VERSION "dbc-export 1 2026.26.6.5"

NS_ :

BS_:

BU_: ADSP APB APP APS APSB BB BMS CC CMP CMPD CP DAS DI DIF DIR DPB EPAS3P EPAS3S EPASTP EPASTS EPBL EPBR ESP EVSE FC GTW HCML HCMR HVP IBST ICR IDB LS OCS1P PARK PCS PCS2 PM PMF PMR PNCD PTC RADC RCM RCM2 RCM3 RCU SCCM SCM SCS SDCR TAS TCU TCU2 TPMS TRCM UI UIS UMC USM V2G VC VCBATT VCBATT0 VCBATT1 VCBATT2 VCCC VCFRONT VCFRONT1 VCFRONT2 VCLEFT VCRIGHT VCSEAT2L VCSEAT2R VCSEC VEH

BO_ 881 RCM_alertMatrix: 8 RCM
 SG_ RCM_matrixIndex M : 0|4@1+ (1,0) [0|15] "" Vector__XXX
 SG_ RCM_a000_crashDetected m0 : 4|1@1+ (1,0) [0|1] "" Vector__XXX
 SG_ RCM_a001_nearDeploy m0 : 5|1@1+ (1,0) [0|1] "" Vector__XXX
 SG_ RCM_a002_airbagsNotArmed m0 : 6|1@1+ (1,0) [0|1] "" Vector__XXX
 SG_ RCM_a003_warningIndicator m0 : 7|1@1+ (1,0) [0|1] "" Vector__XXX
 SG_ RCM_a004_internalFault m0 : 8|1@1+ (1,0) [0|1] "" Vector__XXX
 SG_ RCM_a005_crcError m0 : 9|1@1+ (1,0) [0|1] "" Vector__XXX
 SG_ RCM_a006_batteryVoltageRange m0 : 10|1@1+ (1,0) [0|1] "" Vector__XXX
 SG_ RCM_a007_powerSupplyExternal m0 : 11|1@1+ (1,0) [0|1] "" Vector__XXX
 SG_ RCM_a008_powerSupplyInternal m0 : 12|1@1+ (1,0) [0|1] "" Vector__XXX
 SG_ RCM_a009_reprogramLimit m0 : 13|1@1+ (1,0) [0|1] "" Vector__XXX
 SG_ RCM_a010_scmDisabled m0 : 14|1@1+ (1,0) [0|1] "" Vector__XXX
 SG_ RCM_a011_eepromDataLocked m0 : 15|1@1+ (1,0) [0|1] "" Vector__XXX
 SG_ RCM_a012_vinStorage m0 : 16|1@1+ (1,0) [0|1] "" Vector__XXX
 SG_ RCM_a013_driverOrientation m0 : 17|1@1+ (1,0) [0|1] "" Vector__XXX
 SG_ RCM_a014_driverABStage1 m0 : 18|1@1+ (1,0) [0|1] "" Vector__XXX
 SG_ RCM_a015_driverABStage2 m0 : 19|1@1+ (1,0) [0|1] "" Vector__XXX
 SG_ RCM_a016_passABStage1 m0 : 20|1@1+ (1,0) [0|1] "" Vector__XXX
 SG_ RCM_a017_passABStage2 m0 : 21|1@1+ (1,0) [0|1] "" Vector__XXX
 SG_ RCM_a018_passengerActiveVent m0 : 22|1@1+ (1,0) [0|1] "" Vector__XXX
 SG_ RCM_a019_pretenShldrFrontLeft m0 : 23|1@1+ (1,0) [0|1] "" Vector__XXX
 SG_ RCM_a020_pretenShldFrontRight m0 : 24|1@1+ (1,0) [0|1] "" Vector__XXX
 SG_ RCM_a021_pretenLapFrontLeft m0 : 25|1@1+ (1,0) [0|1] "" Vector__XXX
 SG_ RCM_a022_pretenLapFrontRight m0 : 26|1@1+ (1,0) [0|1] "" Vector__XXX
 SG_ RCM_a023_loadLimiterLeftSide m0 : 27|1@1+ (1,0) [0|1] "" Vector__XXX
 SG_ RCM_a024_loadLimiterRightSide m0 : 28|1@1+ (1,0) [0|1] "" Vector__XXX
 SG_ RCM_a025_kneeABDriver m0 : 29|1@1+ (1,0) [0|1] "" Vector__XXX
 SG_ RCM_a026_kneeABFrontPassenger m0 : 30|1@1+ (1,0) [0|1] "" Vector__XXX
 SG_ RCM_a027_sideAB1stRowLeft m0 : 31|1@1+ (1,0) [0|1] "" Vector__XXX
 SG_ RCM_a028_sideAB1stRowRight m0 : 32|1@1+ (1,0) [0|1] "" Vector__XXX
 SG_ RCM_a029_driverABActiveVent m0 : 33|1@1+ (1,0) [0|1] "" Vector__XXX
 SG_ RCM_a030_farSideInboardAirbag m0 : 34|1@1+ (1,0) [0|1] "" Vector__XXX
 SG_ RCM_a031_frontCenterAirbag m0 : 35|1@1+ (1,0) [0|1] "" Vector__XXX
 SG_ RCM_a032_curtainABLeft m0 : 36|1@1+ (1,0) [0|1] "" Vector__XXX
 SG_ RCM_a033_curtainABRight m0 : 37|1@1+ (1,0) [0|1] "" Vector__XXX
 SG_ RCM_a034_preten2ndRowLeft m0 : 38|1@1+ (1,0) [0|1] "" Vector__XXX
 SG_ RCM_a035_preten2ndRowRight m0 : 39|1@1+ (1,0) [0|1] "" Vector__XXX
 SG_ RCM_a036_curAB2ndRowLeft m0 : 40|1@1+ (1,0) [0|1] "" Vector__XXX
 SG_ RCM_a037_curAB2ndRowRight m0 : 41|1@1+ (1,0) [0|1] "" Vector__XXX
 SG_ RCM_a038_unusedA m0 : 42|1@1+ (1,0) [0|1] "" Vector__XXX
 SG_ RCM_a039_unusedB m0 : 43|1@1+ (1,0) [0|1] "" Vector__XXX
 SG_ RCM_a040_hoodActuatorRight m0 : 44|1@1+ (1,0) [0|1] "" Vector__XXX
 SG_ RCM_a041_hoodActuatorLeft m0 : 45|1@1+ (1,0) [0|1] "" Vector__XXX
 SG_ RCM_a042_ens1Line m0 : 46|1@1+ (1,0) [0|1] "" Vector__XXX
 SG_ RCM_a043_ens2Line m0 : 47|1@1+ (1,0) [0|1] "" Vector__XXX
 SG_ RCM_a044_upFrontSensorLeft m0 : 48|1@1+ (1,0) [0|1] "" Vector__XXX
 SG_ RCM_a045_upFrontSensorRight m0 : 49|1@1+ (1,0) [0|1] "" Vector__XXX
 SG_ RCM_a046_sideAccelBPillarLeft m0 : 50|1@1+ (1,0) [0|1] "" Vector__XXX
 SG_ RCM_a047_sideAccelBPillarRight m0 : 51|1@1+ (1,0) [0|1] "" Vector__XXX
 SG_ RCM_a048_sideAccelCPillarLeft m0 : 52|1@1+ (1,0) [0|1] "" Vector__XXX
 SG_ RCM_a049_sideAccelCPillarRight m0 : 53|1@1+ (1,0) [0|1] "" Vector__XXX
 SG_ RCM_a050_upFrontSensorCenter m0 : 54|1@1+ (1,0) [0|1] "" Vector__XXX
 SG_ RCM_a051_pressureFrontLftDoor m0 : 55|1@1+ (1,0) [0|1] "" Vector__XXX
 SG_ RCM_a052_pressureFrontRtDoor m0 : 56|1@1+ (1,0) [0|1] "" Vector__XXX
 SG_ RCM_a053_pressurePedProLeft m0 : 57|1@1+ (1,0) [0|1] "" Vector__XXX
 SG_ RCM_a054_pressurePedProRight m0 : 58|1@1+ (1,0) [0|1] "" Vector__XXX
 SG_ RCM_a055_inertialMeasurement m0 : 59|1@1+ (1,0) [0|1] "" Vector__XXX
 SG_ RCM_a056_passengerFrontOCS m0 : 60|1@1+ (1,0) [0|1] "" Vector__XXX
 SG_ RCM_a057_driverOCS m0 : 61|1@1+ (1,0) [0|1] "" Vector__XXX
 SG_ RCM_a058_buckle1stRowLeft m0 : 62|1@1+ (1,0) [0|1] "" Vector__XXX
 SG_ RCM_a059_buckle1stRowRight m0 : 63|1@1+ (1,0) [0|1] "" Vector__XXX
 SG_ RCM_a060_stpsLeft m1 : 4|1@1+ (1,0) [0|1] "" Vector__XXX
 SG_ RCM_a061_stpsRight m1 : 5|1@1+ (1,0) [0|1] "" Vector__XXX
 SG_ RCM_a062_alrSwitch m1 : 6|1@1+ (1,0) [0|1] "" Vector__XXX
 SG_ RCM_a063_sbsw2ndRowRight m1 : 7|1@1+ (1,0) [0|1] "" Vector__XXX
 SG_ RCM_a064_hardwareCodingPin1 m1 : 8|1@1+ (1,0) [0|1] "" Vector__XXX
 SG_ RCM_a065_driverOrientConfigPin m1 : 9|1@1+ (1,0) [0|1] "" Vector__XXX
 SG_ RCM_a066_seatBackSw2ndRowLeft m1 : 10|1@1+ (1,0) [0|1] "" Vector__XXX
 SG_ RCM_a067_comCANInitFailure m1 : 11|1@1+ (1,0) [0|1] "" Vector__XXX
 SG_ RCM_a068_comChassisBusOff m1 : 12|1@1+ (1,0) [0|1] "" Vector__XXX
 SG_ RCM_a069_comCHCANPH7 m1 : 13|1@1+ (1,0) [0|1] "" Vector__XXX
 SG_ RCM_a070_comCHCANPH8 m1 : 14|1@1+ (1,0) [0|1] "" Vector__XXX
 SG_ RCM_a071_comCHCANPH9 m1 : 15|1@1+ (1,0) [0|1] "" Vector__XXX
 SG_ RCM_a072_comUnused m1 : 16|1@1+ (1,0) [0|1] "" Vector__XXX
 SG_ RCM_a073_comCHCANPH4 m1 : 17|1@1+ (1,0) [0|1] "" Vector__XXX
 SG_ RCM_a074_comCHCANPH5 m1 : 18|1@1+ (1,0) [0|1] "" Vector__XXX
 SG_ RCM_a075_comCHCANPH6 m1 : 19|1@1+ (1,0) [0|1] "" Vector__XXX
 SG_ RCM_a076_comEPBLStatus m1 : 20|1@1+ (1,0) [0|1] "" Vector__XXX
 SG_ RCM_a077_comEPBRStatus m1 : 21|1@1+ (1,0) [0|1] "" Vector__XXX
 SG_ RCM_a078_comOCS1PStatus m1 : 22|1@1+ (1,0) [0|1] "" Vector__XXX
 SG_ RCM_a079_comOCS1DStatus m1 : 23|1@1+ (1,0) [0|1] "" Vector__XXX
 SG_ RCM_a080_comGTWACS m1 : 24|1@1+ (1,0) [0|1] "" Vector__XXX
 SG_ RCM_a081_comVCFRONTLVPwr m1 : 25|1@1+ (1,0) [0|1] "" Vector__XXX
 SG_ RCM_a082_comUIodo m1 : 26|1@1+ (1,0) [0|1] "" Vector__XXX
 SG_ RCM_a083_comGTWCarState m1 : 27|1@1+ (1,0) [0|1] "" Vector__XXX
 SG_ RCM_a084_comTPMSStatus m1 : 28|1@1+ (1,0) [0|1] "" Vector__XXX
 SG_ RCM_a085_comGTWCarConfig m1 : 29|1@1+ (1,0) [0|1] "" Vector__XXX
 SG_ RCM_a086_comVINMIA m1 : 30|1@1+ (1,0) [0|1] "" Vector__XXX
 SG_ RCM_a087_comCANSilent m1 : 31|1@1+ (1,0) [0|1] "" Vector__XXX
 SG_ RCM_a088_comCHCANPH2 m1 : 32|1@1+ (1,0) [0|1] "" Vector__XXX
 SG_ RCM_a089_comCHCANPH3 m1 : 33|1@1+ (1,0) [0|1] "" Vector__XXX
 SG_ RCM_a090_comPartyBusOff m1 : 34|1@1+ (1,0) [0|1] "" Vector__XXX
 SG_ RCM_a091_comEPAS3PsysStatus m1 : 35|1@1+ (1,0) [0|1] "" Vector__XXX
 SG_ RCM_a092_comDASISF m1 : 36|1@1+ (1,0) [0|1] "" Vector__XXX
 SG_ RCM_a093_comVCLEFTStatus m1 : 37|1@1+ (1,0) [0|1] "" Vector__XXX
 SG_ RCM_a094_comVCRIGHTStatus m1 : 38|1@1+ (1,0) [0|1] "" Vector__XXX
 SG_ RCM_a095_comESPstatus m1 : 39|1@1+ (1,0) [0|1] "" Vector__XXX
 SG_ RCM_a096_comESPwheelSpeeds m1 : 40|1@1+ (1,0) [0|1] "" Vector__XXX
 SG_ RCM_a097_comDIspeed m1 : 41|1@1+ (1,0) [0|1] "" Vector__XXX
 SG_ RCM_a098_comDIchassisControl m1 : 42|1@1+ (1,0) [0|1] "" Vector__XXX
 SG_ RCM_a099_comDItorque m1 : 43|1@1+ (1,0) [0|1] "" Vector__XXX
 SG_ RCM_a100_comDIsystemStatus m1 : 44|1@1+ (1,0) [0|1] "" Vector__XXX
 SG_ RCM_a101_idfSystem m1 : 45|1@1+ (1,0) [0|1] "" Vector__XXX
 SG_ RCM_a102_imuYawR8OffstCompLim m1 : 46|1@1+ (1,0) [0|1] "" Vector__XXX
 SG_ RCM_a103_imuPtchR8OffstCompLim m1 : 47|1@1+ (1,0) [0|1] "" Vector__XXX
 SG_ RCM_a104_imuRollR8OffstCompLim m1 : 48|1@1+ (1,0) [0|1] "" Vector__XXX
 SG_ RCM_a105_imuLongAccOffstCompLim m1 : 49|1@1+ (1,0) [0|1] "" Vector__XXX
 SG_ RCM_a106_imuLatAccOffstCompLim m1 : 50|1@1+ (1,0) [0|1] "" Vector__XXX
 SG_ RCM_a107_imuVertAccOffstCompLim m1 : 51|1@1+ (1,0) [0|1] "" Vector__XXX
 SG_ RCM_a108_crashAlgoWakeup m1 : 52|1@1+ (1,0) [0|1] "" Vector__XXX
 SG_ RCM_a109_abuseImmunity m1 : 53|1@1+ (1,0) [0|1] "" Vector__XXX
 SG_ RCM_a110_factoryMode m1 : 54|1@1+ (1,0) [0|1] "" Vector__XXX
 SG_ RCM_a111_diagnosticsEnabled m1 : 55|1@1+ (1,0) [0|1] "" Vector__XXX
 SG_ RCM_a112_imuYawRate m1 : 56|1@1+ (1,0) [0|1] "" Vector__XXX
 SG_ RCM_a113_imuPitchRate m1 : 57|1@1+ (1,0) [0|1] "" Vector__XXX
 SG_ RCM_a114_imuRollRate m1 : 58|1@1+ (1,0) [0|1] "" Vector__XXX
 SG_ RCM_a115_imuLinearAcceleration m1 : 59|1@1+ (1,0) [0|1] "" Vector__XXX
 SG_ RCM_a116_imuLateralAcceleration m1 : 60|1@1+ (1,0) [0|1] "" Vector__XXX
 SG_ RCM_a117_imuVerticalAcceleration m1 : 61|1@1+ (1,0) [0|1] "" Vector__XXX
 SG_ RCM_a118_imuInPlaneAcceleration m1 : 62|1@1+ (1,0) [0|1] "" Vector__XXX

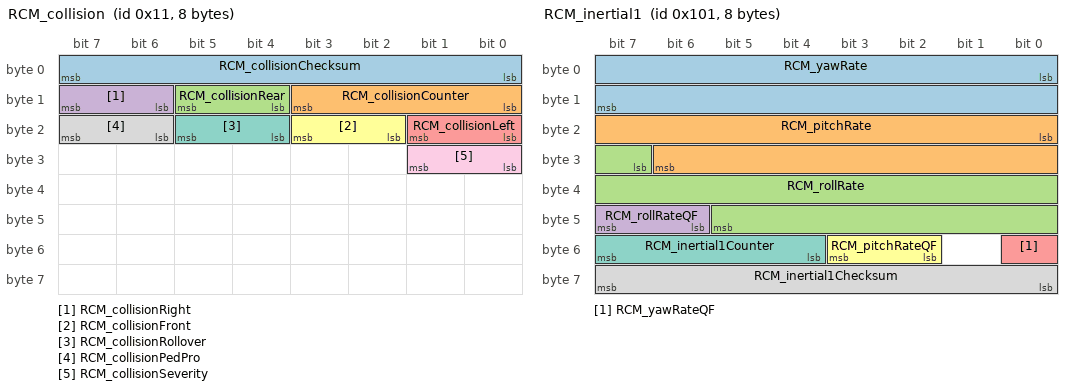
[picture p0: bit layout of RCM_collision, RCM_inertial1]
BO_ 17 RCM_collision: 8 RCM
 SG_ RCM_collisionChecksum : 0|8@1+ (1,0) [0|255] "" Vector__XXX
 SG_ RCM_collisionCounter : 8|4@1+ (1,0) [0|15] "" Vector__XXX
 SG_ RCM_collisionRear : 12|2@1+ (1,0) [0|3] "" Vector__XXX
 SG_ RCM_collisionRight : 14|2@1+ (1,0) [0|3] "" Vector__XXX
 SG_ RCM_collisionLeft : 16|2@1+ (1,0) [0|3] "" Vector__XXX
 SG_ RCM_collisionFront : 18|2@1+ (1,0) [0|3] "" Vector__XXX
 SG_ RCM_collisionRollover : 20|2@1+ (1,0) [0|3] "" Vector__XXX
 SG_ RCM_collisionPedPro : 22|2@1+ (1,0) [0|3] "" Vector__XXX
 SG_ RCM_collisionSeverity : 24|2@1+ (1,0) [0|3] "" Vector__XXX

BO_ 257 RCM_inertial1: 8 RCM
 SG_ RCM_yawRate : 0|16@1- (0.0001,0) [-3.2766|3.2766] "rad/s" Vector__XXX
 SG_ RCM_pitchRate : 16|15@1- (0.00025,0) [-4.096|4.09575] "rad/s" Vector__XXX
 SG_ RCM_rollRate : 31|15@1- (0.00025,0) [-4.096|4.09575] "rad/s" Vector__XXX
 SG_ RCM_rollRateQF : 46|2@1+ (1,0) [0|3] "" Vector__XXX
 SG_ RCM_yawRateQF : 48|1@1+ (1,0) [0|1] "" Vector__XXX
 SG_ RCM_pitchRateQF : 50|2@1+ (1,0) [0|3] "" Vector__XXX
 SG_ RCM_inertial1Counter : 52|4@1+ (1,0) [0|15] "" Vector__XXX
 SG_ RCM_inertial1Checksum : 56|8@1+ (1,0) [0|255] "" Vector__XXX

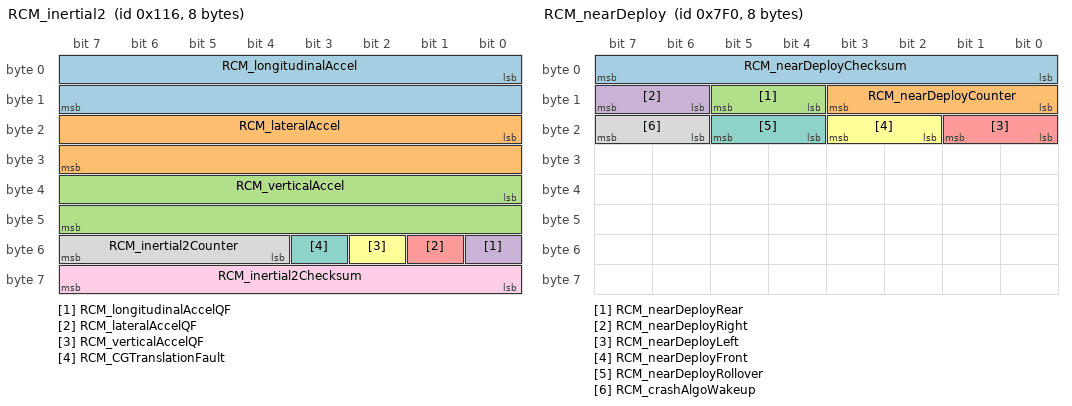
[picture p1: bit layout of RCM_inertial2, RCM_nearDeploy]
BO_ 278 RCM_inertial2: 8 RCM
 SG_ RCM_longitudinalAccel : 0|16@1- (0.00125,0) [-40.9575|40.9575] "m/s^2" Vector__XXX
 SG_ RCM_lateralAccel : 16|16@1- (0.00125,0) [-40.9575|40.9575] "m/s^2" Vector__XXX
 SG_ RCM_verticalAccel : 32|16@1- (0.00125,0) [-40.9575|39.2] "m/s^2" Vector__XXX
 SG_ RCM_longitudinalAccelQF : 48|1@1+ (1,0) [0|1] "" Vector__XXX
 SG_ RCM_lateralAccelQF : 49|1@1+ (1,0) [0|1] "" Vector__XXX
 SG_ RCM_verticalAccelQF : 50|1@1+ (1,0) [0|1] "" Vector__XXX
 SG_ RCM_CGTranslationFault : 51|1@1+ (1,0) [0|1] "" Vector__XXX
 SG_ RCM_inertial2Counter : 52|4@1+ (1,0) [0|15] "" Vector__XXX
 SG_ RCM_inertial2Checksum : 56|8@1+ (1,0) [0|255] "" Vector__XXX

BO_ 849 RCM_info: 8 RCM
 SG_ RCM_infoIndex M : 0|8@1+ (1,0) [0|255] "" Vector__XXX
 SG_ RCM_infoBuildType m10 : 8|8@1+ (1,0) [0|255] "" Vector__XXX
 SG_ RCM_infoComponentID m10 : 48|16@1+ (1,0) [0|65535] "" Vector__XXX
 SG_ RCM_infoPcbaID m11 : 16|8@1+ (1,0) [0|255] "" Vector__XXX
 SG_ RCM_infoAssemblyID m11 : 24|8@1+ (1,0) [0|255] "" Vector__XXX
 SG_ RCM_infoUsageID m11 : 32|16@1+ (1,0) [0|65535] "" Vector__XXX
 SG_ RCM_infoApplicationCRC m13 : 32|32@1+ (1,0) [0|4294967295] "" Vector__XXX
 SG_ RCM_infoBootUdsProtoVersion m20 : 8|8@1+ (1,0) [0|255] "" Vector__XXX
 SG_ RCM_infoBootloaderCRC m20 : 32|32@1+ (1,0) [0|4294967295] "" Vector__XXX
 SG_ RCM_infoAlgoCalID m22 : 8|8@1+ (1,0) [0|255] "" Vector__XXX
 SG_ RCM_infoVariantCRC m22 : 32|32@1+ (1,0) [0|4294967295] "" Vector__XXX

BO_ 2032 RCM_nearDeploy: 8 RCM
 SG_ RCM_nearDeployChecksum : 0|8@1+ (1,0) [0|255] "" Vector__XXX
 SG_ RCM_nearDeployCounter : 8|4@1+ (1,0) [0|15] "" Vector__XXX
 SG_ RCM_nearDeployRear : 12|2@1+ (1,0) [0|3] "" Vector__XXX
 SG_ RCM_nearDeployRight : 14|2@1+ (1,0) [0|3] "" Vector__XXX
 SG_ RCM_nearDeployLeft : 16|2@1+ (1,0) [0|3] "" Vector__XXX
 SG_ RCM_nearDeployFront : 18|2@1+ (1,0) [0|3] "" Vector__XXX
 SG_ RCM_nearDeployRollover : 20|2@1+ (1,0) [0|3] "" Vector__XXX
 SG_ RCM_crashAlgoWakeup : 22|2@1+ (1,0) [0|3] "" Vector__XXX

BO_ 529 RCM_status: 8 RCM
 SG_ RCM_statusChecksum : 0|8@1+ (1,0) [0|255] "" Vector__XXX
 SG_ RCM_statusCounter : 8|4@1+ (1,0) [0|15] "" Vector__XXX
 SG_ RCM_armStatus : 12|2@1+ (1,0) [0|3] "" Vector__XXX
 SG_ RCM_warningIndicatorState : 14|2@1+ (1,0) [0|3] "" Vector__XXX
 SG_ RCM_passAirbagIndicatorRequest : 16|2@1+ (1,0) [0|3] "" Vector__XXX
 SG_ RCM_airbagCutoffStatus : 18|2@1+ (1,0) [0|3] "" Vector__XXX
 SG_ RCM_alrSwitchStatus : 20|2@1+ (1,0) [0|3] "" Vector__XXX
 SG_ RCM_vinLearnFlag : 22|2@1+ (1,0) [0|3] "" Vector__XXX
 SG_ RCM_seatTrackPositionDrvr : 24|2@1+ (1,0) [0|3] "" Vector__XXX
 SG_ RCM_seatTrackPositionPass : 26|2@1+ (1,0) [0|3] "" Vector__XXX
 SG_ RCM_edr1State : 28|2@1+ (1,0) [0|3] "" Vector__XXX
 SG_ RCM_edr2State : 30|2@1+ (1,0) [0|3] "" Vector__XXX
 SG_ RCM_keepPowerReason : 32|4@1+ (1,0) [0|15] "" Vector__XXX
 SG_ RCM_imuOffsetLearnState : 36|2@1+ (1,0) [0|3] "" Vector__XXX
 SG_ RCM_edr3State : 38|2@1+ (1,0) [0|3] "" Vector__XXX
 SG_ RCM_driverOrientationInitStatus : 40|3@1+ (1,0) [0|7] "" Vector__XXX
 SG_ RCM_occupantClassificationSource : 43|1@1+ (1,0) [0|1] "" Vector__XXX
 SG_ RCM_pedProEDR1State : 44|2@1+ (1,0) [0|3] "" Vector__XXX
 SG_ RCM_pedProEDR2State : 46|2@1+ (1,0) [0|3] "" Vector__XXX

BO_ 1471 RCU_alertLog: 8 RCU
 SG_ RCU_alertID M : 0|7@1+ (1,0) [0|127] "" Vector__XXX
 SG_ RCU_alertState : 15|1@1+ (1,0) [0|1] "" Vector__XXX
 SG_ RCU_a010_sensorPowerSupply m10 : 16|1@1+ (1,0) [0|1] "" Vector__XXX
 SG_ RCU_a010_sensorHardware m10 : 17|1@1+ (1,0) [0|1] "" Vector__XXX
 SG_ RCU_a010_sensorSignal m10 : 18|1@1+ (1,0) [0|1] "" Vector__XXX
 SG_ RCU_a023_validityOnChassisBus m23 : 16|1@1+ (1,0) [0|1] "" Vector__XXX
 SG_ RCU_a023_validityOnPartyBus m23 : 17|1@1+ (1,0) [0|1] "" Vector__XXX
 SG_ RCU_a024_validityOnChassisBus m24 : 16|1@1+ (1,0) [0|1] "" Vector__XXX
 SG_ RCU_a024_validityOnPartyBus m24 : 17|1@1+ (1,0) [0|1] "" Vector__XXX
 SG_ RCU_a025_validityOnChassisBus m25 : 16|1@1+ (1,0) [0|1] "" Vector__XXX
 SG_ RCU_a025_validityOnPartyBus m25 : 17|1@1+ (1,0) [0|1] "" Vector__XXX
 SG_ RCU_a035_validityOnChassisBus m35 : 16|1@1+ (1,0) [0|1] "" Vector__XXX
 SG_ RCU_a035_validityOnPartyBus m35 : 17|1@1+ (1,0) [0|1] "" Vector__XXX
 SG_ RCU_a036_validityOnChassisBus m36 : 16|1@1+ (1,0) [0|1] "" Vector__XXX
 SG_ RCU_a036_validityOnPartyBus m36 : 17|1@1+ (1,0) [0|1] "" Vector__XXX

BO_ 998 RCU_alertMatrix: 8 RCU
 SG_ RCU_matrixIndex M : 0|4@1+ (1,0) [0|15] "" Vector__XXX
 SG_ RCU_a001_valveDriverFault m0 : 4|1@1+ (1,0) [0|1] "" Vector__XXX
 SG_ RCU_a002_solenoidValveFault m0 : 5|1@1+ (1,0) [0|1] "" Vector__XXX
 SG_ RCU_a003_pumpMotorFault m0 : 6|1@1+ (1,0) [0|1] "" Vector__XXX
 SG_ RCU_a004_supplyOvervoltage m0 : 7|1@1+ (1,0) [0|1] "" Vector__XXX
 SG_ RCU_a005_supplyUndervoltage m0 : 8|1@1+ (1,0) [0|1] "" Vector__XXX
 SG_ RCU_a006_wakeLineOpen m0 : 9|1@1+ (1,0) [0|1] "" Vector__XXX
 SG_ RCU_a007_pressureSensorFault m0 : 10|1@1+ (1,0) [0|1] "" Vector__XXX
 SG_ RCU_a008_pressureNotCalibrated m0 : 11|1@1+ (1,0) [0|1] "" Vector__XXX
 SG_ RCU_a009_brakeFluidLow m0 : 12|1@1+ (1,0) [0|1] "" Vector__XXX
 SG_ RCU_a010_pedalSensorFault m0 : 13|1@1+ (1,0) [0|1] "" Vector__XXX
 SG_ RCU_a011_idbPedalTravelMismatch m0 : 14|1@1+ (1,0) [0|1] "" Vector__XXX
 SG_ RCU_a012_pedalSensorNotCal m0 : 15|1@1+ (1,0) [0|1] "" Vector__XXX
 SG_ RCU_a013_mcuGenericFault m0 : 16|1@1+ (1,0) [0|1] "" Vector__XXX
 SG_ RCU_a014_asicTempHigh m0 : 17|1@1+ (1,0) [0|1] "" Vector__XXX
 SG_ RCU_a015_fluidLeakDetected m0 : 18|1@1+ (1,0) [0|1] "" Vector__XXX
 SG_ RCU_a016_partyBusOff m0 : 19|1@1+ (1,0) [0|1] "" Vector__XXX
 SG_ RCU_a017_chassisBusOff m0 : 20|1@1+ (1,0) [0|1] "" Vector__XXX
 SG_ RCU_a018_DItorquePathFaulted m0 : 21|1@1+ (1,0) [0|1] "" Vector__XXX
 SG_ RCU_a019_DItorquePathActive m0 : 22|1@1+ (1,0) [0|1] "" Vector__XXX
 SG_ RCU_a020_BBstatusDLC m0 : 23|1@1+ (1,0) [0|1] "" Vector__XXX
 SG_ RCU_a021_BBstatusChecksum m0 : 24|1@1+ (1,0) [0|1] "" Vector__XXX
 SG_ RCU_a022_BBstatusCounter m0 : 25|1@1+ (1,0) [0|1] "" Vector__XXX
 SG_ RCU_a023_IDBstatusDLC m0 : 26|1@1+ (1,0) [0|1] "" Vector__XXX
 SG_ RCU_a024_IDBstatusChecksum m0 : 27|1@1+ (1,0) [0|1] "" Vector__XXX
 SG_ RCU_a025_IDBstatusCounter m0 : 28|1@1+ (1,0) [0|1] "" Vector__XXX
 SG_ RCU_a026_DIchassisControlDLC m0 : 29|1@1+ (1,0) [0|1] "" Vector__XXX
 SG_ RCU_a027_DIchassisCtrlChecksum m0 : 30|1@1+ (1,0) [0|1] "" Vector__XXX
 SG_ RCU_a028_DIchassisControlCounter m0 : 31|1@1+ (1,0) [0|1] "" Vector__XXX
 SG_ RCU_a029_PMstate2DLC m0 : 32|1@1+ (1,0) [0|1] "" Vector__XXX
 SG_ RCU_a030_PMstate2Checksum m0 : 33|1@1+ (1,0) [0|1] "" Vector__XXX
 SG_ RCU_a031_PMstate2Counter m0 : 34|1@1+ (1,0) [0|1] "" Vector__XXX
 SG_ RCU_a032_VCFRONTLVPowerStateDLC m0 : 35|1@1+ (1,0) [0|1] "" Vector__XXX
 SG_ RCU_a033_VCFRONTLVPowerStateChec m0 : 36|1@1+ (1,0) [0|1] "" Vector__XXX
 SG_ RCU_a034_VCFRONTLVPowerStateCoun m0 : 37|1@1+ (1,0) [0|1] "" Vector__XXX
 SG_ RCU_a035_IDBpcpInvalid m0 : 38|1@1+ (1,0) [0|1] "" Vector__XXX
 SG_ RCU_a036_IDBpspInvalid m0 : 39|1@1+ (1,0) [0|1] "" Vector__XXX
 SG_ RCU_a037_IDBinputRodStrokeInvali m0 : 40|1@1+ (1,0) [0|1] "" Vector__XXX
 SG_ RCU_a038_DIsystemStatusDLC m0 : 41|1@1+ (1,0) [0|1] "" Vector__XXX
 SG_ RCU_a039_DIaccelPosInvalid m0 : 42|1@1+ (1,0) [0|1] "" Vector__XXX
 SG_ RCU_a040_DIgearInvalid m0 : 43|1@1+ (1,0) [0|1] "" Vector__XXX
 SG_ RCU_a041_DIsystemStatusCounter m0 : 44|1@1+ (1,0) [0|1] "" Vector__XXX
 SG_ RCU_a042_DIsystemStatusChecksum m0 : 45|1@1+ (1,0) [0|1] "" Vector__XXX
 SG_ RCU_a043_VCFRONTiBoosterLvStateI m0 : 46|1@1+ (1,0) [0|1] "" Vector__XXX
 SG_ RCU_a044_VCFRONTsensorsMIA m0 : 47|1@1+ (1,0) [0|1] "" Vector__XXX
 SG_ RCU_a045_VCFRONTtempInvalid m0 : 48|1@1+ (1,0) [0|1] "" Vector__XXX
 SG_ RCU_a046_brakeFluidLevelSNA m0 : 49|1@1+ (1,0) [0|1] "" Vector__XXX
 SG_ RCU_a047_ESPwheelSpeedsDLC m0 : 50|1@1+ (1,0) [0|1] "" Vector__XXX
 SG_ RCU_a048_ESPFrLWSSLInvalid m0 : 51|1@1+ (1,0) [0|1] "" Vector__XXX
 SG_ RCU_a049_ESPFrRWSSLInvalid m0 : 52|1@1+ (1,0) [0|1] "" Vector__XXX
 SG_ RCU_a050_ESPReLWSSLInvalid m0 : 53|1@1+ (1,0) [0|1] "" Vector__XXX
 SG_ RCU_a051_ESPReRWSSLInvalid m0 : 54|1@1+ (1,0) [0|1] "" Vector__XXX
 SG_ RCU_a052_ESPwheelSpeedsCounter m0 : 55|1@1+ (1,0) [0|1] "" Vector__XXX
 SG_ RCU_a053_ESPwheelSpeedsChecksum m0 : 56|1@1+ (1,0) [0|1] "" Vector__XXX
 SG_ RCU_a054_IDBcircuitPressFaulted m0 : 57|1@1+ (1,0) [0|1] "" Vector__XXX
 SG_ RCU_a055_IDBsimulatorPressFaulte m0 : 58|1@1+ (1,0) [0|1] "" Vector__XXX
 SG_ RCU_a056_redundantControllerIsMa m0 : 59|1@1+ (1,0) [0|1] "" Vector__XXX
 SG_ RCU_a057_DASredundantBrakingCont m0 : 60|1@1+ (1,0) [0|1] "" Vector__XXX
 SG_ RCU_a058_DASredundantBrakingCont m0 : 61|1@1+ (1,0) [0|1] "" Vector__XXX
 SG_ RCU_a059_DASredundantBrakingCont m0 : 62|1@1+ (1,0) [0|1] "" Vector__XXX
 SG_ RCU_a060_DASbrakeTorqueCommandIn m0 : 63|1@1+ (1,0) [0|1] "" Vector__XXX
 SG_ RCU_a061_DIlocStatus2DLC m1 : 4|1@1+ (1,0) [0|1] "" Vector__XXX
 SG_ RCU_a062_DIlocStatus2Counter m1 : 5|1@1+ (1,0) [0|1] "" Vector__XXX
 SG_ RCU_a063_DIlocStatus2Checksum m1 : 6|1@1+ (1,0) [0|1] "" Vector__XXX
 SG_ RCU_a064_ESPredundantBrakingStat m1 : 7|1@1+ (1,0) [0|1] "" Vector__XXX
 SG_ RCU_a065_ESPredundantBrakingStat m1 : 8|1@1+ (1,0) [0|1] "" Vector__XXX
 SG_ RCU_a066_ESPredundantBrakingStat m1 : 9|1@1+ (1,0) [0|1] "" Vector__XXX

BO_ 831 RCU_info: 8 RCU
 SG_ RCU_infoIndex M : 0|8@1+ (1,0) [0|255] "" Vector__XXX
 SG_ RCU_infoPcbaID m11 : 16|8@1+ (1,0) [0|255] "" Vector__XXX
 SG_ RCU_infoAssemblyID m11 : 24|8@1+ (1,0) [0|255] "" Vector__XXX
 SG_ RCU_infoUsageID m11 : 32|16@1+ (1,0) [0|65535] "" Vector__XXX
 SG_ RCU_infoSubUsageID m11 : 48|16@1+ (1,0) [0|65535] "" Vector__XXX

BO_ 1344 SCCM_alertLog: 8 SCCM
 SG_ SCCM_alertID M : 0|15@1+ (1,0) [0|32767] "" Vector__XXX
 SG_ SCCM_alertState : 15|1@1+ (1,0) [0|1] "" Vector__XXX
 SG_ SCCM_a003_debouncePosition m3 : 16|8@1+ (1,0) [0|255] "" Vector__XXX
 SG_ SCCM_a003_rawPosition m3 : 24|8@1+ (1,0) [0|255] "" Vector__XXX
 SG_ SCCM_a003_errorPosition m3 : 32|8@1+ (1,0) [0|255] "" Vector__XXX
 SG_ SCCM_a003_adcValue m3 : 40|8@1+ (1,0) [0|255] "" Vector__XXX
 SG_ SCCM_a004_debouncePosition m4 : 16|8@1+ (1,0) [0|255] "" Vector__XXX
 SG_ SCCM_a004_rawPosition m4 : 24|8@1+ (1,0) [0|255] "" Vector__XXX
 SG_ SCCM_a004_errorPosition m4 : 32|8@1+ (1,0) [0|255] "" Vector__XXX
 SG_ SCCM_a004_adcValue m4 : 40|8@1+ (1,0) [0|255] "" Vector__XXX
 SG_ SCCM_a005_debouncePosition m5 : 16|8@1+ (1,0) [0|255] "" Vector__XXX
 SG_ SCCM_a005_rawPosition m5 : 24|8@1+ (1,0) [0|255] "" Vector__XXX
 SG_ SCCM_a005_errorPosition m5 : 32|8@1+ (1,0) [0|255] "" Vector__XXX
 SG_ SCCM_a005_adcValue m5 : 40|8@1+ (1,0) [0|255] "" Vector__XXX
 SG_ SCCM_a006_debouncePosition m6 : 16|8@1+ (1,0) [0|255] "" Vector__XXX
 SG_ SCCM_a006_rawPosition m6 : 24|8@1+ (1,0) [0|255] "" Vector__XXX
 SG_ SCCM_a006_errorPosition m6 : 32|8@1+ (1,0) [0|255] "" Vector__XXX
 SG_ SCCM_a006_adcValue m6 : 40|8@1+ (1,0) [0|255] "" Vector__XXX
 SG_ SCCM_a008_debouncePosition m8 : 16|8@1+ (1,0) [0|255] "" Vector__XXX
 SG_ SCCM_a008_rawPosition m8 : 24|8@1+ (1,0) [0|255] "" Vector__XXX
 SG_ SCCM_a008_errorPosition m8 : 32|8@1+ (1,0) [0|255] "" Vector__XXX
 SG_ SCCM_a008_adcValue1 m8 : 40|8@1+ (1,0) [0|255] "" Vector__XXX
 SG_ SCCM_a008_adcValue2 m8 : 48|8@1+ (1,0) [0|255] "" Vector__XXX
 SG_ SCCM_a009_debouncePosition m9 : 16|8@1+ (1,0) [0|255] "" Vector__XXX
 SG_ SCCM_a009_rawPosition m9 : 24|8@1+ (1,0) [0|255] "" Vector__XXX
 SG_ SCCM_a009_errorPosition m9 : 32|8@1+ (1,0) [0|255] "" Vector__XXX
 SG_ SCCM_a009_adcValue1 m9 : 40|8@1+ (1,0) [0|255] "" Vector__XXX
 SG_ SCCM_a009_adcValue2 m9 : 48|8@1+ (1,0) [0|255] "" Vector__XXX
 SG_ SCCM_a010_debouncePosition m10 : 16|8@1+ (1,0) [0|255] "" Vector__XXX
 SG_ SCCM_a010_rawPosition m10 : 24|8@1+ (1,0) [0|255] "" Vector__XXX
 SG_ SCCM_a010_errorPosition m10 : 32|8@1+ (1,0) [0|255] "" Vector__XXX
 SG_ SCCM_a010_adcValue1 m10 : 40|8@1+ (1,0) [0|255] "" Vector__XXX
 SG_ SCCM_a010_adcValue2 m10 : 48|8@1+ (1,0) [0|255] "" Vector__XXX
 SG_ SCCM_a011_debouncePosition m11 : 16|8@1+ (1,0) [0|255] "" Vector__XXX
 SG_ SCCM_a011_rawPosition m11 : 24|8@1+ (1,0) [0|255] "" Vector__XXX
 SG_ SCCM_a011_errorPosition m11 : 32|8@1+ (1,0) [0|255] "" Vector__XXX
 SG_ SCCM_a011_adcValue1 m11 : 40|8@1+ (1,0) [0|255] "" Vector__XXX
 SG_ SCCM_a011_adcValue2 m11 : 48|8@1+ (1,0) [0|255] "" Vector__XXX
 SG_ SCCM_a012_debouncePosition m12 : 16|8@1+ (1,0) [0|255] "" Vector__XXX
 SG_ SCCM_a012_rawPosition m12 : 24|8@1+ (1,0) [0|255] "" Vector__XXX
 SG_ SCCM_a012_errorPosition m12 : 32|8@1+ (1,0) [0|255] "" Vector__XXX
 SG_ SCCM_a012_adcValue1 m12 : 40|8@1+ (1,0) [0|255] "" Vector__XXX
 SG_ SCCM_a012_adcValue2 m12 : 48|8@1+ (1,0) [0|255] "" Vector__XXX
 SG_ SCCM_a021_adcValue1 m21 : 16|8@1+ (1,0) [0|255] "" Vector__XXX
 SG_ SCCM_a021_adcValue2 m21 : 24|8@1+ (1,0) [0|255] "" Vector__XXX
 SG_ SCCM_a021_adcValue3 m21 : 32|8@1+ (1,0) [0|255] "" Vector__XXX
 SG_ SCCM_a021_adcValue4 m21 : 40|8@1+ (1,0) [0|255] "" Vector__XXX
 SG_ SCCM_a021_adcValue5 m21 : 48|8@1+ (1,0) [0|255] "" Vector__XXX
 SG_ SCCM_a021_adcValue6 m21 : 56|8@1+ (1,0) [0|255] "" Vector__XXX
 SG_ SCCM_a022_adcValue1 m22 : 16|8@1+ (1,0) [0|255] "" Vector__XXX
 SG_ SCCM_a022_adcValue2 m22 : 24|8@1+ (1,0) [0|255] "" Vector__XXX
 SG_ SCCM_a022_adcValue3 m22 : 32|8@1+ (1,0) [0|255] "" Vector__XXX
 SG_ SCCM_a022_adcValue4 m22 : 40|8@1+ (1,0) [0|255] "" Vector__XXX
 SG_ SCCM_a022_adcValue5 m22 : 48|8@1+ (1,0) [0|255] "" Vector__XXX
 SG_ SCCM_a022_adcValue6 m22 : 56|8@1+ (1,0) [0|255] "" Vector__XXX
 SG_ SCCM_a023_adcValue1 m23 : 16|8@1+ (1,0) [0|255] "" Vector__XXX
 SG_ SCCM_a023_adcValue2 m23 : 24|8@1+ (1,0) [0|255] "" Vector__XXX
 SG_ SCCM_a023_adcValue3 m23 : 32|8@1+ (1,0) [0|255] "" Vector__XXX
 SG_ SCCM_a023_adcValue4 m23 : 40|8@1+ (1,0) [0|255] "" Vector__XXX
 SG_ SCCM_a023_adcValue5 m23 : 48|8@1+ (1,0) [0|255] "" Vector__XXX
 SG_ SCCM_a023_adcValue6 m23 : 56|8@1+ (1,0) [0|255] "" Vector__XXX
 SG_ SCCM_a024_adcValue1 m24 : 16|8@1+ (1,0) [0|255] "" Vector__XXX
 SG_ SCCM_a024_adcValue2 m24 : 24|8@1+ (1,0) [0|255] "" Vector__XXX
 SG_ SCCM_a024_adcValue3 m24 : 32|8@1+ (1,0) [0|255] "" Vector__XXX
 SG_ SCCM_a024_adcValue4 m24 : 40|8@1+ (1,0) [0|255] "" Vector__XXX
 SG_ SCCM_a024_adcValue5 m24 : 48|8@1+ (1,0) [0|255] "" Vector__XXX
 SG_ SCCM_a024_adcValue6 m24 : 56|8@1+ (1,0) [0|255] "" Vector__XXX
 SG_ SCCM_a026_debouncePosition m26 : 16|8@1+ (1,0) [0|255] "" Vector__XXX
 SG_ SCCM_a026_rawPosition m26 : 24|8@1+ (1,0) [0|255] "" Vector__XXX
 SG_ SCCM_a026_errorPosition m26 : 32|8@1+ (1,0) [0|255] "" Vector__XXX
 SG_ SCCM_a026_adcValue1 m26 : 40|8@1+ (1,0) [0|255] "" Vector__XXX
 SG_ SCCM_a026_adcValue2 m26 : 48|8@1+ (1,0) [0|255] "" Vector__XXX
 SG_ SCCM_a027_debouncePosition m27 : 16|8@1+ (1,0) [0|255] "" Vector__XXX
 SG_ SCCM_a027_rawPosition m27 : 24|8@1+ (1,0) [0|255] "" Vector__XXX
 SG_ SCCM_a027_errorPosition m27 : 32|8@1+ (1,0) [0|255] "" Vector__XXX
 SG_ SCCM_a027_adcValue1 m27 : 40|8@1+ (1,0) [0|255] "" Vector__XXX
 SG_ SCCM_a027_adcValue2 m27 : 48|8@1+ (1,0) [0|255] "" Vector__XXX
 SG_ SCCM_a028_debouncePosition m28 : 16|8@1+ (1,0) [0|255] "" Vector__XXX
 SG_ SCCM_a028_rawPosition m28 : 24|8@1+ (1,0) [0|255] "" Vector__XXX
 SG_ SCCM_a028_errorPosition m28 : 32|8@1+ (1,0) [0|255] "" Vector__XXX
 SG_ SCCM_a028_adcValue1 m28 : 40|8@1+ (1,0) [0|255] "" Vector__XXX
 SG_ SCCM_a028_adcValue2 m28 : 48|8@1+ (1,0) [0|255] "" Vector__XXX
 SG_ SCCM_a029_debouncePosition m29 : 16|8@1+ (1,0) [0|255] "" Vector__XXX
 SG_ SCCM_a029_rawPosition m29 : 24|8@1+ (1,0) [0|255] "" Vector__XXX
 SG_ SCCM_a029_errorPosition m29 : 32|8@1+ (1,0) [0|255] "" Vector__XXX
 SG_ SCCM_a029_adcValue1 m29 : 40|8@1+ (1,0) [0|255] "" Vector__XXX
 SG_ SCCM_a029_adcValue2 m29 : 48|8@1+ (1,0) [0|255] "" Vector__XXX
 SG_ SCCM_a061_voltage m61 : 16|8@1+ (0.1,0) [0|25.5] "" Vector__XXX
 SG_ SCCM_a062_voltage m62 : 16|8@1+ (0.1,0) [0|25.5] "" Vector__XXX
 SG_ SCCM_a063_UntrimmedAngle m63 : 16|16@1+ (0.1,-819.2) [-819.2|5734.3] "" Vector__XXX
 SG_ SCCM_a064_Speed m64 : 16|16@1+ (0.5,-4096) [-4096|28671.5] "" Vector__XXX
 SG_ SCCM_a065_M1RawAngleCurrent m65 : 16|12@1+ (0.08791209,0) [0|360.00000855] "" Vector__XXX
 SG_ SCCM_a065_M1RawAnglePrevious m65 : 28|12@1+ (0.08791209,0) [0|360.00000855] "" Vector__XXX
 SG_ SCCM_a065_M2RawAngleCurrent m65 : 40|12@1+ (0.08791209,0) [0|360.00000855] "" Vector__XXX
 SG_ SCCM_a065_M2RawAnglePrevious m65 : 52|12@1+ (0.08791209,0) [0|360.00000855] "" Vector__XXX
 SG_ SCCM_a066_M1RawAngleCurrent m66 : 16|12@1+ (0.08791209,0) [0|360.00000855] "" Vector__XXX
 SG_ SCCM_a066_M1RawAnglePrevious m66 : 28|12@1+ (0.08791209,0) [0|360.00000855] "" Vector__XXX
 SG_ SCCM_a066_M2RawAngleCurrent m66 : 40|12@1+ (0.08791209,0) [0|360.00000855] "" Vector__XXX
 SG_ SCCM_a066_M2RawAnglePrevious m66 : 52|12@1+ (0.08791209,0) [0|360.00000855] "" Vector__XXX
 SG_ SCCM_a071_M1LogicBISTFailed m71 : 16|1@1+ (1,0) [0|1] "" Vector__XXX
 SG_ SCCM_a071_M1PowerOnReset m71 : 17|1@1+ (1,0) [0|1] "" Vector__XXX
 SG_ SCCM_a071_M1UnderVoltage m71 : 18|1@1+ (1,0) [0|1] "" Vector__XXX
 SG_ SCCM_a071_M1OverVoltage m71 : 19|1@1+ (1,0) [0|1] "" Vector__XXX
 SG_ SCCM_a071_M1DualBitError m71 : 20|1@1+ (1,0) [0|1] "" Vector__XXX
 SG_ SCCM_a071_M1RefVoltageOutOfRange m71 : 21|1@1+ (1,0) [0|1] "" Vector__XXX
 SG_ SCCM_a071_M1RegisterParityError m71 : 22|1@1+ (1,0) [0|1] "" Vector__XXX
 SG_ SCCM_a071_M1OscillatorFreqError m71 : 23|1@1+ (1,0) [0|1] "" Vector__XXX
 SG_ SCCM_a071_M1SignalOutOfRange m71 : 24|1@1+ (1,0) [0|1] "" Vector__XXX
 SG_ SCCM_a071_M1TempOutOfRange m71 : 25|1@1+ (1,0) [0|1] "" Vector__XXX
 SG_ SCCM_a071_M1AngleMismatch m71 : 26|1@1+ (1,0) [0|1] "" Vector__XXX
 SG_ SCCM_a071_M1RadiusOutOfRange m71 : 27|1@1+ (1,0) [0|1] "" Vector__XXX
 SG_ SCCM_a071_M2LogicBISTFailed m71 : 28|1@1+ (1,0) [0|1] "" Vector__XXX
 SG_ SCCM_a071_M2PowerOnReset m71 : 29|1@1+ (1,0) [0|1] "" Vector__XXX
 SG_ SCCM_a071_M2UnderVoltage m71 : 30|1@1+ (1,0) [0|1] "" Vector__XXX
 SG_ SCCM_a071_M2OverVoltage m71 : 31|1@1+ (1,0) [0|1] "" Vector__XXX
 SG_ SCCM_a071_M2DualBitError m71 : 32|1@1+ (1,0) [0|1] "" Vector__XXX
 SG_ SCCM_a071_M2RefVoltageOutOfRange m71 : 33|1@1+ (1,0) [0|1] "" Vector__XXX
 SG_ SCCM_a071_M2RegisterParityError m71 : 34|1@1+ (1,0) [0|1] "" Vector__XXX
 SG_ SCCM_a071_M2OscillatorFreqError m71 : 35|1@1+ (1,0) [0|1] "" Vector__XXX
 SG_ SCCM_a071_M2SignalOutOfRange m71 : 36|1@1+ (1,0) [0|1] "" Vector__XXX
 SG_ SCCM_a071_M2TempOutOfRange m71 : 37|1@1+ (1,0) [0|1] "" Vector__XXX
 SG_ SCCM_a071_M2AngleMismatch m71 : 38|1@1+ (1,0) [0|1] "" Vector__XXX
 SG_ SCCM_a071_M2RadiusOutOfRange m71 : 39|1@1+ (1,0) [0|1] "" Vector__XXX
 SG_ SCCM_a071_M1ProcessLogicFailed m71 : 40|1@1+ (1,0) [0|1] "" Vector__XXX
 SG_ SCCM_a071_M2ProcessLogicFailed m71 : 41|1@1+ (1,0) [0|1] "" Vector__XXX
 SG_ SCCM_a071_TSOSCHighFreqError m71 : 42|1@1+ (1,0) [0|1] "" Vector__XXX
 SG_ SCCM_a071_TSOSCLowFreqError m71 : 43|1@1+ (1,0) [0|1] "" Vector__XXX
 SG_ SCCM_a071_TSOPRStatMismatch m71 : 44|1@1+ (1,0) [0|1] "" Vector__XXX
 SG_ SCCM_a071_TSCRCStatError m71 : 45|1@1+ (1,0) [0|1] "" Vector__XXX
 SG_ SCCM_a071_TSFrameStatError m71 : 46|1@1+ (1,0) [0|1] "" Vector__XXX
 SG_ SCCM_a071_TSOverVoltage m71 : 47|1@1+ (1,0) [0|1] "" Vector__XXX
 SG_ SCCM_a071_TSUnderVoltage m71 : 48|1@1+ (1,0) [0|1] "" Vector__XXX
 SG_ SCCM_a071_TSPowerOnReset m71 : 49|1@1+ (1,0) [0|1] "" Vector__XXX
 SG_ SCCM_a071_TSLDOStatError m71 : 50|1@1+ (1,0) [0|1] "" Vector__XXX
 SG_ SCCM_a071_TSTempOutOfRange m71 : 51|1@1+ (1,0) [0|1] "" Vector__XXX
 SG_ SCCM_a071_TSAlertIntegrityCheck m71 : 52|1@1+ (1,0) [0|1] "" Vector__XXX
 SG_ SCCM_a071_TSMemoryCRCError m71 : 53|1@1+ (1,0) [0|1] "" Vector__XXX
 SG_ SCCM_a071_TSAFECheck m71 : 54|1@1+ (1,0) [0|1] "" Vector__XXX
 SG_ SCCM_a071_TSADCCheck m71 : 55|1@1+ (1,0) [0|1] "" Vector__XXX
 SG_ SCCM_a071_TSConfigFault m71 : 56|1@1+ (1,0) [0|1] "" Vector__XXX
 SG_ SCCM_a072_M1CRCCalculated m72 : 16|4@1+ (1,0) [0|15] "" Vector__XXX
 SG_ SCCM_a072_M1CRCReceived m72 : 20|4@1+ (1,0) [0|15] "" Vector__XXX
 SG_ SCCM_a072_M2CRCCalculated m72 : 24|4@1+ (1,0) [0|15] "" Vector__XXX
 SG_ SCCM_a072_M2CRCReceived m72 : 28|4@1+ (1,0) [0|15] "" Vector__XXX
 SG_ SCCM_a072_TSCRCCalculated m72 : 32|4@1+ (1,0) [0|15] "" Vector__XXX
 SG_ SCCM_a072_TSCRCReceived m72 : 36|4@1+ (1,0) [0|15] "" Vector__XXX
 SG_ SCCM_a075_ClockOutOfRange m75 : 16|1@1+ (1,0) [0|1] "" Vector__XXX
 SG_ SCCM_a075_ExtWatchdogTestFailed m75 : 17|1@1+ (1,0) [0|1] "" Vector__XXX
 SG_ SCCM_a075_InterruptMonitorError m75 : 18|1@1+ (1,0) [0|1] "" Vector__XXX
 SG_ SCCM_a076_RAMTestFailed m76 : 16|1@1+ (1,0) [0|1] "" Vector__XXX
 SG_ SCCM_a076_NVMTestFailed m76 : 17|1@1+ (1,0) [0|1] "" Vector__XXX
 SG_ SCCM_a077_M1ExpectAngleCurrent m77 : 16|12@1+ (0.08791209,0) [0|360.00000855] "" Vector__XXX
 SG_ SCCM_a077_M1ExpectAnglePrevious m77 : 28|12@1+ (0.08791209,0) [0|360.00000855] "" Vector__XXX
 SG_ SCCM_a077_M1AngleCurrent m77 : 40|12@1+ (0.08791209,0) [0|360.00000855] "" Vector__XXX
 SG_ SCCM_a077_M1AnglePrevious m77 : 52|12@1+ (0.08791209,0) [0|360.00000855] "" Vector__XXX
 SG_ SCCM_a079_ChipTemperature m79 : 16|11@1+ (0.1,-50) [-50|154.7] "" Vector__XXX
 SG_ SCCM_a081_StartupTestStatus m81 : 16|3@1+ (1,0) [0|7] "" Vector__XXX
 SG_ SCCM_a081_sCheckTestFailedData m81 : 19|8@1+ (1,0) [0|255] "" Vector__XXX
 SG_ SCCM_a081_sBootTestFailedData m81 : 27|16@1+ (1,0) [0|65535] "" Vector__XXX
 SG_ SCCM_a081_BISTTestFailedData m81 : 43|16@1+ (1,0) [0|65535] "" Vector__XXX
 SG_ SCCM_a082_RuntimeTestStatus m82 : 16|2@1+ (1,0) [0|3] "" Vector__XXX
 SG_ SCCM_a082_sCheckTestFailedData m82 : 18|8@1+ (1,0) [0|255] "" Vector__XXX
 SG_ SCCM_a082_ArrayIntegrFailedData m82 : 26|8@1+ (1,0) [0|255] "" Vector__XXX
 SG_ SCCM_a121_turnIndicatorStalkAngl m121 : 16|12@1+ (0.1,-180) [-180|229.5] "" Vector__XXX
 SG_ SCCM_a121_turnIndicatorHallAngle m121 : 28|12@1+ (0.1,-180) [-180|229.5] "" Vector__XXX
 SG_ SCCM_a122_turnIndicatorSpeed m122 : 16|12@1+ (0.02,-36) [-36|45.9] "" Vector__XXX
 SG_ SCCM_a123_turnIndicatorStalkAngl m123 : 16|12@1+ (0.1,-180) [-180|229.5] "" Vector__XXX
 SG_ SCCM_a124_turnIndicatorStalkAngl m124 : 16|12@1+ (0.1,-180) [-180|229.5] "" Vector__XXX
 SG_ SCCM_a125_turnIndicatorHallAngle m125 : 16|12@1+ (0.1,-180) [-180|229.5] "" Vector__XXX
 SG_ SCCM_a125_turnIndicatorVectorAng m125 : 28|12@1+ (0.1,-180) [-180|229.5] "" Vector__XXX
 SG_ SCCM_a126_turnIndicatorXVectorOu m126 : 16|1@1+ (1,0) [0|1] "" Vector__XXX
 SG_ SCCM_a126_turnIndicatorYVectorOu m126 : 17|1@1+ (1,0) [0|1] "" Vector__XXX
 SG_ SCCM_a126_turnIndicatorZVectorOu m126 : 18|1@1+ (1,0) [0|1] "" Vector__XXX
 SG_ SCCM_a126_turnIndicatorResu_0001 m126 : 19|1@1+ (1,0) [0|1] "" Vector__XXX
 SG_ SCCM_a126_turnIndicatorXMagnitud m126 : 24|8@1+ (1,0) [0|255] "" Vector__XXX
 SG_ SCCM_a126_turnIndicatorYMagnitud m126 : 32|8@1+ (1,0) [0|255] "" Vector__XXX
 SG_ SCCM_a126_turnIndicatorZMagnitud m126 : 40|8@1+ (1,0) [0|255] "" Vector__XXX
 SG_ SCCM_a126_turnIndicatorResultant m126 : 48|8@1+ (1,0) [0|255] "" Vector__XXX

BO_ 1359 SCCM_alertMatrix: 8 SCCM
 SG_ SCCM_matrixIndex M : 0|4@1+ (1,0) [0|15] "" Vector__XXX
 SG_ SCCM_a001_CANBusOff m0 : 4|1@1+ (1,0) [0|1] "" Vector__XXX
 SG_ SCCM_a002_CANTOut m0 : 5|1@1+ (1,0) [0|1] "" Vector__XXX
 SG_ SCCM_a003_highBeamOpen m0 : 6|1@1+ (1,0) [0|1] "" Vector__XXX
 SG_ SCCM_a004_highBeamShortToGND m0 : 7|1@1+ (1,0) [0|1] "" Vector__XXX
 SG_ SCCM_a005_tipWipeOpen m0 : 8|1@1+ (1,0) [0|1] "" Vector__XXX
 SG_ SCCM_a006_tipWipeShortToGND m0 : 9|1@1+ (1,0) [0|1] "" Vector__XXX
 SG_ SCCM_a007_turnIndComInfo m0 : 10|1@1+ (1,0) [0|1] "" Vector__XXX
 SG_ SCCM_a008_turnIndInvalidTrans m0 : 11|1@1+ (1,0) [0|1] "" Vector__XXX
 SG_ SCCM_a009_turnIndOpen m0 : 12|1@1+ (1,0) [0|1] "" Vector__XXX
 SG_ SCCM_a010_turnIndShortToGnd m0 : 13|1@1+ (1,0) [0|1] "" Vector__XXX
 SG_ SCCM_a011_turnIndHWErr m0 : 14|1@1+ (1,0) [0|1] "" Vector__XXX
 SG_ SCCM_a012_turnGenErr m0 : 15|1@1+ (1,0) [0|1] "" Vector__XXX
 SG_ SCCM_a013_voltageHigh m0 : 16|1@1+ (1,0) [0|1] "" Vector__XXX
 SG_ SCCM_a014_voltageLow m0 : 17|1@1+ (1,0) [0|1] "" Vector__XXX
 SG_ SCCM_a015_softwareError m0 : 18|1@1+ (1,0) [0|1] "" Vector__XXX
 SG_ SCCM_a016_hardwareError m0 : 19|1@1+ (1,0) [0|1] "" Vector__XXX
 SG_ SCCM_a017_memoryError m0 : 20|1@1+ (1,0) [0|1] "" Vector__XXX
 SG_ SCCM_a018_angleSpeedOutOfRange m0 : 21|1@1+ (1,0) [0|1] "" Vector__XXX
 SG_ SCCM_a019_angleOutOfRange m0 : 22|1@1+ (1,0) [0|1] "" Vector__XXX
 SG_ SCCM_a020_angleInternalError m0 : 23|1@1+ (1,0) [0|1] "" Vector__XXX
 SG_ SCCM_a021_gearStalkSignalInvalid m0 : 24|1@1+ (1,0) [0|1] "" Vector__XXX
 SG_ SCCM_a022_gearStalkOpenCircuit m0 : 25|1@1+ (1,0) [0|1] "" Vector__XXX
 SG_ SCCM_a023_gearStalkShortCircuit m0 : 26|1@1+ (1,0) [0|1] "" Vector__XXX
 SG_ SCCM_a024_gearStalkGenErr m0 : 27|1@1+ (1,0) [0|1] "" Vector__XXX
 SG_ SCCM_a025_runTimeError m0 : 28|1@1+ (1,0) [0|1] "" Vector__XXX
 SG_ SCCM_a026_parkButtonInvalidSigna m0 : 29|1@1+ (1,0) [0|1] "" Vector__XXX
 SG_ SCCM_a027_parkButtonOpenCircuit m0 : 30|1@1+ (1,0) [0|1] "" Vector__XXX
 SG_ SCCM_a028_parkButtonShortToGroun m0 : 31|1@1+ (1,0) [0|1] "" Vector__XXX
 SG_ SCCM_a029_parkButtonMalfunction m0 : 32|1@1+ (1,0) [0|1] "" Vector__XXX
 SG_ SCCM_a061_voltageHigh_2 m1 : 4|1@1+ (1,0) [0|1] "" Vector__XXX
 SG_ SCCM_a062_voltageLow_2 m1 : 5|1@1+ (1,0) [0|1] "" Vector__XXX
 SG_ SCCM_a063_angleOutOfRange_2 m1 : 6|1@1+ (1,0) [0|1] "" Vector__XXX
 SG_ SCCM_a064_angleSpeedOutOfRange_2 m1 : 7|1@1+ (1,0) [0|1] "" Vector__XXX
 SG_ SCCM_a065_angleNotPlausible m1 : 8|1@1+ (1,0) [0|1] "" Vector__XXX
 SG_ SCCM_a066_angleSpeedNotPlausible m1 : 9|1@1+ (1,0) [0|1] "" Vector__XXX
 SG_ SCCM_a067_CANBusOff_2 m1 : 10|1@1+ (1,0) [0|1] "" Vector__XXX
 SG_ SCCM_a068_CANLVPowerState_LOC m1 : 11|1@1+ (1,0) [0|1] "" Vector__XXX
 SG_ SCCM_a069_calibrationMismatch m1 : 12|1@1+ (1,0) [0|1] "" Vector__XXX
 SG_ SCCM_a070_angleTrimMismatch m1 : 13|1@1+ (1,0) [0|1] "" Vector__XXX
 SG_ SCCM_a071_angleHallSensorError m1 : 14|1@1+ (1,0) [0|1] "" Vector__XXX
 SG_ SCCM_a072_spiBitErrors m1 : 15|1@1+ (1,0) [0|1] "" Vector__XXX
 SG_ SCCM_a073_watchdogReset m1 : 16|1@1+ (1,0) [0|1] "" Vector__XXX
 SG_ SCCM_a074_PLLLossOfLock m1 : 17|1@1+ (1,0) [0|1] "" Vector__XXX
 SG_ SCCM_a075_hardwareError_2 m1 : 18|1@1+ (1,0) [0|1] "" Vector__XXX
 SG_ SCCM_a076_memoryError_2 m1 : 19|1@1+ (1,0) [0|1] "" Vector__XXX
 SG_ SCCM_a077_gearAngleNotPlausible m1 : 20|1@1+ (1,0) [0|1] "" Vector__XXX
 SG_ SCCM_a078_ADCCalibrationError m1 : 21|1@1+ (1,0) [0|1] "" Vector__XXX
 SG_ SCCM_a079_chipTempOutOfRange m1 : 22|1@1+ (1,0) [0|1] "" Vector__XXX
 SG_ SCCM_a080_ADCSelfTestFailed m1 : 23|1@1+ (1,0) [0|1] "" Vector__XXX
 SG_ SCCM_a081_startupTestFailed m1 : 24|1@1+ (1,0) [0|1] "" Vector__XXX
 SG_ SCCM_a082_runtimeTestFailed m1 : 25|1@1+ (1,0) [0|1] "" Vector__XXX
 SG_ SCCM_a121_turnIndicatorAngleInva m2 : 4|1@1+ (1,0) [0|1] "" Vector__XXX
 SG_ SCCM_a122_turnIndicatorSpeedInva m2 : 5|1@1+ (1,0) [0|1] "" Vector__XXX
 SG_ SCCM_a123_turnIndicatorStuckActi m2 : 6|1@1+ (1,0) [0|1] "" Vector__XXX
 SG_ SCCM_a124_turnIndicatorIdleInval m2 : 7|1@1+ (1,0) [0|1] "" Vector__XXX
 SG_ SCCM_a125_turnIndicatorHallAngle m2 : 8|1@1+ (1,0) [0|1] "" Vector__XXX
 SG_ SCCM_a126_turnIndicatorHallMagOu m2 : 9|1@1+ (1,0) [0|1] "" Vector__XXX

BO_ 816 SCCM_info: 8 SCCM
 SG_ SCCM_infoIndex M : 0|8@1+ (1,0) [0|255] "" Vector__XXX
 SG_ SCCM_infoBuildType m10 : 8|8@1+ (1,0) [0|255] "" Vector__XXX
 SG_ SCCM_infoBuildConfigId m10 : 16|16@1+ (1,0) [0|65535] "" Vector__XXX
 SG_ SCCM_infoHardwareId m10 : 32|16@1+ (1,0) [0|65535] "" Vector__XXX
 SG_ SCCM_infoComponentId m10 : 48|16@1+ (1,0) [0|65535] "" Vector__XXX
 SG_ SCCM_infoPcbaId m11 : 16|8@1+ (1,0) [0|255] "" Vector__XXX
 SG_ SCCM_infoAssemblyId m11 : 24|8@1+ (1,0) [0|255] "" Vector__XXX
 SG_ SCCM_infoUsageId m11 : 32|16@1+ (1,0) [0|65535] "" Vector__XXX
 SG_ SCCM_infoSubUsageId m11 : 48|16@1+ (1,0) [0|65535] "" Vector__XXX
 SG_ SCCM_infoPlatformType m13 : 8|8@1+ (1,0) [0|255] "" Vector__XXX
 SG_ SCCM_infoAppCrc m13 : 39|32@0+ (1,0) [0|4294967295] "" Vector__XXX
 SG_ SCCM_infoBootSvnRev m14 : 8|24@1+ (1,0) [0|16777215] "" Vector__XXX
 SG_ SCCM_infoBootSvnUrlHash m14 : 32|32@1+ (1,0) [0|4294967295] "" Vector__XXX
 SG_ SCCM_infoSubcomponent1Version m16 : 16|32@1+ (1,0) [0|4294967295] "" Vector__XXX
 SG_ SCCM_infoAppSvnHash m17 : 8|56@1+ (1,0) [0|7.20575940379e+16] "" Vector__XXX
 SG_ SCCM_infoBootSvnHash m18 : 8|56@1+ (1,0) [0|7.20575940379e+16] "" Vector__XXX
 SG_ SCCM_infoUdsProtoVersion m20 : 8|8@1+ (1,0) [0|255] "" Vector__XXX
 SG_ SCCM_infoBootCrc m20 : 32|32@1+ (1,0) [0|4294967295] "" Vector__XXX

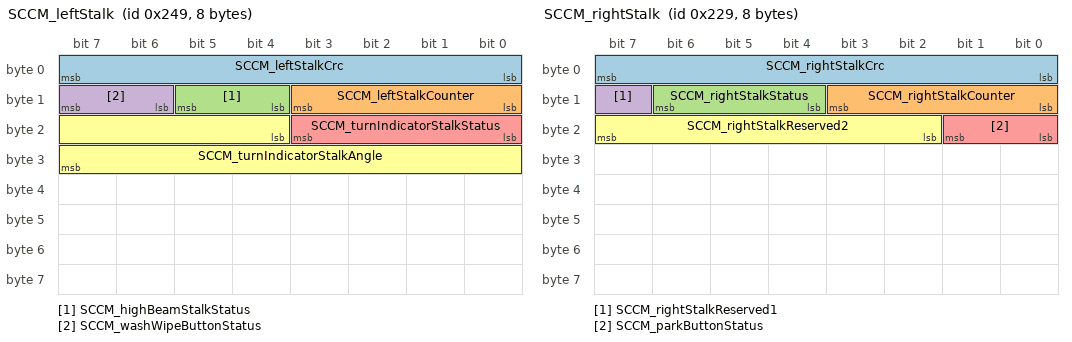
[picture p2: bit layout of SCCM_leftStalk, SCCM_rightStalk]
BO_ 585 SCCM_leftStalk: 8 SCCM
 SG_ SCCM_leftStalkCrc : 0|8@1+ (1,0) [0|255] "" Vector__XXX
 SG_ SCCM_leftStalkCounter : 8|4@1+ (1,0) [0|15] "" Vector__XXX
 SG_ SCCM_highBeamStalkStatus : 12|2@1+ (1,0) [0|3] "" Vector__XXX
 SG_ SCCM_washWipeButtonStatus : 14|2@1+ (1,0) [0|3] "" Vector__XXX
 SG_ SCCM_turnIndicatorStalkStatus : 16|4@1+ (1,0) [0|15] "" Vector__XXX
 SG_ SCCM_turnIndicatorStalkAngle : 20|12@1+ (0.1,-180) [-180|180] "deg" Vector__XXX

BO_ 553 SCCM_rightStalk: 8 SCCM
 SG_ SCCM_rightStalkCrc : 0|8@1+ (1,0) [0|255] "" Vector__XXX
 SG_ SCCM_rightStalkCounter : 8|4@1+ (1,0) [0|15] "" Vector__XXX
 SG_ SCCM_rightStalkStatus : 12|3@1+ (1,0) [0|7] "" Vector__XXX
 SG_ SCCM_rightStalkReserved1 : 15|1@1+ (1,0) [0|1] "" Vector__XXX
 SG_ SCCM_parkButtonStatus : 16|2@1+ (1,0) [0|3] "" Vector__XXX
 SG_ SCCM_rightStalkReserved2 : 18|6@1+ (1,0) [0|63] "" Vector__XXX

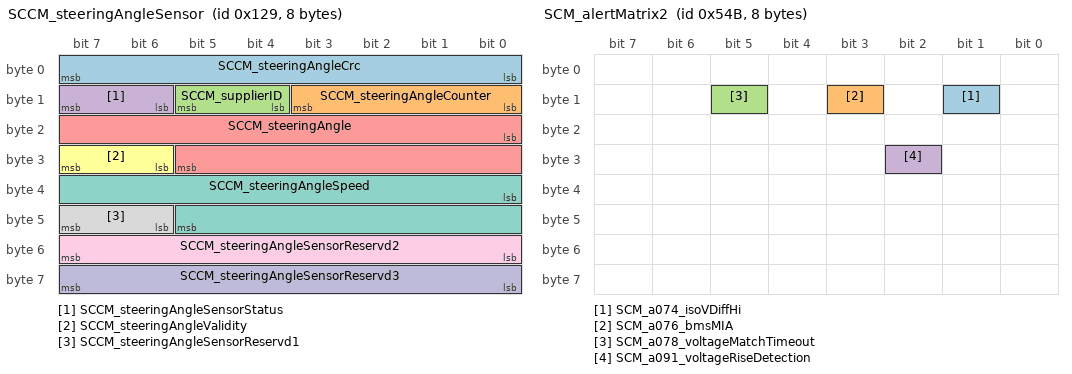
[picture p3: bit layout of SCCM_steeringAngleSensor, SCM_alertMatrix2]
BO_ 297 SCCM_steeringAngleSensor: 8 SCCM
 SG_ SCCM_steeringAngleCrc : 0|8@1+ (1,0) [0|255] "" Vector__XXX
 SG_ SCCM_steeringAngleCounter : 8|4@1+ (1,0) [0|15] "" Vector__XXX
 SG_ SCCM_supplierID : 12|2@1+ (1,0) [0|3] "" Vector__XXX
 SG_ SCCM_steeringAngleSensorStatus : 14|2@1+ (1,0) [0|3] "" Vector__XXX
 SG_ SCCM_steeringAngle : 16|14@1+ (0.1,-819.2) [-819.2|819] "deg" Vector__XXX
 SG_ SCCM_steeringAngleValidity : 30|2@1+ (1,0) [0|3] "" Vector__XXX
 SG_ SCCM_steeringAngleSpeed : 32|14@1+ (0.5,-4096) [-4096|4095.5] "deg/s" Vector__XXX
 SG_ SCCM_steeringAngleSensorReservd1 : 46|2@1+ (1,0) [0|3] "" Vector__XXX
 SG_ SCCM_steeringAngleSensorReservd2 : 48|8@1+ (1,0) [0|255] "" Vector__XXX
 SG_ SCCM_steeringAngleSensorReservd3 : 56|8@1+ (1,0) [0|255] "" Vector__XXX

BO_ 1356 SCM_alertLog: 8 SCM
 SG_ SCM_alertID M : 0|15@1+ (1,0) [0|32767] "" Vector__XXX
 SG_ SCM_alertType : 15|1@1+ (1,0) [0|1] "" Vector__XXX
 SG_ SCM_a074_voltageWithRo m74 : 16|12@1+ (1,0) [0|4095] "" Vector__XXX
 SG_ SCM_a074_voltageWithoutRo m74 : 28|12@1+ (1,0) [0|4095] "" Vector__XXX

BO_ 815 SCM_alertMatrix1: 8 SCM
 SG_ SCM_a027_externalIsolationLow : 26|1@1+ (1,0) [0|1] "" Vector__XXX
 SG_ SCM_a044_proximityRationality : 43|1@1+ (1,0) [0|1] "" Vector__XXX

BO_ 1355 SCM_alertMatrix2: 8 SCM
 SG_ SCM_a074_isoVDiffHi : 9|1@1+ (1,0) [0|1] "" Vector__XXX
 SG_ SCM_a076_bmsMIA : 11|1@1+ (1,0) [0|1] "" Vector__XXX
 SG_ SCM_a078_voltageMatchTimeout : 13|1@1+ (1,0) [0|1] "" Vector__XXX
 SG_ SCM_a091_voltageRiseDetection : 26|1@1+ (1,0) [0|1] "" Vector__XXX

BO_ 1354 SCS_alertLog: 8 SCS
 SG_ SCS_alertID M : 0|15@1+ (1,0) [0|32767] "" Vector__XXX
 SG_ SCS_alertType : 15|1@1+ (1,0) [0|1] "" Vector__XXX
 SG_ SCS_a044_proximityV m44 : 16|16@1+ (0.0001,0) [0|6.5535] "" Vector__XXX
 SG_ SCS_a074_voltageWithRo m74 : 16|12@1+ (0.146520152688,0) [0|600.000025257] "" Vector__XXX
 SG_ SCS_a074_voltageWithoutRo m74 : 28|12@1+ (0.146520152688,0) [0|600.000025257] "" Vector__XXX

BO_ 869 SCS_alertMatrix1: 8 SCS
 SG_ SCS_a001_hwDSPfault : 0|1@1+ (1,0) [0|1] "" Vector__XXX
 SG_ SCS_a002_hwIbatOC : 1|1@1+ (1,0) [0|1] "" Vector__XXX
 SG_ SCS_a003_hwCordOT : 2|1@1+ (1,0) [0|1] "" Vector__XXX
 SG_ SCS_a004_hwVbusOV : 3|1@1+ (1,0) [0|1] "" Vector__XXX
 SG_ SCS_a005_hwHVIL : 4|1@1+ (1,0) [0|1] "" Vector__XXX
 SG_ SCS_a006_hwWeld_V1 : 5|1@1+ (1,0) [0|1] "" Vector__XXX
 SG_ SCS_a007_hwWeld_V2 : 6|1@1+ (1,0) [0|1] "" Vector__XXX
 SG_ SCS_a008_hwIllegalCntrShoot : 7|1@1+ (1,0) [0|1] "" Vector__XXX
 SG_ SCS_a009_hwOpen_V1 : 8|1@1+ (1,0) [0|1] "" Vector__XXX
 SG_ SCS_a010_hwOpen_V2 : 9|1@1+ (1,0) [0|1] "" Vector__XXX
 SG_ SCS_a011_hwIllegalCntrCmdV1 : 10|1@1+ (1,0) [0|1] "" Vector__XXX
 SG_ SCS_a012_hwIllegalCntrCmdV2 : 11|1@1+ (1,0) [0|1] "" Vector__XXX
 SG_ SCS_a013_cordTempHiFoldBk : 12|1@1+ (1,0) [0|1] "" Vector__XXX
 SG_ SCS_a014_coolantTempHiFoldBk : 13|1@1+ (1,0) [0|1] "" Vector__XXX
 SG_ SCS_a015_cpldRationality : 14|1@1+ (1,0) [0|1] "" Vector__XXX
 SG_ SCS_a016_unusedHW16 : 15|1@1+ (1,0) [0|1] "" Vector__XXX
 SG_ SCS_a017_unusedHW17 : 16|1@1+ (1,0) [0|1] "" Vector__XXX
 SG_ SCS_a018_unusedHW18 : 17|1@1+ (1,0) [0|1] "" Vector__XXX
 SG_ SCS_a019_unusedHW19 : 18|1@1+ (1,0) [0|1] "" Vector__XXX
 SG_ SCS_a020_unusedHW20 : 19|1@1+ (1,0) [0|1] "" Vector__XXX
 SG_ SCS_a021_unusedHW21 : 20|1@1+ (1,0) [0|1] "" Vector__XXX
 SG_ SCS_a024_emergencyShutdown : 23|1@1+ (1,0) [0|1] "" Vector__XXX
 SG_ SCS_a025_internalIsolationFault : 24|1@1+ (1,0) [0|1] "" Vector__XXX
 SG_ SCS_a026_internalIsolationLow : 25|1@1+ (1,0) [0|1] "" Vector__XXX
 SG_ SCS_a027_externalIsolationLow : 26|1@1+ (1,0) [0|1] "" Vector__XXX
 SG_ SCS_a028_isolationRationality : 27|1@1+ (1,0) [0|1] "" Vector__XXX
 SG_ SCS_a029_VbatOV : 28|1@1+ (1,0) [0|1] "" Vector__XXX
 SG_ SCS_a030_VbusOV : 29|1@1+ (1,0) [0|1] "" Vector__XXX
 SG_ SCS_a031_IbatOC : 30|1@1+ (1,0) [0|1] "" Vector__XXX
 SG_ SCS_a032_VBatRationality : 31|1@1+ (1,0) [0|1] "" Vector__XXX
 SG_ SCS_a033_VBusRationality : 32|1@1+ (1,0) [0|1] "" Vector__XXX
 SG_ SCS_a034_IBatRationality : 33|1@1+ (1,0) [0|1] "" Vector__XXX
 SG_ SCS_a035_unexpectedVbusBehavior : 34|1@1+ (1,0) [0|1] "" Vector__XXX
 SG_ SCS_a036_internalContactorWelded : 35|1@1+ (1,0) [0|1] "" Vector__XXX
 SG_ SCS_a037_outputContactorWelded : 36|1@1+ (1,0) [0|1] "" Vector__XXX
 SG_ SCS_a038_contactorFailedOpen : 37|1@1+ (1,0) [0|1] "" Vector__XXX
 SG_ SCS_a039_ibatRegulation : 38|1@1+ (1,0) [0|1] "" Vector__XXX
 SG_ SCS_a040_plus12VOutOfRange : 39|1@1+ (1,0) [0|1] "" Vector__XXX
 SG_ SCS_a041_minus12VOutOfRange : 40|1@1+ (1,0) [0|1] "" Vector__XXX
 SG_ SCS_a042_pilotOutOfRange : 41|1@1+ (1,0) [0|1] "" Vector__XXX
 SG_ SCS_a043_pilotRationality : 42|1@1+ (1,0) [0|1] "" Vector__XXX
 SG_ SCS_a044_proximityRationality : 43|1@1+ (1,0) [0|1] "" Vector__XXX
 SG_ SCS_a045_pcbaOT : 44|1@1+ (1,0) [0|1] "" Vector__XXX
 SG_ SCS_a046_coolantOT : 45|1@1+ (1,0) [0|1] "" Vector__XXX
 SG_ SCS_a047_cordOT : 46|1@1+ (1,0) [0|1] "" Vector__XXX
 SG_ SCS_a048_ambientOT : 47|1@1+ (1,0) [0|1] "" Vector__XXX
 SG_ SCS_a049_pcbaTempRationality : 48|1@1+ (1,0) [0|1] "" Vector__XXX
 SG_ SCS_a050_coolantTempRationality : 49|1@1+ (1,0) [0|1] "" Vector__XXX
 SG_ SCS_a051_cordTempRationality : 50|1@1+ (1,0) [0|1] "" Vector__XXX
 SG_ SCS_a052_ambientTempRationality : 51|1@1+ (1,0) [0|1] "" Vector__XXX
 SG_ SCS_a053_unexpectedThermalBehavi : 52|1@1+ (1,0) [0|1] "" Vector__XXX
 SG_ SCS_a054_pumpRegulation : 53|1@1+ (1,0) [0|1] "" Vector__XXX
 SG_ SCS_a055_coolantLevelLow : 54|1@1+ (1,0) [0|1] "" Vector__XXX
 SG_ SCS_a056_stateTransitionDenied : 55|1@1+ (1,0) [0|1] "" Vector__XXX
 SG_ SCS_a057_watchdogReset : 56|1@1+ (1,0) [0|1] "" Vector__XXX
 SG_ SCS_a058_adcRef : 57|1@1+ (1,0) [0|1] "" Vector__XXX
 SG_ SCS_a059_memoryError : 58|1@1+ (1,0) [0|1] "" Vector__XXX
 SG_ SCS_a060_swHVIL : 59|1@1+ (1,0) [0|1] "" Vector__XXX
 SG_ SCS_a061_postOutOfService : 60|1@1+ (1,0) [0|1] "" Vector__XXX
 SG_ SCS_a062_unused : 61|1@1+ (1,0) [0|1] "" Vector__XXX
 SG_ SCS_a063_canRationality : 62|1@1+ (1,0) [0|1] "" Vector__XXX
 SG_ SCS_a064_vehicleCommandTimeout : 63|1@1+ (1,0) [0|1] "" Vector__XXX

BO_ 880 SCS_alertMatrix2: 8 SCS
 SG_ SCS_a065_vBatRationalityStage1 : 0|1@1+ (1,0) [0|1] "" Vector__XXX
 SG_ SCS_a066_vBatRationalityStage2 : 1|1@1+ (1,0) [0|1] "" Vector__XXX
 SG_ SCS_a067_vBatRationalityStage3 : 2|1@1+ (1,0) [0|1] "" Vector__XXX
 SG_ SCS_a068_vBatRationalityStage4 : 3|1@1+ (1,0) [0|1] "" Vector__XXX
 SG_ SCS_a069_vStageRationalityV1 : 4|1@1+ (1,0) [0|1] "" Vector__XXX
 SG_ SCS_a070_vStageRationalityV2 : 5|1@1+ (1,0) [0|1] "" Vector__XXX
 SG_ SCS_a071_chargerMIA : 6|1@1+ (1,0) [0|1] "" Vector__XXX
 SG_ SCS_a072_gtwMIA : 7|1@1+ (1,0) [0|1] "" Vector__XXX
 SG_ SCS_a073_lccMIA : 8|1@1+ (1,0) [0|1] "" Vector__XXX
 SG_ SCS_a074_isoVDiffHi : 9|1@1+ (1,0) [0|1] "" Vector__XXX
 SG_ SCS_a075_unused75 : 10|1@1+ (1,0) [0|1] "" Vector__XXX
 SG_ SCS_a076_bmsMIA : 11|1@1+ (1,0) [0|1] "" Vector__XXX
 SG_ SCS_a077_unexpectedVbatBehavior : 12|1@1+ (1,0) [0|1] "" Vector__XXX
 SG_ SCS_a078_voltageMatchTimeout : 13|1@1+ (1,0) [0|1] "" Vector__XXX
 SG_ SCS_a079_unexpectedVbat : 14|1@1+ (1,0) [0|1] "" Vector__XXX
 SG_ SCS_a080_lccFaulted : 15|1@1+ (1,0) [0|1] "" Vector__XXX
 SG_ SCS_a081_rmsInputVoltageHigh : 16|1@1+ (1,0) [0|1] "" Vector__XXX
 SG_ SCS_a082_VbatUV : 17|1@1+ (1,0) [0|1] "" Vector__XXX
 SG_ SCS_a083_chargeCurrentLimited : 18|1@1+ (1,0) [0|1] "" Vector__XXX
 SG_ SCS_a084_unused84 : 19|1@1+ (1,0) [0|1] "" Vector__XXX
 SG_ SCS_a085_unused85 : 20|1@1+ (1,0) [0|1] "" Vector__XXX
 SG_ SCS_a086_lccResetDetected : 21|1@1+ (1,0) [0|1] "" Vector__XXX
 SG_ SCS_a087_posCordTempRationality : 22|1@1+ (1,0) [0|1] "" Vector__XXX
 SG_ SCS_a088_negCordTempRationality : 23|1@1+ (1,0) [0|1] "" Vector__XXX
 SG_ SCS_a089_posCordOT : 24|1@1+ (1,0) [0|1] "" Vector__XXX
 SG_ SCS_a090_negCordOT : 25|1@1+ (1,0) [0|1] "" Vector__XXX
 SG_ SCS_a091_voltageRiseDetection : 26|1@1+ (1,0) [0|1] "" Vector__XXX
 SG_ SCS_a092_cabEnableDeasserted : 27|1@1+ (1,0) [0|1] "" Vector__XXX
 SG_ SCS_a093_unused93 : 28|1@1+ (1,0) [0|1] "" Vector__XXX
 SG_ SCS_a094_unused94 : 29|1@1+ (1,0) [0|1] "" Vector__XXX
 SG_ SCS_a095_unused95 : 30|1@1+ (1,0) [0|1] "" Vector__XXX
 SG_ SCS_a096_unused96 : 31|1@1+ (1,0) [0|1] "" Vector__XXX
 SG_ SCS_a097_unused97 : 32|1@1+ (1,0) [0|1] "" Vector__XXX
 SG_ SCS_a098_unused98 : 33|1@1+ (1,0) [0|1] "" Vector__XXX
 SG_ SCS_a099_unused99 : 34|1@1+ (1,0) [0|1] "" Vector__XXX
 SG_ SCS_a100_unused100 : 35|1@1+ (1,0) [0|1] "" Vector__XXX
 SG_ SCS_a101_unused101 : 36|1@1+ (1,0) [0|1] "" Vector__XXX
 SG_ SCS_a102_unused102 : 37|1@1+ (1,0) [0|1] "" Vector__XXX
 SG_ SCS_a103_unused103 : 38|1@1+ (1,0) [0|1] "" Vector__XXX
 SG_ SCS_a104_unused104 : 39|1@1+ (1,0) [0|1] "" Vector__XXX
 SG_ SCS_a105_unused105 : 40|1@1+ (1,0) [0|1] "" Vector__XXX
 SG_ SCS_a106_unused106 : 41|1@1+ (1,0) [0|1] "" Vector__XXX
 SG_ SCS_a107_unused107 : 42|1@1+ (1,0) [0|1] "" Vector__XXX
 SG_ SCS_a108_unused108 : 43|1@1+ (1,0) [0|1] "" Vector__XXX
 SG_ SCS_a109_unused109 : 44|1@1+ (1,0) [0|1] "" Vector__XXX
 SG_ SCS_a110_unused110 : 45|1@1+ (1,0) [0|1] "" Vector__XXX
 SG_ SCS_a111_unused111 : 46|1@1+ (1,0) [0|1] "" Vector__XXX
 SG_ SCS_a112_unused112 : 47|1@1+ (1,0) [0|1] "" Vector__XXX
 SG_ SCS_a113_unused113 : 48|1@1+ (1,0) [0|1] "" Vector__XXX
 SG_ SCS_a114_unused114 : 49|1@1+ (1,0) [0|1] "" Vector__XXX
 SG_ SCS_a115_unused115 : 50|1@1+ (1,0) [0|1] "" Vector__XXX
 SG_ SCS_a116_unused116 : 51|1@1+ (1,0) [0|1] "" Vector__XXX
 SG_ SCS_a117_unused117 : 52|1@1+ (1,0) [0|1] "" Vector__XXX
 SG_ SCS_a118_unused118 : 53|1@1+ (1,0) [0|1] "" Vector__XXX
 SG_ SCS_a119_unused119 : 54|1@1+ (1,0) [0|1] "" Vector__XXX
 SG_ SCS_a120_unused120 : 55|1@1+ (1,0) [0|1] "" Vector__XXX
 SG_ SCS_a121_unused121 : 56|1@1+ (1,0) [0|1] "" Vector__XXX
 SG_ SCS_a122_unused122 : 57|1@1+ (1,0) [0|1] "" Vector__XXX
 SG_ SCS_a123_unused123 : 58|1@1+ (1,0) [0|1] "" Vector__XXX
 SG_ SCS_a124_unused124 : 59|1@1+ (1,0) [0|1] "" Vector__XXX
 SG_ SCS_a125_unused125 : 60|1@1+ (1,0) [0|1] "" Vector__XXX
 SG_ SCS_a126_unused126 : 61|1@1+ (1,0) [0|1] "" Vector__XXX
 SG_ SCS_a127_unused127 : 62|1@1+ (1,0) [0|1] "" Vector__XXX
 SG_ SCS_a128_unused128 : 63|1@1+ (1,0) [0|1] "" Vector__XXX

BO_ 1531 SDCR_alertLog: 8 SDCR
 SG_ SDCR_alertID M : 0|6@1+ (1,0) [0|63] "" Vector__XXX
 SG_ SDCR_alertState : 15|1@1+ (1,0) [0|1] "" Vector__XXX
 SG_ SDCR_a001_pyroSenseV m1 : 16|8@1+ (0.02,0) [0|5.1] "" Vector__XXX
 SG_ SDCR_a001_HVBackupSupplyV m1 : 24|8@1+ (0.15,0) [0|38.25] "" Vector__XXX
 SG_ SDCR_a001_boostRailV m1 : 32|8@1+ (0.15,0) [0|38.25] "" Vector__XXX
 SG_ SDCR_a001_expectedPyroV_max m1 : 40|8@1+ (0.02,0) [0|5.1] "" Vector__XXX
 SG_ SDCR_a001_expectedPyroV_min m1 : 48|8@1+ (0.02,0) [0|5.1] "" Vector__XXX
 SG_ SDCR_a001_fromState m1 : 56|3@1+ (1,0) [0|7] "" Vector__XXX
 SG_ SDCR_a004_HVBackupSupplyV m4 : 16|8@1+ (0.15,0) [0|38.25] "" Vector__XXX
 SG_ SDCR_a004_boostRailV m4 : 24|8@1+ (0.15,0) [0|38.25] "" Vector__XXX
 SG_ SDCR_a004_diPresent m4 : 32|1@1+ (1,0) [0|1] "" Vector__XXX
 SG_ SDCR_a004_pmRunningPin m4 : 33|1@1+ (1,0) [0|1] "" Vector__XXX
 SG_ SDCR_a006_pyroArmed m6 : 16|1@1+ (1,0) [0|1] "" Vector__XXX
 SG_ SDCR_a006_triggerReason_faultCur m6 : 17|1@1+ (1,0) [0|1] "" Vector__XXX
 SG_ SDCR_a006_triggerReason_hvBadAtS m6 : 18|1@1+ (1,0) [0|1] "" Vector__XXX
 SG_ SDCR_a006_triggerReason_highBack m6 : 19|1@1+ (1,0) [0|1] "" Vector__XXX
 SG_ SDCR_a006_faultCurrentsDetected m6 : 20|1@1+ (1,0) [0|1] "" Vector__XXX
 SG_ SDCR_a006_diUartMIA m6 : 21|1@1+ (1,0) [0|1] "" Vector__XXX
 SG_ SDCR_a006_pmRunningPin m6 : 22|1@1+ (1,0) [0|1] "" Vector__XXX
 SG_ SDCR_a006_hvPowerGood m6 : 23|1@1+ (1,0) [0|1] "" Vector__XXX
 SG_ SDCR_a006_hvbkupPGoodPin m6 : 24|1@1+ (1,0) [0|1] "" Vector__XXX
 SG_ SDCR_a006_hvPowerNotGoodQualifie m6 : 25|1@1+ (1,0) [0|1] "" Vector__XXX
 SG_ SDCR_a006_speedValid m6 : 26|1@1+ (1,0) [0|1] "" Vector__XXX
 SG_ SDCR_a006_speedFromVoltage m6 : 27|1@1+ (1,0) [0|1] "" Vector__XXX
 SG_ SDCR_a006_HVBackupSupplyV m6 : 28|7@1+ (0.3,0) [0|38.1] "" Vector__XXX
 SG_ SDCR_a006_boostRailV m6 : 35|7@1+ (0.3,0) [0|38.1] "" Vector__XXX
 SG_ SDCR_a006_maxAbsSpeed m6 : 42|12@1- (1,0) [-2048|2047] "" Vector__XXX
 SG_ SDCR_a006_vBat m6 : 54|7@1+ (8,0) [0|1016] "" Vector__XXX
 SG_ SDCR_a007_faultReason_faultCurre m7 : 16|1@1+ (1,0) [0|1] "" Vector__XXX
 SG_ SDCR_a007_faultReason_unmitigate m7 : 17|1@1+ (1,0) [0|1] "" Vector__XXX
 SG_ SDCR_a007_faultReason_propagatin m7 : 18|1@1+ (1,0) [0|1] "" Vector__XXX
 SG_ SDCR_a007_speedWasValid m7 : 19|1@1+ (1,0) [0|1] "" Vector__XXX
 SG_ SDCR_a007_imbalanceSeen m7 : 20|1@1+ (1,0) [0|1] "" Vector__XXX
 SG_ SDCR_a007_ucrSeen m7 : 21|1@1+ (1,0) [0|1] "" Vector__XXX
 SG_ SDCR_a007_phaseVoltagePresent m7 : 22|1@1+ (1,0) [0|1] "" Vector__XXX
 SG_ SDCR_a007_speedFromVoltage m7 : 23|1@1+ (1,0) [0|1] "" Vector__XXX
 SG_ SDCR_a007_transientHandling m7 : 24|2@1+ (1,0) [0|3] "" Vector__XXX
 SG_ SDCR_a007_maxAbsElcSpeed m7 : 26|9@1+ (4,0) [0|2044] "" Vector__XXX
 SG_ SDCR_a007_avgIa m7 : 35|10@1- (4,0) [-2048|2044] "" Vector__XXX
 SG_ SDCR_a007_avgIb m7 : 45|10@1- (4,0) [-2048|2044] "" Vector__XXX
 SG_ SDCR_a007_maxAbsCurrents m7 : 55|9@1+ (4,0) [0|2044] "" Vector__XXX
 SG_ SDCR_a008_dcLinkInfo m8 : 16|1@1+ (1,0) [0|1] "" Vector__XXX
 SG_ SDCR_a009_diVersion m9 : 16|2@1+ (1,0) [0|3] "" Vector__XXX
 SG_ SDCR_a009_sdcVersion m9 : 18|2@1+ (1,0) [0|3] "" Vector__XXX
 SG_ SDCR_a010_pgood m10 : 16|1@1+ (1,0) [0|1] "" Vector__XXX
 SG_ SDCR_a010_boostRailV m10 : 24|8@1+ (0.15,0) [0|38.25] "" Vector__XXX
 SG_ SDCR_a010_Vref m10 : 32|8@1+ (0.02,0) [0|5.1] "" Vector__XXX
 SG_ SDCR_a011_IaAvg m11 : 16|16@1- (0.1,0) [-3276.8|3276.7] "" Vector__XXX
 SG_ SDCR_a011_IbAvg m11 : 32|16@1- (0.1,0) [-3276.8|3276.7] "" Vector__XXX
 SG_ SDCR_a012_boostRailV m12 : 16|8@1+ (0.15,0) [0|38.25] "" Vector__XXX
 SG_ SDCR_a012_HVBackupSupplyV m12 : 24|8@1+ (0.15,0) [0|38.25] "" Vector__XXX
 SG_ SDCR_a012_vBat m12 : 32|10@1+ (2,0) [0|2046] "" Vector__XXX
 SG_ SDCR_a012_vbkupGoodFdbk m12 : 42|1@1+ (1,0) [0|1] "" Vector__XXX
 SG_ SDCR_a013_boostRailV m13 : 16|8@1+ (0.15,0) [0|38.25] "" Vector__XXX
 SG_ SDCR_a013_HVBackupSupplyV m13 : 24|8@1+ (0.15,0) [0|38.25] "" Vector__XXX
 SG_ SDCR_a013_vBat m13 : 32|10@1+ (2,0) [0|2046] "" Vector__XXX
 SG_ SDCR_a013_vbkupGoodFdbk m13 : 42|1@1+ (1,0) [0|1] "" Vector__XXX
 SG_ SDCR_a014_reason_vBusShortedLow m14 : 16|1@1+ (1,0) [0|1] "" Vector__XXX
 SG_ SDCR_a014_reason_vBusShortedHigh m14 : 17|1@1+ (1,0) [0|1] "" Vector__XXX
 SG_ SDCR_a014_boostRailV m14 : 24|8@1+ (0.15,0) [0|38.25] "" Vector__XXX
 SG_ SDCR_a014_HVBackupSupplyV m14 : 32|8@1+ (0.15,0) [0|38.25] "" Vector__XXX
 SG_ SDCR_a014_vBat m14 : 40|10@1+ (2,0) [0|2046] "" Vector__XXX
 SG_ SDCR_a014_vbkupGoodFdbk m14 : 50|1@1+ (1,0) [0|1] "" Vector__XXX
 SG_ SDCR_a015_reason_vPhaseShortedLo m15 : 16|1@1+ (1,0) [0|1] "" Vector__XXX
 SG_ SDCR_a015_reason_vPhaseShortedHi m15 : 17|1@1+ (1,0) [0|1] "" Vector__XXX
 SG_ SDCR_a015_diSwitchingPin m15 : 18|1@1+ (1,0) [0|1] "" Vector__XXX
 SG_ SDCR_a015_vBat m15 : 19|10@1+ (2,0) [0|2046] "" Vector__XXX
 SG_ SDCR_a015_va m15 : 29|10@1+ (2,0) [0|2046] "" Vector__XXX
 SG_ SDCR_a015_vb m15 : 40|10@1+ (2,0) [0|2046] "" Vector__XXX
 SG_ SDCR_a015_vc m15 : 50|10@1+ (2,0) [0|2046] "" Vector__XXX
 SG_ SDCR_a017_expectedConfigWord m17 : 16|16@1+ (1,0) [0|65535] "" Vector__XXX
 SG_ SDCR_a017_receivedConfigWord m17 : 32|16@1+ (1,0) [0|65535] "" Vector__XXX
 SG_ SDCR_a017_configMismatch m17 : 48|1@1+ (1,0) [0|1] "" Vector__XXX
 SG_ SDCR_a017_convStartTimeout m17 : 49|1@1+ (1,0) [0|1] "" Vector__XXX
 SG_ SDCR_a017_convCompleteTimeout m17 : 50|1@1+ (1,0) [0|1] "" Vector__XXX
 SG_ SDCR_a017_dmaSpiTxTransferError m17 : 51|1@1+ (1,0) [0|1] "" Vector__XXX
 SG_ SDCR_a017_dmaSpiRxTransferError m17 : 52|1@1+ (1,0) [0|1] "" Vector__XXX
 SG_ SDCR_a017_dmaSpiTimerEnabled m17 : 53|1@1+ (1,0) [0|1] "" Vector__XXX
 SG_ SDCR_a018_pyroArmed m18 : 16|1@1+ (1,0) [0|1] "" Vector__XXX
 SG_ SDCR_a018_triggerReason_faultCur m18 : 17|1@1+ (1,0) [0|1] "" Vector__XXX
 SG_ SDCR_a018_triggerReason_hvBadAtS m18 : 18|1@1+ (1,0) [0|1] "" Vector__XXX
 SG_ SDCR_a018_triggerReason_highBack m18 : 19|1@1+ (1,0) [0|1] "" Vector__XXX
 SG_ SDCR_a018_faultCurrentsDetected m18 : 20|1@1+ (1,0) [0|1] "" Vector__XXX
 SG_ SDCR_a018_diUartMIA m18 : 21|1@1+ (1,0) [0|1] "" Vector__XXX
 SG_ SDCR_a018_pmRunningPin m18 : 22|1@1+ (1,0) [0|1] "" Vector__XXX
 SG_ SDCR_a018_hvPowerGood m18 : 23|1@1+ (1,0) [0|1] "" Vector__XXX
 SG_ SDCR_a018_hvbkupPGoodPin m18 : 24|1@1+ (1,0) [0|1] "" Vector__XXX
 SG_ SDCR_a018_hvPowerNotGoodQualifie m18 : 25|1@1+ (1,0) [0|1] "" Vector__XXX
 SG_ SDCR_a018_speedValid m18 : 26|1@1+ (1,0) [0|1] "" Vector__XXX
 SG_ SDCR_a018_speedFromVoltage m18 : 27|1@1+ (1,0) [0|1] "" Vector__XXX
 SG_ SDCR_a018_HVBackupSupplyV m18 : 28|7@1+ (0.3,0) [0|38.1] "" Vector__XXX
 SG_ SDCR_a018_boostRailV m18 : 35|7@1+ (0.3,0) [0|38.1] "" Vector__XXX
 SG_ SDCR_a018_maxAbsSpeed m18 : 42|12@1- (1,0) [-2048|2047] "" Vector__XXX
 SG_ SDCR_a018_vBat m18 : 54|7@1+ (8,0) [0|1016] "" Vector__XXX
 SG_ SDCR_a019_faultReason_faultCurre m19 : 16|1@1+ (1,0) [0|1] "" Vector__XXX
 SG_ SDCR_a019_faultReason_unmitigate m19 : 17|1@1+ (1,0) [0|1] "" Vector__XXX
 SG_ SDCR_a019_faultReason_propagatin m19 : 18|1@1+ (1,0) [0|1] "" Vector__XXX
 SG_ SDCR_a019_speedWasValid m19 : 19|1@1+ (1,0) [0|1] "" Vector__XXX
 SG_ SDCR_a019_imbalanceSeen m19 : 20|1@1+ (1,0) [0|1] "" Vector__XXX
 SG_ SDCR_a019_ucrSeen m19 : 21|1@1+ (1,0) [0|1] "" Vector__XXX
 SG_ SDCR_a019_phaseVoltagePresent m19 : 22|1@1+ (1,0) [0|1] "" Vector__XXX
 SG_ SDCR_a019_speedFromVoltage m19 : 23|1@1+ (1,0) [0|1] "" Vector__XXX
 SG_ SDCR_a019_transientHandling m19 : 24|2@1+ (1,0) [0|3] "" Vector__XXX
 SG_ SDCR_a019_maxAbsElcSpeed m19 : 26|9@1+ (4,0) [0|2044] "" Vector__XXX
 SG_ SDCR_a019_avgIa m19 : 35|10@1- (4,0) [-2048|2044] "" Vector__XXX
 SG_ SDCR_a019_avgIb m19 : 45|10@1- (4,0) [-2048|2044] "" Vector__XXX
 SG_ SDCR_a019_maxAbsCurrents m19 : 55|9@1+ (4,0) [0|2044] "" Vector__XXX
 SG_ SDCR_a020_errorCode m20 : 16|8@1+ (1,0) [0|255] "" Vector__XXX
 SG_ SDCR_a020_rxData0 m20 : 24|8@1+ (1,0) [0|255] "" Vector__XXX
 SG_ SDCR_a020_rxData1 m20 : 32|8@1+ (1,0) [0|255] "" Vector__XXX
 SG_ SDCR_a020_rxData2 m20 : 40|8@1+ (1,0) [0|255] "" Vector__XXX
 SG_ SDCR_a020_rxData3 m20 : 48|8@1+ (1,0) [0|255] "" Vector__XXX
 SG_ SDCR_a020_rxData4 m20 : 56|8@1+ (1,0) [0|255] "" Vector__XXX
 SG_ SDCR_a021_busBarTempC m21 : 16|8@1+ (1,-40) [-40|215] "" Vector__XXX
 SG_ SDCR_a021_busBarTempA m21 : 24|8@1+ (1,-40) [-40|215] "" Vector__XXX
 SG_ SDCR_a021_tempCVoltage m21 : 32|8@1+ (0.02,0) [0|5.1] "" Vector__XXX
 SG_ SDCR_a021_tempAVoltage m21 : 40|8@1+ (0.02,0) [0|5.1] "" Vector__XXX
 SG_ SDCR_a024_time m24 : 16|1@1+ (1,0) [0|1] "" Vector__XXX
 SG_ SDCR_a025_diSwitchingFromUart m25 : 16|1@1+ (1,0) [0|1] "" Vector__XXX
 SG_ SDCR_a025_diSwitchingPin m25 : 17|1@1+ (1,0) [0|1] "" Vector__XXX
 SG_ SDCR_a025_pmRunningPin m25 : 18|1@1+ (1,0) [0|1] "" Vector__XXX
 SG_ SDCR_a025_diUartMIA m25 : 19|1@1+ (1,0) [0|1] "" Vector__XXX
 SG_ SDCR_a025_HVBackupSupplyV m25 : 24|8@1+ (0.15,0) [0|38.25] "" Vector__XXX
 SG_ SDCR_a025_boostRailV m25 : 32|8@1+ (0.15,0) [0|38.25] "" Vector__XXX
 SG_ SDCR_a028_LVPowerState m28 : 16|1@1+ (1,0) [0|1] "" Vector__XXX
 SG_ SDCR_a029_uartCommsMissing m29 : 16|1@1+ (1,0) [0|1] "" Vector__XXX
 SG_ SDCR_a029_canCommsMissing m29 : 17|1@1+ (1,0) [0|1] "" Vector__XXX
 SG_ SDCR_a029_lvState m29 : 18|2@1+ (1,0) [0|3] "" Vector__XXX
 SG_ SDCR_a034_Ia m34 : 16|16@1- (0.1,0) [-3276.8|3276.7] "" Vector__XXX
 SG_ SDCR_a034_Ib m34 : 32|16@1- (0.1,0) [-3276.8|3276.7] "" Vector__XXX

BO_ 1467 SDCR_alertMatrix: 8 SDCR
 SG_ SDCR_matrixIndex M : 0|4@1+ (1,0) [0|15] "" Vector__XXX
 SG_ SDCR_a001_powerOnSelfTestFailed m0 : 4|1@1+ (1,0) [0|1] "" Vector__XXX
 SG_ SDCR_a002_diPstSkipped m0 : 5|1@1+ (1,0) [0|1] "" Vector__XXX
 SG_ SDCR_a003_diUartMIA m0 : 6|1@1+ (1,0) [0|1] "" Vector__XXX
 SG_ SDCR_a004_pmRunningFdbkIrrationa m0 : 7|1@1+ (1,0) [0|1] "" Vector__XXX
 SG_ SDCR_a005_motorSpeedIrrational m0 : 8|1@1+ (1,0) [0|1] "" Vector__XXX
 SG_ SDCR_a006_pyroTriggered m0 : 9|1@1+ (1,0) [0|1] "" Vector__XXX
 SG_ SDCR_a007_faultCurrentsDetected m0 : 10|1@1+ (1,0) [0|1] "" Vector__XXX
 SG_ SDCR_a008_hvlinkMIA m0 : 11|1@1+ (1,0) [0|1] "" Vector__XXX
 SG_ SDCR_a009_uartVersionMismatch m0 : 12|1@1+ (1,0) [0|1] "" Vector__XXX
 SG_ SDCR_a010_vrefIrrational m0 : 13|1@1+ (1,0) [0|1] "" Vector__XXX
 SG_ SDCR_a011_phaseCurrentOffset m0 : 14|1@1+ (1,0) [0|1] "" Vector__XXX
 SG_ SDCR_a012_vBoostSecIrrational m0 : 15|1@1+ (1,0) [0|1] "" Vector__XXX
 SG_ SDCR_a013_vBkupIrrational m0 : 16|1@1+ (1,0) [0|1] "" Vector__XXX
 SG_ SDCR_a014_vBusIrrational m0 : 17|1@1+ (1,0) [0|1] "" Vector__XXX
 SG_ SDCR_a015_phaseVIrrational m0 : 18|1@1+ (1,0) [0|1] "" Vector__XXX
 SG_ SDCR_a016_systemReset m0 : 19|1@1+ (1,0) [0|1] "" Vector__XXX
 SG_ SDCR_a017_adcSPIError m0 : 20|1@1+ (1,0) [0|1] "" Vector__XXX
 SG_ SDCR_a018_historicalPyroTrigger m0 : 21|1@1+ (1,0) [0|1] "" Vector__XXX
 SG_ SDCR_a019_historicalFaultCurrent m0 : 22|1@1+ (1,0) [0|1] "" Vector__XXX
 SG_ SDCR_a020_eepromSPIError m0 : 23|1@1+ (1,0) [0|1] "" Vector__XXX
 SG_ SDCR_a021_busBarTempIrrational m0 : 24|1@1+ (1,0) [0|1] "" Vector__XXX
 SG_ SDCR_a022_TaskInitError m0 : 25|1@1+ (1,0) [0|1] "" Vector__XXX
 SG_ SDCR_a023_ecuLogAvailable m0 : 26|1@1+ (1,0) [0|1] "" Vector__XXX
 SG_ SDCR_a024_gtwMIA m0 : 27|1@1+ (1,0) [0|1] "" Vector__XXX
 SG_ SDCR_a025_diSwitchingFdbkIrratio m0 : 28|1@1+ (1,0) [0|1] "" Vector__XXX
 SG_ SDCR_a026_faultCurrentMonitoring m0 : 29|1@1+ (1,0) [0|1] "" Vector__XXX
 SG_ SDCR_a027_diCanMIA m0 : 30|1@1+ (1,0) [0|1] "" Vector__XXX
 SG_ SDCR_a028_vcLVStateMIA m0 : 31|1@1+ (1,0) [0|1] "" Vector__XXX
 SG_ SDCR_a029_diMIA m0 : 32|1@1+ (1,0) [0|1] "" Vector__XXX
 SG_ SDCR_a030_placeholder30 m0 : 33|1@1+ (1,0) [0|1] "" Vector__XXX
 SG_ SDCR_a031_placeholder31 m0 : 34|1@1+ (1,0) [0|1] "" Vector__XXX
 SG_ SDCR_a032_placeholder32 m0 : 35|1@1+ (1,0) [0|1] "" Vector__XXX
 SG_ SDCR_a033_placeholder33 m0 : 36|1@1+ (1,0) [0|1] "" Vector__XXX
 SG_ SDCR_a034_phaseCurrentIrrational m0 : 37|1@1+ (1,0) [0|1] "" Vector__XXX

BO_ 1597 SDCR_info: 8 SDCR
 SG_ SDCR_infoIndex M : 0|8@1+ (1,0) [0|255] "" Vector__XXX
 SG_ SDCR_infoBuildType m10 : 13|3@1+ (1,0) [0|7] "" Vector__XXX
 SG_ SDCR_infoBuildConfigId m10 : 16|16@1+ (1,0) [0|65535] "" Vector__XXX
 SG_ SDCR_infoHardwareId m10 : 32|16@1+ (1,0) [0|65535] "" Vector__XXX
 SG_ SDCR_infoComponentId m10 : 55|16@0+ (1,0) [0|65535] "" Vector__XXX
 SG_ SDCR_infoPcbaId m11 : 8|8@1+ (1,0) [0|255] "" Vector__XXX
 SG_ SDCR_infoAssemblyId m11 : 16|8@1+ (1,0) [0|255] "" Vector__XXX
 SG_ SDCR_infoUsageId m11 : 31|16@0+ (1,0) [0|65535] "" Vector__XXX
 SG_ SDCR_infoSubUsageId m11 : 40|16@1+ (1,0) [0|65535] "" Vector__XXX
 SG_ SDCR_infoAppCrc m13 : 15|32@0+ (1,0) [0|4294967295] "" Vector__XXX
 SG_ SDCR_infoBootGitHash m18 : 8|56@1+ (1,0) [0|7.20575940379e+16] "" Vector__XXX

BO_ 1835 TAS_alertLog: 8 TAS
 SG_ TAS_alertID M : 0|9@1+ (1,0) [0|511] "" Vector__XXX
 SG_ TAS_alertState : 15|1@1+ (1,0) [0|1] "" Vector__XXX
 SG_ TAS_a001_InternalWatchdog m1 : 16|1@1+ (1,0) [0|1] "" Vector__XXX
 SG_ TAS_a002_CPUUndervoltage m2 : 16|1@1+ (1,0) [0|1] "" Vector__XXX
 SG_ TAS_a002_PowerOnReset m2 : 17|1@1+ (1,0) [0|1] "" Vector__XXX
 SG_ TAS_a003_AssertID m3 : 16|16@1+ (1,0) [0|65535] "" Vector__XXX
 SG_ TAS_a003_LineNumber m3 : 32|16@1+ (1,0) [0|65535] "" Vector__XXX
 SG_ TAS_a003_Data m3 : 48|16@1+ (1,0) [0|65535] "" Vector__XXX
 SG_ TAS_a012_ClockError m12 : 16|1@1+ (1,0) [0|1] "" Vector__XXX
 SG_ TAS_a012_FlashError m12 : 17|1@1+ (1,0) [0|1] "" Vector__XXX
 SG_ TAS_a012_SoftwareReset m12 : 18|1@1+ (1,0) [0|1] "" Vector__XXX
 SG_ TAS_a012_CheckstopReset m12 : 19|1@1+ (1,0) [0|1] "" Vector__XXX
 SG_ TAS_a012_DebugReset m12 : 20|1@1+ (1,0) [0|1] "" Vector__XXX
 SG_ TAS_a012_ExternalReset m12 : 21|1@1+ (1,0) [0|1] "" Vector__XXX
 SG_ TAS_a021_Task1msLate m21 : 16|1@1+ (1,0) [0|1] "" Vector__XXX
 SG_ TAS_a021_Task1msStarved m21 : 17|1@1+ (1,0) [0|1] "" Vector__XXX
 SG_ TAS_a021_Task1msMissed m21 : 18|1@1+ (1,0) [0|1] "" Vector__XXX
 SG_ TAS_a021_Task10msLate m21 : 19|1@1+ (1,0) [0|1] "" Vector__XXX
 SG_ TAS_a021_Task10msStarved m21 : 20|1@1+ (1,0) [0|1] "" Vector__XXX
 SG_ TAS_a021_Task10msMissed m21 : 21|1@1+ (1,0) [0|1] "" Vector__XXX
 SG_ TAS_a021_Task100msLate m21 : 22|1@1+ (1,0) [0|1] "" Vector__XXX
 SG_ TAS_a021_Task100msStarved m21 : 23|1@1+ (1,0) [0|1] "" Vector__XXX
 SG_ TAS_a021_Task100msMissed m21 : 24|1@1+ (1,0) [0|1] "" Vector__XXX
 SG_ TAS_a021_Task1000msLate m21 : 25|1@1+ (1,0) [0|1] "" Vector__XXX
 SG_ TAS_a021_Task1000msStarved m21 : 26|1@1+ (1,0) [0|1] "" Vector__XXX
 SG_ TAS_a021_Task1000msMissed m21 : 27|1@1+ (1,0) [0|1] "" Vector__XXX
 SG_ TAS_a022_TaskInitErrorCount m22 : 16|8@1+ (1,0) [0|255] "" Vector__XXX
 SG_ TAS_a022_TaskInitError0 m22 : 24|8@1+ (1,0) [0|255] "" Vector__XXX
 SG_ TAS_a022_TaskInitError1 m22 : 32|8@1+ (1,0) [0|255] "" Vector__XXX
 SG_ TAS_a022_TaskInitError2 m22 : 40|8@1+ (1,0) [0|255] "" Vector__XXX
 SG_ TAS_a022_TaskInitError3 m22 : 48|8@1+ (1,0) [0|255] "" Vector__XXX
 SG_ TAS_a022_TaskInitError4 m22 : 56|8@1+ (1,0) [0|255] "" Vector__XXX
 SG_ TAS_a025_vehicleLockAtCrash m25 : 16|1@1+ (1,0) [0|1] "" Vector__XXX
 SG_ TAS_a025_CANCrashIsActive m25 : 17|1@1+ (1,0) [0|1] "" Vector__XXX
 SG_ TAS_a025_appCrashIsActive m25 : 18|1@1+ (1,0) [0|1] "" Vector__XXX
 SG_ TAS_a025_lastCrashEvent m25 : 24|32@1+ (1,0) [0|4294967295] "" Vector__XXX
 SG_ TAS_a030_PWMdutyCycleFL m30 : 16|16@1+ (0.0025,0) [0|163.8375] "" Vector__XXX
 SG_ TAS_a030_PWMfrequencyFL m30 : 32|16@1+ (0.025,0) [0|1638.375] "" Vector__XXX
 SG_ TAS_a030_PWMfaultFL m30 : 48|4@1+ (1,0) [0|15] "" Vector__XXX
 SG_ TAS_a031_PWMdutyCycleFR m31 : 16|16@1+ (0.0025,0) [0|163.8375] "" Vector__XXX
 SG_ TAS_a031_PWMfrequencyFR m31 : 32|16@1+ (0.025,0) [0|1638.375] "" Vector__XXX
 SG_ TAS_a031_PWMfaultFR m31 : 48|4@1+ (1,0) [0|15] "" Vector__XXX
 SG_ TAS_a032_PWMdutyCycleRL m32 : 16|16@1+ (0.0025,0) [0|163.8375] "" Vector__XXX
 SG_ TAS_a032_PWMfrequencyRL m32 : 32|16@1+ (0.025,0) [0|1638.375] "" Vector__XXX
 SG_ TAS_a032_PWMfaultRL m32 : 48|4@1+ (1,0) [0|15] "" Vector__XXX
 SG_ TAS_a033_PWMdutyCycleRR m33 : 16|16@1+ (0.0025,0) [0|163.8375] "" Vector__XXX
 SG_ TAS_a033_PWMfrequencyRR m33 : 32|16@1+ (0.025,0) [0|1638.375] "" Vector__XXX
 SG_ TAS_a033_PWMfaultRR m33 : 48|4@1+ (1,0) [0|15] "" Vector__XXX
 SG_ TAS_a034_PWMdutyCycleFL m34 : 16|16@1+ (0.0025,0) [0|163.8375] "" Vector__XXX
 SG_ TAS_a034_PWMfrequencyFL m34 : 32|16@1+ (0.025,0) [0|1638.375] "" Vector__XXX
 SG_ TAS_a034_PWMfaultFL m34 : 48|4@1+ (1,0) [0|15] "" Vector__XXX
 SG_ TAS_a035_PWMdutyCycleFR m35 : 16|16@1+ (0.0025,0) [0|163.8375] "" Vector__XXX
 SG_ TAS_a035_PWMfrequencyFR m35 : 32|16@1+ (0.025,0) [0|1638.375] "" Vector__XXX
 SG_ TAS_a035_PWMfaultFR m35 : 48|4@1+ (1,0) [0|15] "" Vector__XXX
 SG_ TAS_a036_PWMdutyCycleRL m36 : 16|16@1+ (0.0025,0) [0|163.8375] "" Vector__XXX
 SG_ TAS_a036_PWMfrequencyRL m36 : 32|16@1+ (0.025,0) [0|1638.375] "" Vector__XXX
 SG_ TAS_a036_PWMfaultRL m36 : 48|4@1+ (1,0) [0|15] "" Vector__XXX
 SG_ TAS_a037_PWMdutyCycleRR m37 : 16|16@1+ (0.0025,0) [0|163.8375] "" Vector__XXX
 SG_ TAS_a037_PWMfrequencyRR m37 : 32|16@1+ (0.025,0) [0|1638.375] "" Vector__XXX
 SG_ TAS_a037_PWMfaultRR m37 : 48|4@1+ (1,0) [0|15] "" Vector__XXX
 SG_ TAS_a038_PWMdutyCycleFL m38 : 16|16@1+ (0.0025,0) [0|163.8375] "" Vector__XXX
 SG_ TAS_a038_PWMfrequencyFL m38 : 32|16@1+ (0.025,0) [0|1638.375] "" Vector__XXX
 SG_ TAS_a038_PWMfaultFL m38 : 48|4@1+ (1,0) [0|15] "" Vector__XXX
 SG_ TAS_a039_PWMdutyCycleFR m39 : 16|16@1+ (0.0025,0) [0|163.8375] "" Vector__XXX
 SG_ TAS_a039_PWMfrequencyFR m39 : 32|16@1+ (0.025,0) [0|1638.375] "" Vector__XXX
 SG_ TAS_a039_PWMfaultFR m39 : 48|4@1+ (1,0) [0|15] "" Vector__XXX
 SG_ TAS_a040_PWMdutyCycleRL m40 : 16|16@1+ (0.0025,0) [0|163.8375] "" Vector__XXX
 SG_ TAS_a040_PWMfrequencyRL m40 : 32|16@1+ (0.025,0) [0|1638.375] "" Vector__XXX
 SG_ TAS_a040_PWMfaultRL m40 : 48|4@1+ (1,0) [0|15] "" Vector__XXX
 SG_ TAS_a041_PWMdutyCycleRR m41 : 16|16@1+ (0.0025,0) [0|163.8375] "" Vector__XXX
 SG_ TAS_a041_PWMfrequencyRR m41 : 32|16@1+ (0.025,0) [0|1638.375] "" Vector__XXX
 SG_ TAS_a041_PWMfaultRR m41 : 48|4@1+ (1,0) [0|15] "" Vector__XXX
 SG_ TAS_a070_voltage12V m70 : 16|16@1+ (0.001,0) [0|65.535] "" Vector__XXX
 SG_ TAS_a071_voltage12V m71 : 16|16@1+ (0.001,0) [0|65.535] "" Vector__XXX
 SG_ TAS_a072_voltage5VOnBoard m72 : 16|16@1+ (0.001,0) [0|65.535] "" Vector__XXX
 SG_ TAS_a073_voltage5VOnBoard m73 : 16|16@1+ (0.001,0) [0|65.535] "" Vector__XXX
 SG_ TAS_a074_voltage5VOffBoard m74 : 16|16@1+ (0.001,0) [0|65.535] "" Vector__XXX
 SG_ TAS_a075_voltage5VOffBoard m75 : 16|16@1+ (0.001,0) [0|65.535] "" Vector__XXX
 SG_ TAS_a076_voltage5VOffBoard m76 : 16|16@1+ (0.001,0) [0|65.535] "" Vector__XXX
 SG_ TAS_a077_sensorVoltage m77 : 16|16@1+ (0.001,0) [0|65.535] "" Vector__XXX
 SG_ TAS_a077_sensorRefVoltage m77 : 32|16@1+ (0.001,0) [0|65.535] "" Vector__XXX
 SG_ TAS_a078_sensorVoltage m78 : 16|16@1+ (0.001,0) [0|65.535] "" Vector__XXX
 SG_ TAS_a078_sensorRefVoltage m78 : 32|16@1+ (0.001,0) [0|65.535] "" Vector__XXX
 SG_ TAS_a080_voltage5VHeight m80 : 16|16@1+ (0.001,0) [0|65.535] "" Vector__XXX
 SG_ TAS_a081_voltage5VHeight m81 : 16|16@1+ (0.001,0) [0|65.535] "" Vector__XXX
 SG_ TAS_a082_voltage5VHeight m82 : 16|16@1+ (0.001,0) [0|65.535] "" Vector__XXX
 SG_ TAS_a083_voltage5VAnalog m83 : 16|16@1+ (0.001,0) [0|65.535] "" Vector__XXX
 SG_ TAS_a084_voltage5VAnalog m84 : 16|16@1+ (0.001,0) [0|65.535] "" Vector__XXX
 SG_ TAS_a085_voltage5VAnalog m85 : 16|16@1+ (0.001,0) [0|65.535] "" Vector__XXX
 SG_ TAS_a086_voltage12VSwitched m86 : 16|16@1+ (0.001,0) [0|65.535] "" Vector__XXX
 SG_ TAS_a087_voltage12VSwitched m87 : 16|16@1+ (0.001,0) [0|65.535] "" Vector__XXX
 SG_ TAS_a093_readError m93 : 16|1@1+ (1,0) [0|1] "" Vector__XXX
 SG_ TAS_a093_IVOR2Exception m93 : 17|1@1+ (1,0) [0|1] "" Vector__XXX
 SG_ TAS_a098_VCFRONT_LVPowerState_MI m98 : 16|1@1+ (1,0) [0|1] "" Vector__XXX
 SG_ TAS_a098_VCFRONT_sensors_MIA m98 : 17|1@1+ (1,0) [0|1] "" Vector__XXX
 SG_ TAS_a098_VCFRONT_status_MIA m98 : 18|1@1+ (1,0) [0|1] "" Vector__XXX
 SG_ TAS_a098_VCFRONT_systemStatus_MI m98 : 19|1@1+ (1,0) [0|1] "" Vector__XXX
 SG_ TAS_a098_VCFRONT_vehNm_MIA m98 : 20|1@1+ (1,0) [0|1] "" Vector__XXX
 SG_ TAS_a099_UI_chassisControl_MIA m99 : 16|1@1+ (1,0) [0|1] "" Vector__XXX
 SG_ TAS_a099_UI_driverAssistMapData_ m99 : 17|1@1+ (1,0) [0|1] "" Vector__XXX
 SG_ TAS_a099_UI_suspensionControl_MI m99 : 18|1@1+ (1,0) [0|1] "" Vector__XXX
 SG_ TAS_a099_UI_vehicleModes_MIA m99 : 19|1@1+ (1,0) [0|1] "" Vector__XXX
 SG_ TAS_a100_RCM_inertial1_MIA m100 : 16|1@1+ (1,0) [0|1] "" Vector__XXX
 SG_ TAS_a100_RCM_inertial2_MIA m100 : 17|1@1+ (1,0) [0|1] "" Vector__XXX
 SG_ TAS_a101_ESP_brakeTorque_MIA m101 : 16|1@1+ (1,0) [0|1] "" Vector__XXX
 SG_ TAS_a101_ESP_status_MIA m101 : 17|1@1+ (1,0) [0|1] "" Vector__XXX
 SG_ TAS_a101_ESP_wheelRotation_MIA m101 : 18|1@1+ (1,0) [0|1] "" Vector__XXX
 SG_ TAS_a102_DI_chassisControl_MIA m102 : 16|1@1+ (1,0) [0|1] "" Vector__XXX
 SG_ TAS_a102_DI_locStatus_MIA m102 : 17|1@1+ (1,0) [0|1] "" Vector__XXX
 SG_ TAS_a102_DI_speed_MIA m102 : 18|1@1+ (1,0) [0|1] "" Vector__XXX
 SG_ TAS_a102_DI_systemStatus_MIA m102 : 19|1@1+ (1,0) [0|1] "" Vector__XXX
 SG_ TAS_a102_DI_vehicleEstimates_MIA m102 : 20|1@1+ (1,0) [0|1] "" Vector__XXX
 SG_ TAS_a102_DIF_torque_MIA m102 : 21|1@1+ (1,0) [0|1] "" Vector__XXX
 SG_ TAS_a102_DIR_torque_MIA m102 : 22|1@1+ (1,0) [0|1] "" Vector__XXX
 SG_ TAS_a103_GTW_carConfig_MIA m103 : 16|1@1+ (1,0) [0|1] "" Vector__XXX
 SG_ TAS_a103_GTW_time_MIA m103 : 17|1@1+ (1,0) [0|1] "" Vector__XXX
 SG_ TAS_a103_GTW_vehNm_MIA m103 : 18|1@1+ (1,0) [0|1] "" Vector__XXX
 SG_ TAS_a103_GTW_vin_MIA m103 : 19|1@1+ (1,0) [0|1] "" Vector__XXX
 SG_ TAS_a164_detectedDamperSolenoid m164 : 16|3@1+ (1,0) [0|7] "" Vector__XXX
 SG_ TAS_a164_expectedDamperSolenoid m164 : 19|3@1+ (1,0) [0|7] "" Vector__XXX
 SG_ TAS_a165_damperValveFault m165 : 16|4@1+ (1,0) [0|15] "" Vector__XXX
 SG_ TAS_a165_resistanceValue m165 : 20|11@1+ (0.01,0) [0|20.47] "" Vector__XXX
 SG_ TAS_a166_damperValveFault m166 : 16|4@1+ (1,0) [0|15] "" Vector__XXX
 SG_ TAS_a166_resistanceValue m166 : 20|11@1+ (0.01,0) [0|20.47] "" Vector__XXX
 SG_ TAS_a167_damperValveFault m167 : 16|4@1+ (1,0) [0|15] "" Vector__XXX
 SG_ TAS_a167_resistanceValue m167 : 20|11@1+ (0.01,0) [0|20.47] "" Vector__XXX
 SG_ TAS_a168_damperValveFault m168 : 16|4@1+ (1,0) [0|15] "" Vector__XXX
 SG_ TAS_a168_resistanceValue m168 : 20|11@1+ (0.01,0) [0|20.47] "" Vector__XXX
 SG_ TAS_a169_damperValveFault m169 : 16|4@1+ (1,0) [0|15] "" Vector__XXX
 SG_ TAS_a169_resistanceValue m169 : 20|11@1+ (0.01,0) [0|20.47] "" Vector__XXX
 SG_ TAS_a170_damperValveFault m170 : 16|4@1+ (1,0) [0|15] "" Vector__XXX
 SG_ TAS_a170_resistanceValue m170 : 20|11@1+ (0.01,0) [0|20.47] "" Vector__XXX
 SG_ TAS_a171_damperValveFault m171 : 16|4@1+ (1,0) [0|15] "" Vector__XXX
 SG_ TAS_a171_resistanceValue m171 : 20|11@1+ (0.01,0) [0|20.47] "" Vector__XXX
 SG_ TAS_a172_damperValveFault m172 : 16|4@1+ (1,0) [0|15] "" Vector__XXX
 SG_ TAS_a172_resistanceValue m172 : 20|11@1+ (0.01,0) [0|20.47] "" Vector__XXX
 SG_ TAS_a173_heightDelta_mm m173 : 16|8@1+ (1,-128) [-128|127] "" Vector__XXX
 SG_ TAS_a174_heightDelta_mm m174 : 16|8@1+ (1,-128) [-128|127] "" Vector__XXX
 SG_ TAS_a175_heightDelta_mm m175 : 16|8@1+ (1,-128) [-128|127] "" Vector__XXX
 SG_ TAS_a176_heightDelta_mm m176 : 16|8@1+ (1,-128) [-128|127] "" Vector__XXX
 SG_ TAS_a190_a2bFaultType m190 : 16|4@1+ (1,0) [0|15] "" Vector__XXX
 SG_ TAS_a190_a2bInterruptType m190 : 24|8@1+ (1,0) [0|255] "" Vector__XXX
 SG_ TAS_a190_a2bFaultSource m190 : 32|2@1+ (1,0) [0|3] "" Vector__XXX
 SG_ TAS_a191_a2bFaultType m191 : 16|4@1+ (1,0) [0|15] "" Vector__XXX
 SG_ TAS_a191_a2bInterruptType m191 : 24|8@1+ (1,0) [0|255] "" Vector__XXX
 SG_ TAS_a191_a2bFaultSource m191 : 32|2@1+ (1,0) [0|3] "" Vector__XXX
 SG_ TAS_a192_rideHeightVelDspFL m192 : 16|5@1- (0.2,0) [-3.2|3] "" Vector__XXX
 SG_ TAS_a192_rideHeightVelDspFR m192 : 24|5@1- (0.2,0) [-3.2|3] "" Vector__XXX
 SG_ TAS_a192_rideHeightVelDspRL m192 : 32|5@1- (0.2,0) [-3.2|3] "" Vector__XXX
 SG_ TAS_a192_rideHeightVelDspRR m192 : 37|5@1- (0.2,0) [-3.2|3] "" Vector__XXX
 SG_ TAS_a192_rideHeightVelObserverFL m192 : 42|5@1- (0.2,0) [-3.2|3] "" Vector__XXX
 SG_ TAS_a192_rideHeightVelObserverFR m192 : 47|5@1- (0.2,0) [-3.2|3] "" Vector__XXX
 SG_ TAS_a192_rideHeightVelObserverRL m192 : 52|5@1- (0.2,0) [-3.2|3] "" Vector__XXX
 SG_ TAS_a192_rideHeightVelObserverRR m192 : 57|5@1- (0.2,0) [-3.2|3] "" Vector__XXX
 SG_ TAS_a192_alertVersion m192 : 62|2@1+ (1,0) [0|3] "" Vector__XXX
 SG_ TAS_a193_EPAS3P_sysStatus_MIA m193 : 16|1@1+ (1,0) [0|1] "" Vector__XXX
 SG_ TAS_a210_heightSensorDeltaFL m210 : 16|8@1+ (1,-128) [-128|127] "" Vector__XXX
 SG_ TAS_a210_heightSensorDeltaFR m210 : 24|8@1+ (1,-128) [-128|127] "" Vector__XXX
 SG_ TAS_a210_heightSensorDeltaRL m210 : 32|8@1+ (1,-128) [-128|127] "" Vector__XXX
 SG_ TAS_a210_heightSensorDeltaRR m210 : 40|8@1+ (1,-128) [-128|127] "" Vector__XXX
 SG_ TAS_a220_galleryPressure m220 : 16|8@1+ (0.1,0) [0|25.5] "" Vector__XXX
 SG_ TAS_a220_timeInExhaust m220 : 24|32@1+ (1,0) [0|4294967295] "" Vector__XXX
 SG_ TAS_a221_galleryPressureDelta m221 : 16|8@1+ (0.1,0) [0|25.5] "" Vector__XXX
 SG_ TAS_a221_timeInIdle m221 : 24|32@1+ (1,0) [0|4294967295] "" Vector__XXX
 SG_ TAS_a222_galleryPressureDelta m222 : 16|8@1+ (0.1,0) [0|25.5] "" Vector__XXX
 SG_ TAS_a223_galleryPressure m223 : 16|8@1+ (0.1,0) [0|25.5] "" Vector__XXX
 SG_ TAS_a223_valveOnFL m223 : 24|1@1+ (1,0) [0|1] "" Vector__XXX
 SG_ TAS_a223_valveOnFR m223 : 25|1@1+ (1,0) [0|1] "" Vector__XXX
 SG_ TAS_a223_valveOnRL m223 : 26|1@1+ (1,0) [0|1] "" Vector__XXX
 SG_ TAS_a223_valveOnRR m223 : 27|1@1+ (1,0) [0|1] "" Vector__XXX
 SG_ TAS_a223_valveOnReservoir m223 : 28|1@1+ (1,0) [0|1] "" Vector__XXX
 SG_ TAS_a224_galleryPressure m224 : 16|8@1+ (0.1,0) [0|25.5] "" Vector__XXX
 SG_ TAS_a224_valveOnFL m224 : 24|1@1+ (1,0) [0|1] "" Vector__XXX
 SG_ TAS_a224_valveOnFR m224 : 25|1@1+ (1,0) [0|1] "" Vector__XXX
 SG_ TAS_a224_valveOnRL m224 : 26|1@1+ (1,0) [0|1] "" Vector__XXX
 SG_ TAS_a224_valveOnRR m224 : 27|1@1+ (1,0) [0|1] "" Vector__XXX
 SG_ TAS_a224_valveOnReservoir m224 : 28|1@1+ (1,0) [0|1] "" Vector__XXX
 SG_ TAS_a225_galleryPressure m225 : 16|8@1+ (0.1,0) [0|25.5] "" Vector__XXX
 SG_ TAS_a226_PWMdutyCycleFL m226 : 16|16@1+ (0.0025,0) [0|163.8375] "" Vector__XXX
 SG_ TAS_a226_PWMfrequencyFL m226 : 32|16@1+ (0.025,0) [0|1638.375] "" Vector__XXX
 SG_ TAS_a226_PWMfaultFL m226 : 48|4@1+ (1,0) [0|15] "" Vector__XXX
 SG_ TAS_a227_PWMdutyCycleFR m227 : 16|16@1+ (0.0025,0) [0|163.8375] "" Vector__XXX
 SG_ TAS_a227_PWMfrequencyFR m227 : 32|16@1+ (0.025,0) [0|1638.375] "" Vector__XXX
 SG_ TAS_a227_PWMfaultFR m227 : 48|4@1+ (1,0) [0|15] "" Vector__XXX
 SG_ TAS_a228_PWMdutyCycleRL m228 : 16|16@1+ (0.0025,0) [0|163.8375] "" Vector__XXX
 SG_ TAS_a228_PWMfrequencyRL m228 : 32|16@1+ (0.025,0) [0|1638.375] "" Vector__XXX
 SG_ TAS_a228_PWMfaultRL m228 : 48|4@1+ (1,0) [0|15] "" Vector__XXX
 SG_ TAS_a229_PWMdutyCycleRR m229 : 16|16@1+ (0.0025,0) [0|163.8375] "" Vector__XXX
 SG_ TAS_a229_PWMfrequencyRR m229 : 32|16@1+ (0.025,0) [0|1638.375] "" Vector__XXX
 SG_ TAS_a229_PWMfaultRR m229 : 48|4@1+ (1,0) [0|15] "" Vector__XXX
 SG_ TAS_a232_detectedSuspensionType m232 : 16|3@1+ (1,0) [0|7] "" Vector__XXX
 SG_ TAS_a232_expectedSuspensionType m232 : 19|3@1+ (1,0) [0|7] "" Vector__XXX
 SG_ TAS_a234_detectedDamperHydraulic m234 : 16|2@1+ (1,0) [0|3] "" Vector__XXX
 SG_ TAS_a234_expectedDamperHydraulic m234 : 18|2@1+ (1,0) [0|3] "" Vector__XXX
 SG_ TAS_a240_highAdjustCountRatio m240 : 16|1@1+ (1,0) [0|1] "" Vector__XXX
 SG_ TAS_a240_highAdjustTimeRatio m240 : 17|1@1+ (1,0) [0|1] "" Vector__XXX
 SG_ TAS_a240_highCrossPressure m240 : 18|1@1+ (1,0) [0|1] "" Vector__XXX
 SG_ TAS_a240_highCompExhTimeRatio m240 : 19|1@1+ (1,0) [0|1] "" Vector__XXX
 SG_ TAS_a240_adjustCountRatioSpring m240 : 20|3@1+ (1,0) [0|7] "" Vector__XXX
 SG_ TAS_a240_adjustCountRatio m240 : 24|8@1+ (0.02952756,0) [0|7.5295278] "" Vector__XXX
 SG_ TAS_a240_adjustTimeRatioSpring m240 : 32|3@1+ (1,0) [0|7] "" Vector__XXX
 SG_ TAS_a240_adjustTimeRatio m240 : 40|8@1+ (0.02952756,0) [0|7.5295278] "" Vector__XXX
 SG_ TAS_a240_compExhTimeRatio m240 : 48|8@1+ (0.0294117648154,0) [0|7.50000002793] "" Vector__XXX
 SG_ TAS_a240_crossPressure m240 : 56|8@1- (0.1,0) [-12.8|12.7] "" Vector__XXX
 SG_ TAS_a285_twistLevel m285 : 16|8@1+ (1,-128) [-128|127] "" Vector__XXX
 SG_ TAS_a290_twistLevel m290 : 16|8@1+ (1,-128) [-128|127] "" Vector__XXX
 SG_ TAS_a291_frontAxleHeight m291 : 16|8@1+ (1,-128) [-128|127] "" Vector__XXX
 SG_ TAS_a292_rearAxleHeight m292 : 16|8@1+ (1,-128) [-128|127] "" Vector__XXX
 SG_ TAS_a293_frontAxleHeight m293 : 16|8@1+ (1,-128) [-128|127] "" Vector__XXX
 SG_ TAS_a294_rearAxleHeight m294 : 16|8@1+ (1,-128) [-128|127] "" Vector__XXX
 SG_ TAS_a295_targetHeight m295 : 16|8@1+ (1,-128) [-128|127] "" Vector__XXX
 SG_ TAS_a296_detectedChassisType m296 : 16|3@1+ (1,0) [0|7] "" Vector__XXX
 SG_ TAS_a296_expectedChassisType m296 : 19|3@1+ (1,0) [0|7] "" Vector__XXX
 SG_ TAS_a319_detectedDrivetrainType m319 : 16|3@1+ (1,0) [0|7] "" Vector__XXX
 SG_ TAS_a319_expectedDrivetrainType m319 : 19|3@1+ (1,0) [0|7] "" Vector__XXX

CM_ BO_ 881 "Restraint control module message: alert matrix";
CM_ SG_ 881 RCM_matrixIndex "Restraint control module: matrix index";
CM_ SG_ 881 RCM_a000_crashDetected "Restraint control module: a000 crash detected";
CM_ SG_ 881 RCM_a001_nearDeploy "Restraint control module: a001 near deploy";
CM_ SG_ 881 RCM_a002_airbagsNotArmed "Restraint control module: a002 airbags not armed";
CM_ SG_ 881 RCM_a003_warningIndicator "Restraint control module: a003 warning indicator";
CM_ SG_ 881 RCM_a004_internalFault "Restraint control module: a004 internal fault";
CM_ SG_ 881 RCM_a005_crcError "Restraint control module: a005 crc error";
CM_ SG_ 881 RCM_a006_batteryVoltageRange "Restraint control module: a006 battery voltage range";
CM_ SG_ 881 RCM_a007_powerSupplyExternal "Restraint control module: a007 power supply external";
CM_ SG_ 881 RCM_a008_powerSupplyInternal "Restraint control module: a008 power supply internal";
CM_ SG_ 881 RCM_a009_reprogramLimit "Restraint control module: a009 reprogram limit";
CM_ SG_ 881 RCM_a010_scmDisabled "Restraint control module: a010 scm disabled";
CM_ SG_ 881 RCM_a011_eepromDataLocked "Restraint control module: a011 eeprom data locked";
CM_ SG_ 881 RCM_a012_vinStorage "Restraint control module: a012 vin storage";
CM_ SG_ 881 RCM_a013_driverOrientation "Restraint control module: a013 driver orientation";
CM_ SG_ 881 RCM_a014_driverABStage1 "Restraint control module: a014 driver AB stage1";
CM_ SG_ 881 RCM_a015_driverABStage2 "Restraint control module: a015 driver AB stage2";
CM_ SG_ 881 RCM_a016_passABStage1 "Restraint control module: a016 pass AB stage1";
CM_ SG_ 881 RCM_a017_passABStage2 "Restraint control module: a017 pass AB stage2";
CM_ SG_ 881 RCM_a018_passengerActiveVent "Restraint control module: a018 passenger active vent";
CM_ SG_ 881 RCM_a019_pretenShldrFrontLeft "Restraint control module: a019 preten shldr front left";
CM_ SG_ 881 RCM_a020_pretenShldFrontRight "Restraint control module: a020 preten shld front right";
CM_ SG_ 881 RCM_a021_pretenLapFrontLeft "Restraint control module: a021 preten lap front left";
CM_ SG_ 881 RCM_a022_pretenLapFrontRight "Restraint control module: a022 preten lap front right";
CM_ SG_ 881 RCM_a023_loadLimiterLeftSide "Restraint control module: a023 load limiter left side";
CM_ SG_ 881 RCM_a024_loadLimiterRightSide "Restraint control module: a024 load limiter right side";
CM_ SG_ 881 RCM_a025_kneeABDriver "Restraint control module: a025 knee AB driver";
CM_ SG_ 881 RCM_a026_kneeABFrontPassenger "Restraint control module: a026 knee AB front passenger";
CM_ SG_ 881 RCM_a027_sideAB1stRowLeft "Restraint control module: a027 side ab1st row left";
CM_ SG_ 881 RCM_a028_sideAB1stRowRight "Restraint control module: a028 side ab1st row right";
CM_ SG_ 881 RCM_a029_driverABActiveVent "Restraint control module: a029 driver AB active vent";
CM_ SG_ 881 RCM_a030_farSideInboardAirbag "Restraint control module: a030 far side inboard airbag";
CM_ SG_ 881 RCM_a031_frontCenterAirbag "Restraint control module: a031 front center airbag";
CM_ SG_ 881 RCM_a032_curtainABLeft "Restraint control module: a032 curtain AB left";
CM_ SG_ 881 RCM_a033_curtainABRight "Restraint control module: a033 curtain AB right";
CM_ SG_ 881 RCM_a034_preten2ndRowLeft "Restraint control module: a034 preten2nd row left";
CM_ SG_ 881 RCM_a035_preten2ndRowRight "Restraint control module: a035 preten2nd row right";
CM_ SG_ 881 RCM_a036_curAB2ndRowLeft "Restraint control module: a036 cur ab2nd row left";
CM_ SG_ 881 RCM_a037_curAB2ndRowRight "Restraint control module: a037 cur ab2nd row right";
CM_ SG_ 881 RCM_a038_unusedA "Restraint control module: a038 unused a";
CM_ SG_ 881 RCM_a039_unusedB "Restraint control module: a039 unused b";
CM_ SG_ 881 RCM_a040_hoodActuatorRight "Restraint control module: a040 hood actuator right";
CM_ SG_ 881 RCM_a041_hoodActuatorLeft "Restraint control module: a041 hood actuator left";
CM_ SG_ 881 RCM_a042_ens1Line "Restraint control module: a042 ens1 line";
CM_ SG_ 881 RCM_a043_ens2Line "Restraint control module: a043 ens2 line";
CM_ SG_ 881 RCM_a044_upFrontSensorLeft "Restraint control module: a044 up front sensor left";
CM_ SG_ 881 RCM_a045_upFrontSensorRight "Restraint control module: a045 up front sensor right";
CM_ SG_ 881 RCM_a046_sideAccelBPillarLeft "Restraint control module: a046 side accel b pillar left";
CM_ SG_ 881 RCM_a047_sideAccelBPillarRight "Restraint control module: a047 side accel b pillar right";
CM_ SG_ 881 RCM_a048_sideAccelCPillarLeft "Restraint control module: a048 side accel c pillar left";
CM_ SG_ 881 RCM_a049_sideAccelCPillarRight "Restraint control module: a049 side accel c pillar right";
CM_ SG_ 881 RCM_a050_upFrontSensorCenter "Restraint control module: a050 up front sensor center";
CM_ SG_ 881 RCM_a051_pressureFrontLftDoor "Restraint control module: a051 pressure front lft door";
CM_ SG_ 881 RCM_a052_pressureFrontRtDoor "Restraint control module: a052 pressure front rt door";
CM_ SG_ 881 RCM_a053_pressurePedProLeft "Restraint control module: a053 pressure ped pro left";
CM_ SG_ 881 RCM_a054_pressurePedProRight "Restraint control module: a054 pressure ped pro right";
CM_ SG_ 881 RCM_a055_inertialMeasurement "Restraint control module: a055 inertial measurement";
CM_ SG_ 881 RCM_a056_passengerFrontOCS "Restraint control module: a056 passenger front OCS";
CM_ SG_ 881 RCM_a057_driverOCS "Restraint control module: a057 driver OCS";
CM_ SG_ 881 RCM_a058_buckle1stRowLeft "Restraint control module: a058 buckle1st row left";
CM_ SG_ 881 RCM_a059_buckle1stRowRight "Restraint control module: a059 buckle1st row right";
CM_ SG_ 881 RCM_a060_stpsLeft "Restraint control module: a060 stps left";
CM_ SG_ 881 RCM_a061_stpsRight "Restraint control module: a061 stps right";
CM_ SG_ 881 RCM_a062_alrSwitch "Restraint control module: a062 alr switch";
CM_ SG_ 881 RCM_a063_sbsw2ndRowRight "Restraint control module: a063 sbsw2nd row right";
CM_ SG_ 881 RCM_a064_hardwareCodingPin1 "Restraint control module: a064 hardware coding pin1";
CM_ SG_ 881 RCM_a065_driverOrientConfigPin "Restraint control module: a065 driver orient config pin";
CM_ SG_ 881 RCM_a066_seatBackSw2ndRowLeft "Restraint control module: a066 seat back sw2nd row left";
CM_ SG_ 881 RCM_a067_comCANInitFailure "Restraint control module: a067 com CAN init failure";
CM_ SG_ 881 RCM_a068_comChassisBusOff "Restraint control module: a068 com chassis bus off";
CM_ SG_ 881 RCM_a069_comCHCANPH7 "Restraint control module: a069 com CHCANPH7";
CM_ SG_ 881 RCM_a070_comCHCANPH8 "Restraint control module: a070 com CHCANPH8";
CM_ SG_ 881 RCM_a071_comCHCANPH9 "Restraint control module: a071 com CHCANPH9";
CM_ SG_ 881 RCM_a072_comUnused "Restraint control module: a072 com unused";
CM_ SG_ 881 RCM_a073_comCHCANPH4 "Restraint control module: a073 com CHCANPH4";
CM_ SG_ 881 RCM_a074_comCHCANPH5 "Restraint control module: a074 com CHCANPH5";
CM_ SG_ 881 RCM_a075_comCHCANPH6 "Restraint control module: a075 com CHCANPH6";
CM_ SG_ 881 RCM_a076_comEPBLStatus "Restraint control module: a076 com EPBL status";
CM_ SG_ 881 RCM_a077_comEPBRStatus "Restraint control module: a077 com EPBR status";
CM_ SG_ 881 RCM_a078_comOCS1PStatus "Restraint control module: a078 com OCS1 p status";
CM_ SG_ 881 RCM_a079_comOCS1DStatus "Restraint control module: a079 com OCS1 d status";
CM_ SG_ 881 RCM_a080_comGTWACS "Restraint control module: a080 com GTWACS";
CM_ SG_ 881 RCM_a081_comVCFRONTLVPwr "Restraint control module: a081 com VCFRONTLV pwr";
CM_ SG_ 881 RCM_a082_comUIodo "Restraint control module: a082 com u iodo";
CM_ SG_ 881 RCM_a083_comGTWCarState "Restraint control module: a083 com GTW car state";
CM_ SG_ 881 RCM_a084_comTPMSStatus "Restraint control module: a084 com TPMS status";
CM_ SG_ 881 RCM_a085_comGTWCarConfig "Restraint control module: a085 com GTW car config";
CM_ SG_ 881 RCM_a086_comVINMIA "Restraint control module: a086 com VINMIA";
CM_ SG_ 881 RCM_a087_comCANSilent "Restraint control module: a087 com CAN silent";
CM_ SG_ 881 RCM_a088_comCHCANPH2 "Restraint control module: a088 com CHCANPH2";
CM_ SG_ 881 RCM_a089_comCHCANPH3 "Restraint control module: a089 com CHCANPH3";
CM_ SG_ 881 RCM_a090_comPartyBusOff "Restraint control module: a090 com party bus off";
CM_ SG_ 881 RCM_a091_comEPAS3PsysStatus "Restraint control module: a091 com EPAS3 psys status";
CM_ SG_ 881 RCM_a092_comDASISF "Restraint control module: a092 com DASISF";
CM_ SG_ 881 RCM_a093_comVCLEFTStatus "Restraint control module: a093 com VCLEFT status";
CM_ SG_ 881 RCM_a094_comVCRIGHTStatus "Restraint control module: a094 com VCRIGHT status";
CM_ SG_ 881 RCM_a095_comESPstatus "Restraint control module: a095 com ES pstatus";
CM_ SG_ 881 RCM_a096_comESPwheelSpeeds "Restraint control module: a096 com ES pwheel speeds";
CM_ SG_ 881 RCM_a097_comDIspeed "Restraint control module: a097 com d ispeed";
CM_ SG_ 881 RCM_a098_comDIchassisControl "Restraint control module: a098 com d ichassis control";
CM_ SG_ 881 RCM_a099_comDItorque "Restraint control module: a099 com d itorque";
CM_ SG_ 881 RCM_a100_comDIsystemStatus "Restraint control module: a100 com d isystem status";
CM_ SG_ 881 RCM_a101_idfSystem "Restraint control module: a101 idf system";
CM_ SG_ 881 RCM_a102_imuYawR8OffstCompLim "Restraint control module: a102 imu yaw R8 offst comp lim";
CM_ SG_ 881 RCM_a103_imuPtchR8OffstCompLim "Restraint control module: a103 imu ptch R8 offst comp lim";
CM_ SG_ 881 RCM_a104_imuRollR8OffstCompLim "Restraint control module: a104 imu roll R8 offst comp lim";
CM_ SG_ 881 RCM_a105_imuLongAccOffstCompLim "Restraint control module: a105 imu long acc offst comp lim";
CM_ SG_ 881 RCM_a106_imuLatAccOffstCompLim "Restraint control module: a106 imu lat acc offst comp lim";
CM_ SG_ 881 RCM_a107_imuVertAccOffstCompLim "Restraint control module: a107 imu vert acc offst comp lim";
CM_ SG_ 881 RCM_a108_crashAlgoWakeup "Restraint control module: a108 crash algo wakeup";
CM_ SG_ 881 RCM_a109_abuseImmunity "Restraint control module: a109 abuse immunity";
CM_ SG_ 881 RCM_a110_factoryMode "Restraint control module: a110 factory mode";
CM_ SG_ 881 RCM_a111_diagnosticsEnabled "Restraint control module: a111 diagnostics enabled";
CM_ SG_ 881 RCM_a112_imuYawRate "Restraint control module: a112 imu yaw rate";
CM_ SG_ 881 RCM_a113_imuPitchRate "Restraint control module: a113 imu pitch rate";
CM_ SG_ 881 RCM_a114_imuRollRate "Restraint control module: a114 imu roll rate";
CM_ SG_ 881 RCM_a115_imuLinearAcceleration "Restraint control module: a115 imu linear acceleration";
CM_ SG_ 881 RCM_a116_imuLateralAcceleration "Restraint control module: a116 imu lateral acceleration";
CM_ SG_ 881 RCM_a117_imuVerticalAcceleration "Restraint control module: a117 imu vertical acceleration";
CM_ SG_ 881 RCM_a118_imuInPlaneAcceleration "Restraint control module: a118 imu in plane acceleration";
CM_ BO_ 17 "Restraint control module message: collision";
CM_ SG_ 17 RCM_collisionChecksum "Restraint control module: collision checksum";
CM_ SG_ 17 RCM_collisionCounter "Restraint control module: collision counter";
CM_ SG_ 17 RCM_collisionRear "Indicates that a rear collision occurred";
CM_ SG_ 17 RCM_collisionRight "Indicates that a right side collision occurred";
CM_ SG_ 17 RCM_collisionLeft "Indicates that a left side collision occurred";
CM_ SG_ 17 RCM_collisionFront "Indicates that a frontal collision occurred";
CM_ SG_ 17 RCM_collisionRollover "Indicates that a rollover has occurred";
CM_ SG_ 17 RCM_collisionPedPro "Indicates that a pedestrian impact has occurred";
CM_ SG_ 17 RCM_collisionSeverity "Collision severity";
CM_ BO_ 257 "Restraint control module message: inertial1";
CM_ SG_ 257 RCM_yawRate "Offset compensated yaw rate measured by the airbag ECU. ISO axis convention (Positive during left turn)";
CM_ SG_ 257 RCM_pitchRate "Offset compensated pitch rate measured by the airbag ECU. ISO axis convention (positive when the nose pitches down)";
CM_ SG_ 257 RCM_rollRate "Offset compensated roll rate measured by the airbag ECU. ISO axis convention (positive during left turn)";
CM_ SG_ 257 RCM_rollRateQF "Restraint control module: roll rate QF";
CM_ SG_ 257 RCM_yawRateQF "Restraint control module: yaw rate QF";
CM_ SG_ 257 RCM_pitchRateQF "Restraint control module: pitch rate QF";
CM_ SG_ 257 RCM_inertial1Counter "Restraint control module: inertial1 counter";
CM_ SG_ 257 RCM_inertial1Checksum "Restraint control module: inertial1 checksum";
CM_ BO_ 278 "Restraint control module message: inertial2";
CM_ SG_ 278 RCM_longitudinalAccel "Offset compensated longitudinal acceleration measured by the airbag ECU. ISO axis convention (positive during forward acceleration)";
CM_ SG_ 278 RCM_lateralAccel "Reports offset compensated lateral acceleration measured by the airbag ECU. Follows ISO axis convention that measurements are positive during left turns and negative during right turns.";
CM_ SG_ 278 RCM_verticalAccel "Offset compensated vertical acceleration measured by the airbag ECU. ISO axis convention (positive up)";
CM_ SG_ 278 RCM_longitudinalAccelQF "Restraint control module: longitudinal accel QF";
CM_ SG_ 278 RCM_lateralAccelQF "Restraint control module: lateral accel QF";
CM_ SG_ 278 RCM_verticalAccelQF "Restraint control module: vertical accel QF";
CM_ SG_ 278 RCM_CGTranslationFault "Restraint control module: CG translation fault";
CM_ SG_ 278 RCM_inertial2Counter "Restraint control module: inertial2 counter";
CM_ SG_ 278 RCM_inertial2Checksum "Restraint control module: inertial2 checksum";
CM_ BO_ 849 "Restraint control module message: info";
CM_ SG_ 849 RCM_infoIndex "Restraint control module: info index";
CM_ SG_ 849 RCM_infoBuildType "Restraint control module: info build type";
CM_ SG_ 849 RCM_infoComponentID "Restraint control module: info component ID";
CM_ SG_ 849 RCM_infoPcbaID "Reports the Restraint Control Module (RCM) Printed Circuit Board Assembly (PCBA) identifier.";
CM_ SG_ 849 RCM_infoAssemblyID "Restraint control module: info assembly ID";
CM_ SG_ 849 RCM_infoUsageID "Reports the Restraint Control Module (RCM) usage identification.";
CM_ SG_ 849 RCM_infoApplicationCRC "Reports the Restraint Control Module (RCM) application Cyclic Redundancy Check (CRC).";
CM_ SG_ 849 RCM_infoBootUdsProtoVersion "Reports the Restraint Control Module (RCM) boot Unified Diagnostic Services (UDS) protocol version.";
CM_ SG_ 849 RCM_infoBootloaderCRC "Reports the Restraint Control Module (RCM) bootloader Cyclic Redundancy Check (CRC).";
CM_ SG_ 849 RCM_infoAlgoCalID "Reports the Restraint Control Module (RCM) algorithm calibration identification.";
CM_ SG_ 849 RCM_infoVariantCRC "Reports the Restraint Control Module (RCM) variant Cyclic Redundancy Check (CRC).";
CM_ BO_ 2032 "Restraint control module message: near deploy";
CM_ SG_ 2032 RCM_nearDeployChecksum "Restraint control module: near deploy checksum";
CM_ SG_ 2032 RCM_nearDeployCounter "Restraint control module: near deploy counter";
CM_ SG_ 2032 RCM_nearDeployRear "Indicates that a rear near deploy event has occurred. No airbags have been deployed.";
CM_ SG_ 2032 RCM_nearDeployRight "Indicates that a right side near deploy event has occurred. No airbags have been deployed.";
CM_ SG_ 2032 RCM_nearDeployLeft "Indicates that a left side near deploy event has occurred. No airbags have been deployed.";
CM_ SG_ 2032 RCM_nearDeployFront "Indicates that a frontal near deploy event has occurred. No airbags have been deployed.";
CM_ SG_ 2032 RCM_nearDeployRollover "Indicates that a roll over near deploy event has occurred. No airbags have been deployed.";
CM_ SG_ 2032 RCM_crashAlgoWakeup "Crash Algorithm Wakeup status";
CM_ BO_ 529 "Restraint control module message: status";
CM_ SG_ 529 RCM_statusChecksum "Restraint control module: status checksum";
CM_ SG_ 529 RCM_statusCounter "Restraint control module: status counter";
CM_ SG_ 529 RCM_armStatus "Reports the arm status of the Restraint Control Module (RCM).";
CM_ SG_ 529 RCM_warningIndicatorState "Reports whether the Restraint Control Module (RCM) warning indicator is present on the User Interface (UI).";
CM_ SG_ 529 RCM_passAirbagIndicatorRequest "Reports status of the Front Passenger Airbag Off telltale.";
CM_ SG_ 529 RCM_airbagCutoffStatus "Reports the front passenger airbag enabled or disabled status.";
CM_ SG_ 529 RCM_alrSwitchStatus "Reports status of the front passenger automatic locking seat belt retractor.";
CM_ SG_ 529 RCM_vinLearnFlag "Reports whether the Vehicle Identification Number has been learned.";
CM_ SG_ 529 RCM_seatTrackPositionDrvr "Driver seat track position status";
CM_ SG_ 529 RCM_seatTrackPositionPass "Passenger seat track position status";
CM_ SG_ 529 RCM_edr1State "Reports status of Restraint Control Module (RCM) Event Data Recorder (EDR) memory slot 1.";
CM_ SG_ 529 RCM_edr2State "Reports status of Restraint Control Module (RCM) Event Data Recorder (EDR) memory slot 2.";
CM_ SG_ 529 RCM_keepPowerReason "Restraint Control Module request to maintain power";
CM_ SG_ 529 RCM_imuOffsetLearnState "Restraint control module: imu offset learn state";
CM_ SG_ 529 RCM_edr3State "Reports status of Restraint Control Module (RCM) Event Data Recorder (EDR) memory slot 3.";
CM_ SG_ 529 RCM_driverOrientationInitStatus "Restraint control module: driver orientation init status";
CM_ SG_ 529 RCM_occupantClassificationSource "Indicates whether the occupant classification source is the Right Vehicle Controller (VCRIGHT) or the Occupancy Classification System - 1st Row Passenger (OCS1P).";
CM_ SG_ 529 RCM_pedProEDR1State "Reports status of the PedPro Event Data Recorder (EDR) memory slot 1.";
CM_ SG_ 529 RCM_pedProEDR2State "Reports status of the PedPro Event Data Recorder (EDR) memory slot 2.";
CM_ BO_ 1471 "RCU ECU message: alert log";
CM_ SG_ 1471 RCU_alertID "RCU ECU: alert ID";
CM_ SG_ 1471 RCU_alertState "RCU ECU: alert state";
CM_ SG_ 1471 RCU_a010_sensorPowerSupply "RCU ECU: a010 sensor power supply";
CM_ SG_ 1471 RCU_a010_sensorHardware "RCU ECU: a010 sensor hardware";
CM_ SG_ 1471 RCU_a010_sensorSignal "RCU ECU: a010 sensor signal";
CM_ SG_ 1471 RCU_a023_validityOnChassisBus "RCU ECU: a023 validity on chassis bus";
CM_ SG_ 1471 RCU_a023_validityOnPartyBus "RCU ECU: a023 validity on party bus";
CM_ SG_ 1471 RCU_a024_validityOnChassisBus "RCU ECU: a024 validity on chassis bus";
CM_ SG_ 1471 RCU_a024_validityOnPartyBus "RCU ECU: a024 validity on party bus";
CM_ SG_ 1471 RCU_a025_validityOnChassisBus "RCU ECU: a025 validity on chassis bus";
CM_ SG_ 1471 RCU_a025_validityOnPartyBus "RCU ECU: a025 validity on party bus";
CM_ SG_ 1471 RCU_a035_validityOnChassisBus "RCU ECU: a035 validity on chassis bus";
CM_ SG_ 1471 RCU_a035_validityOnPartyBus "RCU ECU: a035 validity on party bus";
CM_ SG_ 1471 RCU_a036_validityOnChassisBus "RCU ECU: a036 validity on chassis bus";
CM_ SG_ 1471 RCU_a036_validityOnPartyBus "RCU ECU: a036 validity on party bus";
CM_ BO_ 998 "RCU ECU message: alert matrix";
CM_ SG_ 998 RCU_matrixIndex "RCU ECU: matrix index";
CM_ SG_ 998 RCU_a001_valveDriverFault "RCU ECU: a001 valve driver fault";
CM_ SG_ 998 RCU_a002_solenoidValveFault "RCU ECU: a002 solenoid valve fault";
CM_ SG_ 998 RCU_a003_pumpMotorFault "RCU ECU: a003 pump motor fault";
CM_ SG_ 998 RCU_a004_supplyOvervoltage "RCU ECU: a004 supply overvoltage";
CM_ SG_ 998 RCU_a005_supplyUndervoltage "RCU ECU: a005 supply undervoltage";
CM_ SG_ 998 RCU_a006_wakeLineOpen "RCU ECU: a006 wake line open";
CM_ SG_ 998 RCU_a007_pressureSensorFault "RCU ECU: a007 pressure sensor fault";
CM_ SG_ 998 RCU_a008_pressureNotCalibrated "RCU ECU: a008 pressure not calibrated";
CM_ SG_ 998 RCU_a009_brakeFluidLow "RCU ECU: a009 brake fluid low";
CM_ SG_ 998 RCU_a010_pedalSensorFault "RCU ECU: a010 pedal sensor fault";
CM_ SG_ 998 RCU_a011_idbPedalTravelMismatch "RCU ECU: a011 idb pedal travel mismatch";
CM_ SG_ 998 RCU_a012_pedalSensorNotCal "RCU ECU: a012 pedal sensor not cal";
CM_ SG_ 998 RCU_a013_mcuGenericFault "RCU ECU: a013 mcu generic fault";
CM_ SG_ 998 RCU_a014_asicTempHigh "RCU ECU: a014 asic temp high";
CM_ SG_ 998 RCU_a015_fluidLeakDetected "RCU ECU: a015 fluid leak detected";
CM_ SG_ 998 RCU_a016_partyBusOff "RCU ECU: a016 party bus off";
CM_ SG_ 998 RCU_a017_chassisBusOff "RCU ECU: a017 chassis bus off";
CM_ SG_ 998 RCU_a018_DItorquePathFaulted "RCU ECU: a018 d itorque path faulted";
CM_ SG_ 998 RCU_a019_DItorquePathActive "RCU ECU: a019 d itorque path active";
CM_ SG_ 998 RCU_a020_BBstatusDLC "RCU ECU: a020 b bstatus DLC";
CM_ SG_ 998 RCU_a021_BBstatusChecksum "RCU ECU: a021 b bstatus checksum";
CM_ SG_ 998 RCU_a022_BBstatusCounter "RCU ECU: a022 b bstatus counter";
CM_ SG_ 998 RCU_a023_IDBstatusDLC "RCU ECU: a023 ID bstatus DLC";
CM_ SG_ 998 RCU_a024_IDBstatusChecksum "RCU ECU: a024 ID bstatus checksum";
CM_ SG_ 998 RCU_a025_IDBstatusCounter "RCU ECU: a025 ID bstatus counter";
CM_ SG_ 998 RCU_a026_DIchassisControlDLC "RCU ECU: a026 d ichassis control DLC";
CM_ SG_ 998 RCU_a027_DIchassisCtrlChecksum "RCU ECU: a027 d ichassis ctrl checksum";
CM_ SG_ 998 RCU_a028_DIchassisControlCounter "RCU ECU: a028 d ichassis control counter";
CM_ SG_ 998 RCU_a029_PMstate2DLC "RCU ECU: a029 p mstate2 DLC";
CM_ SG_ 998 RCU_a030_PMstate2Checksum "RCU ECU: a030 p mstate2 checksum";
CM_ SG_ 998 RCU_a031_PMstate2Counter "RCU ECU: a031 p mstate2 counter";
CM_ SG_ 998 RCU_a032_VCFRONTLVPowerStateDLC "RCU ECU: a032 VCFRONTLV power state DLC";
CM_ SG_ 998 RCU_a033_VCFRONTLVPowerStateChec "RCU ECU: a033 VCFRONTLV power state checksum";
CM_ SG_ 998 RCU_a034_VCFRONTLVPowerStateCoun "RCU ECU: a034 VCFRONTLV power state counter";
CM_ SG_ 998 RCU_a035_IDBpcpInvalid "RCU ECU: a035 ID bpcp invalid";
CM_ SG_ 998 RCU_a036_IDBpspInvalid "RCU ECU: a036 ID bpsp invalid";
CM_ SG_ 998 RCU_a037_IDBinputRodStrokeInvali "RCU ECU: a037 ID binput rod stroke invalid";
CM_ SG_ 998 RCU_a038_DIsystemStatusDLC "RCU ECU: a038 d isystem status DLC";
CM_ SG_ 998 RCU_a039_DIaccelPosInvalid "RCU ECU: a039 d iaccel pos invalid";
CM_ SG_ 998 RCU_a040_DIgearInvalid "RCU ECU: a040 d igear invalid";
CM_ SG_ 998 RCU_a041_DIsystemStatusCounter "RCU ECU: a041 d isystem status counter";
CM_ SG_ 998 RCU_a042_DIsystemStatusChecksum "RCU ECU: a042 d isystem status checksum";
CM_ SG_ 998 RCU_a043_VCFRONTiBoosterLvStateI "RCU ECU: a043 VCFRON ti booster lv state invalid";
CM_ SG_ 998 RCU_a044_VCFRONTsensorsMIA "RCU ECU: a044 VCFRON tsensors MIA";
CM_ SG_ 998 RCU_a045_VCFRONTtempInvalid "RCU ECU: a045 VCFRON ttemp invalid";
CM_ SG_ 998 RCU_a046_brakeFluidLevelSNA "RCU ECU: a046 brake fluid level SNA";
CM_ SG_ 998 RCU_a047_ESPwheelSpeedsDLC "RCU ECU: a047 ES pwheel speeds DLC";
CM_ SG_ 998 RCU_a048_ESPFrLWSSLInvalid "RCU ECU: a048 ESP fr LWSSL invalid";
CM_ SG_ 998 RCU_a049_ESPFrRWSSLInvalid "RCU ECU: a049 ESP fr RWSSL invalid";
CM_ SG_ 998 RCU_a050_ESPReLWSSLInvalid "RCU ECU: a050 ESP re LWSSL invalid";
CM_ SG_ 998 RCU_a051_ESPReRWSSLInvalid "RCU ECU: a051 ESP re RWSSL invalid";
CM_ SG_ 998 RCU_a052_ESPwheelSpeedsCounter "RCU ECU: a052 ES pwheel speeds counter";
CM_ SG_ 998 RCU_a053_ESPwheelSpeedsChecksum "RCU ECU: a053 ES pwheel speeds checksum";
CM_ SG_ 998 RCU_a054_IDBcircuitPressFaulted "RCU ECU: a054 ID bcircuit press faulted";
CM_ SG_ 998 RCU_a055_IDBsimulatorPressFaulte "RCU ECU: a055 ID bsimulator press faulted";
CM_ SG_ 998 RCU_a056_redundantControllerIsMa "RCU ECU: a056 redundant controller is master";
CM_ SG_ 998 RCU_a057_DASredundantBrakingCont "RCU ECU: a057 DA sredundant braking control DLC";
CM_ SG_ 998 RCU_a058_DASredundantBrakingCont "RCU ECU: a058 DA sredundant braking control counter";
CM_ SG_ 998 RCU_a059_DASredundantBrakingCont "RCU ECU: a059 DA sredundant braking control checksum";
CM_ SG_ 998 RCU_a060_DASbrakeTorqueCommandIn "RCU ECU: a060 DA sbrake torque command invalid";
CM_ SG_ 998 RCU_a061_DIlocStatus2DLC "RCU ECU: a061 d iloc status2 DLC";
CM_ SG_ 998 RCU_a062_DIlocStatus2Counter "RCU ECU: a062 d iloc status2 counter";
CM_ SG_ 998 RCU_a063_DIlocStatus2Checksum "RCU ECU: a063 d iloc status2 checksum";
CM_ SG_ 998 RCU_a064_ESPredundantBrakingStat "RCU ECU: a064 ES predundant braking status DLC";
CM_ SG_ 998 RCU_a065_ESPredundantBrakingStat "RCU ECU: a065 ES predundant braking status counter";
CM_ SG_ 998 RCU_a066_ESPredundantBrakingStat "RCU ECU: a066 ES predundant braking status checksum";
CM_ BO_ 831 "RCU ECU message: info";
CM_ SG_ 831 RCU_infoIndex "RCU ECU: info index";
CM_ SG_ 831 RCU_infoPcbaID "RCU ECU: info pcba ID";
CM_ SG_ 831 RCU_infoAssemblyID "RCU ECU: info assembly ID";
CM_ SG_ 831 RCU_infoUsageID "RCU ECU: info usage ID";
CM_ SG_ 831 RCU_infoSubUsageID "RCU ECU: info sub usage ID";
CM_ BO_ 1344 "Steering column control module message: alert log";
CM_ SG_ 1344 SCCM_alertID "Steering column control module: alert ID";
CM_ SG_ 1344 SCCM_alertState "Steering column control module: alert state";
CM_ SG_ 1344 SCCM_a003_debouncePosition "Steering column control module: a003 debounce position";
CM_ SG_ 1344 SCCM_a003_rawPosition "Steering column control module: a003 raw position";
CM_ SG_ 1344 SCCM_a003_errorPosition "Steering column control module: a003 error position";
CM_ SG_ 1344 SCCM_a003_adcValue "Steering column control module: a003 adc value";
CM_ SG_ 1344 SCCM_a004_debouncePosition "Steering column control module: a004 debounce position";
CM_ SG_ 1344 SCCM_a004_rawPosition "Steering column control module: a004 raw position";
CM_ SG_ 1344 SCCM_a004_errorPosition "Steering column control module: a004 error position";
CM_ SG_ 1344 SCCM_a004_adcValue "Steering column control module: a004 adc value";
CM_ SG_ 1344 SCCM_a005_debouncePosition "Steering column control module: a005 debounce position";
CM_ SG_ 1344 SCCM_a005_rawPosition "Steering column control module: a005 raw position";
CM_ SG_ 1344 SCCM_a005_errorPosition "Steering column control module: a005 error position";
CM_ SG_ 1344 SCCM_a005_adcValue "Steering column control module: a005 adc value";
CM_ SG_ 1344 SCCM_a006_debouncePosition "Steering column control module: a006 debounce position";
CM_ SG_ 1344 SCCM_a006_rawPosition "Steering column control module: a006 raw position";
CM_ SG_ 1344 SCCM_a006_errorPosition "Steering column control module: a006 error position";
CM_ SG_ 1344 SCCM_a006_adcValue "Steering column control module: a006 adc value";
CM_ SG_ 1344 SCCM_a008_debouncePosition "Steering column control module: a008 debounce position";
CM_ SG_ 1344 SCCM_a008_rawPosition "Steering column control module: a008 raw position";
CM_ SG_ 1344 SCCM_a008_errorPosition "Steering column control module: a008 error position";
CM_ SG_ 1344 SCCM_a008_adcValue1 "Steering column control module: a008 adc value1";
CM_ SG_ 1344 SCCM_a008_adcValue2 "Steering column control module: a008 adc value2";
CM_ SG_ 1344 SCCM_a009_debouncePosition "Steering column control module: a009 debounce position";
CM_ SG_ 1344 SCCM_a009_rawPosition "Steering column control module: a009 raw position";
CM_ SG_ 1344 SCCM_a009_errorPosition "Steering column control module: a009 error position";
CM_ SG_ 1344 SCCM_a009_adcValue1 "Steering column control module: a009 adc value1";
CM_ SG_ 1344 SCCM_a009_adcValue2 "Steering column control module: a009 adc value2";
CM_ SG_ 1344 SCCM_a010_debouncePosition "Steering column control module: a010 debounce position";
CM_ SG_ 1344 SCCM_a010_rawPosition "Steering column control module: a010 raw position";
CM_ SG_ 1344 SCCM_a010_errorPosition "Steering column control module: a010 error position";
CM_ SG_ 1344 SCCM_a010_adcValue1 "Steering column control module: a010 adc value1";
CM_ SG_ 1344 SCCM_a010_adcValue2 "Steering column control module: a010 adc value2";
CM_ SG_ 1344 SCCM_a011_debouncePosition "Steering column control module: a011 debounce position";
CM_ SG_ 1344 SCCM_a011_rawPosition "Steering column control module: a011 raw position";
CM_ SG_ 1344 SCCM_a011_errorPosition "Steering column control module: a011 error position";
CM_ SG_ 1344 SCCM_a011_adcValue1 "Steering column control module: a011 adc value1";
CM_ SG_ 1344 SCCM_a011_adcValue2 "Steering column control module: a011 adc value2";
CM_ SG_ 1344 SCCM_a012_debouncePosition "Steering column control module: a012 debounce position";
CM_ SG_ 1344 SCCM_a012_rawPosition "Steering column control module: a012 raw position";
CM_ SG_ 1344 SCCM_a012_errorPosition "Steering column control module: a012 error position";
CM_ SG_ 1344 SCCM_a012_adcValue1 "Steering column control module: a012 adc value1";
CM_ SG_ 1344 SCCM_a012_adcValue2 "Steering column control module: a012 adc value2";
CM_ SG_ 1344 SCCM_a021_adcValue1 "Steering column control module: a021 adc value1";
CM_ SG_ 1344 SCCM_a021_adcValue2 "Steering column control module: a021 adc value2";
CM_ SG_ 1344 SCCM_a021_adcValue3 "Steering column control module: a021 adc value3";
CM_ SG_ 1344 SCCM_a021_adcValue4 "Steering column control module: a021 adc value4";
CM_ SG_ 1344 SCCM_a021_adcValue5 "Steering column control module: a021 adc value5";
CM_ SG_ 1344 SCCM_a021_adcValue6 "Steering column control module: a021 adc value6";
CM_ SG_ 1344 SCCM_a022_adcValue1 "Steering column control module: a022 adc value1";
CM_ SG_ 1344 SCCM_a022_adcValue2 "Steering column control module: a022 adc value2";
CM_ SG_ 1344 SCCM_a022_adcValue3 "Steering column control module: a022 adc value3";
CM_ SG_ 1344 SCCM_a022_adcValue4 "Steering column control module: a022 adc value4";
CM_ SG_ 1344 SCCM_a022_adcValue5 "Steering column control module: a022 adc value5";
CM_ SG_ 1344 SCCM_a022_adcValue6 "Steering column control module: a022 adc value6";
CM_ SG_ 1344 SCCM_a023_adcValue1 "Steering column control module: a023 adc value1";
CM_ SG_ 1344 SCCM_a023_adcValue2 "Steering column control module: a023 adc value2";
CM_ SG_ 1344 SCCM_a023_adcValue3 "Steering column control module: a023 adc value3";
CM_ SG_ 1344 SCCM_a023_adcValue4 "Steering column control module: a023 adc value4";
CM_ SG_ 1344 SCCM_a023_adcValue5 "Steering column control module: a023 adc value5";
CM_ SG_ 1344 SCCM_a023_adcValue6 "Steering column control module: a023 adc value6";
CM_ SG_ 1344 SCCM_a024_adcValue1 "Steering column control module: a024 adc value1";
CM_ SG_ 1344 SCCM_a024_adcValue2 "Steering column control module: a024 adc value2";
CM_ SG_ 1344 SCCM_a024_adcValue3 "Steering column control module: a024 adc value3";
CM_ SG_ 1344 SCCM_a024_adcValue4 "Steering column control module: a024 adc value4";
CM_ SG_ 1344 SCCM_a024_adcValue5 "Steering column control module: a024 adc value5";
CM_ SG_ 1344 SCCM_a024_adcValue6 "Steering column control module: a024 adc value6";
CM_ SG_ 1344 SCCM_a026_debouncePosition "Steering column control module: a026 debounce position";
CM_ SG_ 1344 SCCM_a026_rawPosition "Steering column control module: a026 raw position";
CM_ SG_ 1344 SCCM_a026_errorPosition "Steering column control module: a026 error position";
CM_ SG_ 1344 SCCM_a026_adcValue1 "Steering column control module: a026 adc value1";
CM_ SG_ 1344 SCCM_a026_adcValue2 "Steering column control module: a026 adc value2";
CM_ SG_ 1344 SCCM_a027_debouncePosition "Steering column control module: a027 debounce position";
CM_ SG_ 1344 SCCM_a027_rawPosition "Steering column control module: a027 raw position";
CM_ SG_ 1344 SCCM_a027_errorPosition "Steering column control module: a027 error position";
CM_ SG_ 1344 SCCM_a027_adcValue1 "Steering column control module: a027 adc value1";
CM_ SG_ 1344 SCCM_a027_adcValue2 "Steering column control module: a027 adc value2";
CM_ SG_ 1344 SCCM_a028_debouncePosition "Steering column control module: a028 debounce position";
CM_ SG_ 1344 SCCM_a028_rawPosition "Steering column control module: a028 raw position";
CM_ SG_ 1344 SCCM_a028_errorPosition "Steering column control module: a028 error position";
CM_ SG_ 1344 SCCM_a028_adcValue1 "Steering column control module: a028 adc value1";
CM_ SG_ 1344 SCCM_a028_adcValue2 "Steering column control module: a028 adc value2";
CM_ SG_ 1344 SCCM_a029_debouncePosition "Steering column control module: a029 debounce position";
CM_ SG_ 1344 SCCM_a029_rawPosition "Steering column control module: a029 raw position";
CM_ SG_ 1344 SCCM_a029_errorPosition "Steering column control module: a029 error position";
CM_ SG_ 1344 SCCM_a029_adcValue1 "Steering column control module: a029 adc value1";
CM_ SG_ 1344 SCCM_a029_adcValue2 "Steering column control module: a029 adc value2";
CM_ SG_ 1344 SCCM_a061_voltage "Steering column control module: a061 voltage";
CM_ SG_ 1344 SCCM_a062_voltage "Steering column control module: a062 voltage";
CM_ SG_ 1344 SCCM_a063_UntrimmedAngle "Steering column control module: a063 untrimmed angle";
CM_ SG_ 1344 SCCM_a064_Speed "Steering column control module: a064 speed";
CM_ SG_ 1344 SCCM_a065_M1RawAngleCurrent "Steering column control module: a065 M1 raw angle current";
CM_ SG_ 1344 SCCM_a065_M1RawAnglePrevious "Steering column control module: a065 M1 raw angle previous";
CM_ SG_ 1344 SCCM_a065_M2RawAngleCurrent "Steering column control module: a065 M2 raw angle current";
CM_ SG_ 1344 SCCM_a065_M2RawAnglePrevious "Steering column control module: a065 M2 raw angle previous";
CM_ SG_ 1344 SCCM_a066_M1RawAngleCurrent "Steering column control module: a066 M1 raw angle current";
CM_ SG_ 1344 SCCM_a066_M1RawAnglePrevious "Steering column control module: a066 M1 raw angle previous";
CM_ SG_ 1344 SCCM_a066_M2RawAngleCurrent "Steering column control module: a066 M2 raw angle current";
CM_ SG_ 1344 SCCM_a066_M2RawAnglePrevious "Steering column control module: a066 M2 raw angle previous";
CM_ SG_ 1344 SCCM_a071_M1LogicBISTFailed "Steering column control module: a071 M1 logic BIST failed";
CM_ SG_ 1344 SCCM_a071_M1PowerOnReset "Steering column control module: a071 M1 power on reset";
CM_ SG_ 1344 SCCM_a071_M1UnderVoltage "Steering column control module: a071 M1 under voltage";
CM_ SG_ 1344 SCCM_a071_M1OverVoltage "Steering column control module: a071 M1 over voltage";
CM_ SG_ 1344 SCCM_a071_M1DualBitError "Steering column control module: a071 M1 dual bit error";
CM_ SG_ 1344 SCCM_a071_M1RefVoltageOutOfRange "Steering column control module: a071 M1 ref voltage out of range";
CM_ SG_ 1344 SCCM_a071_M1RegisterParityError "Steering column control module: a071 M1 register parity error";
CM_ SG_ 1344 SCCM_a071_M1OscillatorFreqError "Steering column control module: a071 M1 oscillator freq error";
CM_ SG_ 1344 SCCM_a071_M1SignalOutOfRange "Steering column control module: a071 M1 signal out of range";
CM_ SG_ 1344 SCCM_a071_M1TempOutOfRange "Steering column control module: a071 M1 temp out of range";
CM_ SG_ 1344 SCCM_a071_M1AngleMismatch "Steering column control module: a071 M1 angle mismatch";
CM_ SG_ 1344 SCCM_a071_M1RadiusOutOfRange "Steering column control module: a071 M1 radius out of range";
CM_ SG_ 1344 SCCM_a071_M2LogicBISTFailed "Steering column control module: a071 M2 logic BIST failed";
CM_ SG_ 1344 SCCM_a071_M2PowerOnReset "Steering column control module: a071 M2 power on reset";
CM_ SG_ 1344 SCCM_a071_M2UnderVoltage "Steering column control module: a071 M2 under voltage";
CM_ SG_ 1344 SCCM_a071_M2OverVoltage "Steering column control module: a071 M2 over voltage";
CM_ SG_ 1344 SCCM_a071_M2DualBitError "Steering column control module: a071 M2 dual bit error";
CM_ SG_ 1344 SCCM_a071_M2RefVoltageOutOfRange "Steering column control module: a071 M2 ref voltage out of range";
CM_ SG_ 1344 SCCM_a071_M2RegisterParityError "Steering column control module: a071 M2 register parity error";
CM_ SG_ 1344 SCCM_a071_M2OscillatorFreqError "Steering column control module: a071 M2 oscillator freq error";
CM_ SG_ 1344 SCCM_a071_M2SignalOutOfRange "Steering column control module: a071 M2 signal out of range";
CM_ SG_ 1344 SCCM_a071_M2TempOutOfRange "Steering column control module: a071 M2 temp out of range";
CM_ SG_ 1344 SCCM_a071_M2AngleMismatch "Steering column control module: a071 M2 angle mismatch";
CM_ SG_ 1344 SCCM_a071_M2RadiusOutOfRange "Steering column control module: a071 M2 radius out of range";
CM_ SG_ 1344 SCCM_a071_M1ProcessLogicFailed "Steering column control module: a071 M1 process logic failed";
CM_ SG_ 1344 SCCM_a071_M2ProcessLogicFailed "Steering column control module: a071 M2 process logic failed";
CM_ SG_ 1344 SCCM_a071_TSOSCHighFreqError "Steering column control module: a071 TSOSC high freq error";
CM_ SG_ 1344 SCCM_a071_TSOSCLowFreqError "Steering column control module: a071 TSOSC low freq error";
CM_ SG_ 1344 SCCM_a071_TSOPRStatMismatch "Steering column control module: a071 TSOPR stat mismatch";
CM_ SG_ 1344 SCCM_a071_TSCRCStatError "Steering column control module: a071 TSCRC stat error";
CM_ SG_ 1344 SCCM_a071_TSFrameStatError "Steering column control module: a071 TS frame stat error";
CM_ SG_ 1344 SCCM_a071_TSOverVoltage "Steering column control module: a071 TS over voltage";
CM_ SG_ 1344 SCCM_a071_TSUnderVoltage "Steering column control module: a071 TS under voltage";
CM_ SG_ 1344 SCCM_a071_TSPowerOnReset "Steering column control module: a071 TS power on reset";
CM_ SG_ 1344 SCCM_a071_TSLDOStatError "Steering column control module: a071 TSLDO stat error";
CM_ SG_ 1344 SCCM_a071_TSTempOutOfRange "Steering column control module: a071 TS temp out of range";
CM_ SG_ 1344 SCCM_a071_TSAlertIntegrityCheck "Steering column control module: a071 TS alert integrity check";
CM_ SG_ 1344 SCCM_a071_TSMemoryCRCError "Steering column control module: a071 TS memory CRC error";
CM_ SG_ 1344 SCCM_a071_TSAFECheck "Steering column control module: a071 TSAFE check";
CM_ SG_ 1344 SCCM_a071_TSADCCheck "Steering column control module: a071 TSADC check";
CM_ SG_ 1344 SCCM_a071_TSConfigFault "Steering column control module: a071 TS config fault";
CM_ SG_ 1344 SCCM_a072_M1CRCCalculated "Steering column control module: a072 M1 CRC calculated";
CM_ SG_ 1344 SCCM_a072_M1CRCReceived "Steering column control module: a072 M1 CRC received";
CM_ SG_ 1344 SCCM_a072_M2CRCCalculated "Steering column control module: a072 M2 CRC calculated";
CM_ SG_ 1344 SCCM_a072_M2CRCReceived "Steering column control module: a072 M2 CRC received";
CM_ SG_ 1344 SCCM_a072_TSCRCCalculated "Steering column control module: a072 TSCRC calculated";
CM_ SG_ 1344 SCCM_a072_TSCRCReceived "Steering column control module: a072 TSCRC received";
CM_ SG_ 1344 SCCM_a075_ClockOutOfRange "Steering column control module: a075 clock out of range";
CM_ SG_ 1344 SCCM_a075_ExtWatchdogTestFailed "Steering column control module: a075 ext watchdog test failed";
CM_ SG_ 1344 SCCM_a075_InterruptMonitorError "Steering column control module: a075 interrupt monitor error";
CM_ SG_ 1344 SCCM_a076_RAMTestFailed "Steering column control module: a076 RAM test failed";
CM_ SG_ 1344 SCCM_a076_NVMTestFailed "Steering column control module: a076 NVM test failed";
CM_ SG_ 1344 SCCM_a077_M1ExpectAngleCurrent "Steering column control module: a077 M1 expect angle current";
CM_ SG_ 1344 SCCM_a077_M1ExpectAnglePrevious "Steering column control module: a077 M1 expect angle previous";
CM_ SG_ 1344 SCCM_a077_M1AngleCurrent "Steering column control module: a077 M1 angle current";
CM_ SG_ 1344 SCCM_a077_M1AnglePrevious "Steering column control module: a077 M1 angle previous";
CM_ SG_ 1344 SCCM_a079_ChipTemperature "Steering column control module: a079 chip temperature";
CM_ SG_ 1344 SCCM_a081_StartupTestStatus "Steering column control module: a081 startup test status";
CM_ SG_ 1344 SCCM_a081_sCheckTestFailedData "Steering column control module: a081 s check test failed data";
CM_ SG_ 1344 SCCM_a081_sBootTestFailedData "Steering column control module: a081 s boot test failed data";
CM_ SG_ 1344 SCCM_a081_BISTTestFailedData "Steering column control module: a081 BIST test failed data";
CM_ SG_ 1344 SCCM_a082_RuntimeTestStatus "Steering column control module: a082 runtime test status";
CM_ SG_ 1344 SCCM_a082_sCheckTestFailedData "Steering column control module: a082 s check test failed data";
CM_ SG_ 1344 SCCM_a082_ArrayIntegrFailedData "Steering column control module: a082 array integr failed data";
CM_ SG_ 1344 SCCM_a121_turnIndicatorStalkAngl "Steering column control module: a121 turn indicator stalk angle";
CM_ SG_ 1344 SCCM_a121_turnIndicatorHallAngle "Steering column control module: a121 turn indicator hall angle";
CM_ SG_ 1344 SCCM_a122_turnIndicatorSpeed "Steering column control module: a122 turn indicator speed";
CM_ SG_ 1344 SCCM_a123_turnIndicatorStalkAngl "Steering column control module: a123 turn indicator stalk angle";
CM_ SG_ 1344 SCCM_a124_turnIndicatorStalkAngl "Steering column control module: a124 turn indicator stalk angle";
CM_ SG_ 1344 SCCM_a125_turnIndicatorHallAngle "Steering column control module: a125 turn indicator hall angle";
CM_ SG_ 1344 SCCM_a125_turnIndicatorVectorAng "Steering column control module: a125 turn indicator vector angle";
CM_ SG_ 1344 SCCM_a126_turnIndicatorXVectorOu "Steering column control module: a126 turn indicator x vector out of range";
CM_ SG_ 1344 SCCM_a126_turnIndicatorYVectorOu "Steering column control module: a126 turn indicator y vector out of range";
CM_ SG_ 1344 SCCM_a126_turnIndicatorZVectorOu "Steering column control module: a126 turn indicator z vector out of range";
CM_ SG_ 1344 SCCM_a126_turnIndicatorResu_0001 "Steering column control module: a126 turn indicator resultant out of range";
CM_ SG_ 1344 SCCM_a126_turnIndicatorXMagnitud "Steering column control module: a126 turn indicator x magnitude";
CM_ SG_ 1344 SCCM_a126_turnIndicatorYMagnitud "Steering column control module: a126 turn indicator y magnitude";
CM_ SG_ 1344 SCCM_a126_turnIndicatorZMagnitud "Steering column control module: a126 turn indicator z magnitude";
CM_ SG_ 1344 SCCM_a126_turnIndicatorResultant "Steering column control module: a126 turn indicator resultant magnitude";
CM_ BO_ 1359 "Steering column control module message: alert matrix";
CM_ SG_ 1359 SCCM_matrixIndex "Steering column control module: matrix index";
CM_ SG_ 1359 SCCM_a001_CANBusOff "Steering column control module: a001 CAN bus off";
CM_ SG_ 1359 SCCM_a002_CANTOut "Steering column control module: a002 CANT out";
CM_ SG_ 1359 SCCM_a003_highBeamOpen "Steering column control module: a003 high beam open";
CM_ SG_ 1359 SCCM_a004_highBeamShortToGND "Steering column control module: a004 high beam short to GND";
CM_ SG_ 1359 SCCM_a005_tipWipeOpen "Steering column control module: a005 tip wipe open";
CM_ SG_ 1359 SCCM_a006_tipWipeShortToGND "Steering column control module: a006 tip wipe short to GND";
CM_ SG_ 1359 SCCM_a007_turnIndComInfo "Steering column control module: a007 turn ind com info";
CM_ SG_ 1359 SCCM_a008_turnIndInvalidTrans "Steering column control module: a008 turn ind invalid trans";
CM_ SG_ 1359 SCCM_a009_turnIndOpen "Steering column control module: a009 turn ind open";
CM_ SG_ 1359 SCCM_a010_turnIndShortToGnd "Steering column control module: a010 turn ind short to gnd";
CM_ SG_ 1359 SCCM_a011_turnIndHWErr "Steering column control module: a011 turn ind HW err";
CM_ SG_ 1359 SCCM_a012_turnGenErr "Steering column control module: a012 turn gen err";
CM_ SG_ 1359 SCCM_a013_voltageHigh "Steering column control module: a013 voltage high";
CM_ SG_ 1359 SCCM_a014_voltageLow "Steering column control module: a014 voltage low";
CM_ SG_ 1359 SCCM_a015_softwareError "Steering column control module: a015 software error";
CM_ SG_ 1359 SCCM_a016_hardwareError "Steering column control module: a016 hardware error";
CM_ SG_ 1359 SCCM_a017_memoryError "Steering column control module: a017 memory error";
CM_ SG_ 1359 SCCM_a018_angleSpeedOutOfRange "Steering column control module: a018 angle speed out of range";
CM_ SG_ 1359 SCCM_a019_angleOutOfRange "Steering column control module: a019 angle out of range";
CM_ SG_ 1359 SCCM_a020_angleInternalError "Steering column control module: a020 angle internal error";
CM_ SG_ 1359 SCCM_a021_gearStalkSignalInvalid "Steering column control module: a021 gear stalk signal invalid";
CM_ SG_ 1359 SCCM_a022_gearStalkOpenCircuit "Steering column control module: a022 gear stalk open circuit";
CM_ SG_ 1359 SCCM_a023_gearStalkShortCircuit "Steering column control module: a023 gear stalk short circuit";
CM_ SG_ 1359 SCCM_a024_gearStalkGenErr "Steering column control module: a024 gear stalk gen err";
CM_ SG_ 1359 SCCM_a025_runTimeError "Steering column control module: a025 run time error";
CM_ SG_ 1359 SCCM_a026_parkButtonInvalidSigna "Steering column control module: a026 park button invalid signal";
CM_ SG_ 1359 SCCM_a027_parkButtonOpenCircuit "Steering column control module: a027 park button open circuit";
CM_ SG_ 1359 SCCM_a028_parkButtonShortToGroun "Steering column control module: a028 park button short to ground";
CM_ SG_ 1359 SCCM_a029_parkButtonMalfunction "Steering column control module: a029 park button malfunction";
CM_ SG_ 1359 SCCM_a061_voltageHigh_2 "Steering column control module: a061 voltage high 2";
CM_ SG_ 1359 SCCM_a062_voltageLow_2 "Steering column control module: a062 voltage low 2";
CM_ SG_ 1359 SCCM_a063_angleOutOfRange_2 "Steering column control module: a063 angle out of range 2";
CM_ SG_ 1359 SCCM_a064_angleSpeedOutOfRange_2 "Steering column control module: a064 angle speed out of range 2";
CM_ SG_ 1359 SCCM_a065_angleNotPlausible "Steering column control module: a065 angle not plausible";
CM_ SG_ 1359 SCCM_a066_angleSpeedNotPlausible "Steering column control module: a066 angle speed not plausible";
CM_ SG_ 1359 SCCM_a067_CANBusOff_2 "Steering column control module: a067 CAN bus off 2";
CM_ SG_ 1359 SCCM_a068_CANLVPowerState_LOC "Steering column control module: a068 CANLV power state LOC";
CM_ SG_ 1359 SCCM_a069_calibrationMismatch "Steering column control module: a069 calibration mismatch";
CM_ SG_ 1359 SCCM_a070_angleTrimMismatch "Steering column control module: a070 angle trim mismatch";
CM_ SG_ 1359 SCCM_a071_angleHallSensorError "Steering column control module: a071 angle hall sensor error";
CM_ SG_ 1359 SCCM_a072_spiBitErrors "Steering column control module: a072 spi bit errors";
CM_ SG_ 1359 SCCM_a073_watchdogReset "Steering column control module: a073 watchdog reset";
CM_ SG_ 1359 SCCM_a074_PLLLossOfLock "Steering column control module: a074 PLL loss of lock";
CM_ SG_ 1359 SCCM_a075_hardwareError_2 "Steering column control module: a075 hardware error 2";
CM_ SG_ 1359 SCCM_a076_memoryError_2 "Steering column control module: a076 memory error 2";
CM_ SG_ 1359 SCCM_a077_gearAngleNotPlausible "Steering column control module: a077 gear angle not plausible";
CM_ SG_ 1359 SCCM_a078_ADCCalibrationError "Steering column control module: a078 ADC calibration error";
CM_ SG_ 1359 SCCM_a079_chipTempOutOfRange "Steering column control module: a079 chip temp out of range";
CM_ SG_ 1359 SCCM_a080_ADCSelfTestFailed "Steering column control module: a080 ADC self test failed";
CM_ SG_ 1359 SCCM_a081_startupTestFailed "Steering column control module: a081 startup test failed";
CM_ SG_ 1359 SCCM_a082_runtimeTestFailed "Steering column control module: a082 runtime test failed";
CM_ SG_ 1359 SCCM_a121_turnIndicatorAngleInva "Steering column control module: a121 turn indicator angle invalid";
CM_ SG_ 1359 SCCM_a122_turnIndicatorSpeedInva "Steering column control module: a122 turn indicator speed invalid";
CM_ SG_ 1359 SCCM_a123_turnIndicatorStuckActi "Steering column control module: a123 turn indicator stuck active";
CM_ SG_ 1359 SCCM_a124_turnIndicatorIdleInval "Steering column control module: a124 turn indicator idle invalid";
CM_ SG_ 1359 SCCM_a125_turnIndicatorHallAngle "Steering column control module: a125 turn indicator hall angle mismatch";
CM_ SG_ 1359 SCCM_a126_turnIndicatorHallMagOu "Steering column control module: a126 turn indicator hall mag out of range";
CM_ BO_ 816 "Steering column control module message: info";
CM_ SG_ 816 SCCM_infoIndex "Steering column control module: info index";
CM_ SG_ 816 SCCM_infoBuildType "Steering column control module: info build type";
CM_ SG_ 816 SCCM_infoBuildConfigId "Steering column control module: info build config id";
CM_ SG_ 816 SCCM_infoHardwareId "Steering column control module: info hardware id";
CM_ SG_ 816 SCCM_infoComponentId "Steering column control module: info component id";
CM_ SG_ 816 SCCM_infoPcbaId "Steering column control module: info pcba id";
CM_ SG_ 816 SCCM_infoAssemblyId "Steering column control module: info assembly id";
CM_ SG_ 816 SCCM_infoUsageId "Steering column control module: info usage id";
CM_ SG_ 816 SCCM_infoSubUsageId "Steering column control module: info sub usage id";
CM_ SG_ 816 SCCM_infoPlatformType "Steering column control module: info platform type";
CM_ SG_ 816 SCCM_infoAppCrc "Steering column control module: info app crc";
CM_ SG_ 816 SCCM_infoBootSvnRev "Steering column control module: info boot svn rev";
CM_ SG_ 816 SCCM_infoBootSvnUrlHash "Steering column control module: info boot svn url hash";
CM_ SG_ 816 SCCM_infoSubcomponent1Version "Steering column control module: info subcomponent1 version";
CM_ SG_ 816 SCCM_infoAppSvnHash "Steering column control module: info app svn hash";
CM_ SG_ 816 SCCM_infoBootSvnHash "Steering column control module: info boot svn hash";
CM_ SG_ 816 SCCM_infoUdsProtoVersion "Steering column control module: info uds proto version";
CM_ SG_ 816 SCCM_infoBootCrc "Steering column control module: info boot crc";
CM_ BO_ 585 "Steering column control module message: left stalk";
CM_ SG_ 585 SCCM_leftStalkCrc "Steering column control module: left stalk crc";
CM_ SG_ 585 SCCM_leftStalkCounter "Steering column control module: left stalk counter";
CM_ SG_ 585 SCCM_highBeamStalkStatus "Active state of high beam push/pull stalk position";
CM_ SG_ 585 SCCM_washWipeButtonStatus "Active state of wash/wipe button on the turn signal stalk";
CM_ SG_ 585 SCCM_turnIndicatorStalkStatus "Active state of turn indicator stalk position";
CM_ SG_ 585 SCCM_turnIndicatorStalkAngle "Measured angle of the turn signal stalk";
CM_ BO_ 553 "Steering column control module message: right stalk";
CM_ SG_ 553 SCCM_rightStalkCrc "Steering column control module: right stalk crc";
CM_ SG_ 553 SCCM_rightStalkCounter "Steering column control module: right stalk counter";
CM_ SG_ 553 SCCM_rightStalkStatus "Active state of drive stalk position, does not indicate active drive gear";
CM_ SG_ 553 SCCM_rightStalkReserved1 "Steering column control module: right stalk reserved1";
CM_ SG_ 553 SCCM_parkButtonStatus "Active state of park button on the drive stalk";
CM_ SG_ 553 SCCM_rightStalkReserved2 "Steering column control module: right stalk reserved2";
CM_ BO_ 297 "Steering column control module message: steering angle sensor";
CM_ SG_ 297 SCCM_steeringAngleCrc "Steering column control module: steering angle crc";
CM_ SG_ 297 SCCM_steeringAngleCounter "Message counter";
CM_ SG_ 297 SCCM_supplierID "Steering column control module: supplier ID";
CM_ SG_ 297 SCCM_steeringAngleSensorStatus "Reports steering angle sensor status and validity based on bootup checks";
CM_ SG_ 297 SCCM_steeringAngle "Measured ASAS sensor angle";
CM_ SG_ 297 SCCM_steeringAngleValidity "Transitions to VALID when rotation of over 4 deg has occurred";
CM_ SG_ 297 SCCM_steeringAngleSpeed "Speed of steering angle rotation";
CM_ SG_ 297 SCCM_steeringAngleSensorReservd1 "Steering column control module: steering angle sensor reservd1";
CM_ SG_ 297 SCCM_steeringAngleSensorReservd2 "Steering column control module: steering angle sensor reservd2";
CM_ SG_ 297 SCCM_steeringAngleSensorReservd3 "Steering column control module: steering angle sensor reservd3";
CM_ BO_ 1356 "SCM ECU message: alert log";
CM_ SG_ 1356 SCM_alertID "SCM ECU: alert ID";
CM_ SG_ 1356 SCM_alertType "SCM ECU: alert type";
CM_ SG_ 1356 SCM_a074_voltageWithRo "SCM ECU: a074 voltage with ro";
CM_ SG_ 1356 SCM_a074_voltageWithoutRo "SCM ECU: a074 voltage without ro";
CM_ BO_ 815 "SCM ECU message: alert matrix1";
CM_ SG_ 815 SCM_a027_externalIsolationLow "SCM ECU: a027 external isolation low";
CM_ SG_ 815 SCM_a044_proximityRationality "SCM ECU: a044 proximity rationality";
CM_ BO_ 1355 "SCM ECU message: alert matrix2";
CM_ SG_ 1355 SCM_a074_isoVDiffHi "SCM ECU: a074 iso v diff hi";
CM_ SG_ 1355 SCM_a076_bmsMIA "SCM ECU: a076 bms MIA";
CM_ SG_ 1355 SCM_a078_voltageMatchTimeout "SCM ECU: a078 voltage match timeout";
CM_ SG_ 1355 SCM_a091_voltageRiseDetection "SCM ECU: a091 voltage rise detection";
CM_ BO_ 1354 "SCS ECU message: alert log";
CM_ SG_ 1354 SCS_alertID "SCS ECU: alert ID";
CM_ SG_ 1354 SCS_alertType "SCS ECU: alert type";
CM_ SG_ 1354 SCS_a044_proximityV "SCS ECU: a044 proximity v";
CM_ SG_ 1354 SCS_a074_voltageWithRo "SCS ECU: a074 voltage with ro";
CM_ SG_ 1354 SCS_a074_voltageWithoutRo "SCS ECU: a074 voltage without ro";
CM_ BO_ 869 "SCS ECU message: alert matrix1";
CM_ SG_ 869 SCS_a001_hwDSPfault "SCS ECU: a001 hw DS pfault";
CM_ SG_ 869 SCS_a002_hwIbatOC "SCS ECU: a002 hw ibat OC";
CM_ SG_ 869 SCS_a003_hwCordOT "SCS ECU: a003 hw cord OT";
CM_ SG_ 869 SCS_a004_hwVbusOV "SCS ECU: a004 hw vbus OV";
CM_ SG_ 869 SCS_a005_hwHVIL "SCS ECU: a005 hw HVIL";
CM_ SG_ 869 SCS_a006_hwWeld_V1 "SCS ECU: a006 hw weld V1";
CM_ SG_ 869 SCS_a007_hwWeld_V2 "SCS ECU: a007 hw weld V2";
CM_ SG_ 869 SCS_a008_hwIllegalCntrShoot "SCS ECU: a008 hw illegal cntr shoot";
CM_ SG_ 869 SCS_a009_hwOpen_V1 "SCS ECU: a009 hw open V1";
CM_ SG_ 869 SCS_a010_hwOpen_V2 "SCS ECU: a010 hw open V2";
CM_ SG_ 869 SCS_a011_hwIllegalCntrCmdV1 "SCS ECU: a011 hw illegal cntr cmd V1";
CM_ SG_ 869 SCS_a012_hwIllegalCntrCmdV2 "SCS ECU: a012 hw illegal cntr cmd V2";
CM_ SG_ 869 SCS_a013_cordTempHiFoldBk "SCS ECU: a013 cord temp hi fold bk";
CM_ SG_ 869 SCS_a014_coolantTempHiFoldBk "SCS ECU: a014 coolant temp hi fold bk";
CM_ SG_ 869 SCS_a015_cpldRationality "SCS ECU: a015 cpld rationality";
CM_ SG_ 869 SCS_a016_unusedHW16 "SCS ECU: a016 unused HW16";
CM_ SG_ 869 SCS_a017_unusedHW17 "SCS ECU: a017 unused HW17";
CM_ SG_ 869 SCS_a018_unusedHW18 "SCS ECU: a018 unused HW18";
CM_ SG_ 869 SCS_a019_unusedHW19 "SCS ECU: a019 unused HW19";
CM_ SG_ 869 SCS_a020_unusedHW20 "SCS ECU: a020 unused HW20";
CM_ SG_ 869 SCS_a021_unusedHW21 "SCS ECU: a021 unused HW21";
CM_ SG_ 869 SCS_a024_emergencyShutdown "SCS ECU: a024 emergency shutdown";
CM_ SG_ 869 SCS_a025_internalIsolationFault "SCS ECU: a025 internal isolation fault";
CM_ SG_ 869 SCS_a026_internalIsolationLow "SCS ECU: a026 internal isolation low";
CM_ SG_ 869 SCS_a027_externalIsolationLow "SCS ECU: a027 external isolation low";
CM_ SG_ 869 SCS_a028_isolationRationality "SCS ECU: a028 isolation rationality";
CM_ SG_ 869 SCS_a029_VbatOV "SCS ECU: a029 vbat OV";
CM_ SG_ 869 SCS_a030_VbusOV "SCS ECU: a030 vbus OV";
CM_ SG_ 869 SCS_a031_IbatOC "SCS ECU: a031 ibat OC";
CM_ SG_ 869 SCS_a032_VBatRationality "SCS ECU: a032 v bat rationality";
CM_ SG_ 869 SCS_a033_VBusRationality "SCS ECU: a033 v bus rationality";
CM_ SG_ 869 SCS_a034_IBatRationality "SCS ECU: a034 i bat rationality";
CM_ SG_ 869 SCS_a035_unexpectedVbusBehavior "SCS ECU: a035 unexpected vbus behavior";
CM_ SG_ 869 SCS_a036_internalContactorWelded "SCS ECU: a036 internal contactor welded";
CM_ SG_ 869 SCS_a037_outputContactorWelded "SCS ECU: a037 output contactor welded";
CM_ SG_ 869 SCS_a038_contactorFailedOpen "SCS ECU: a038 contactor failed open";
CM_ SG_ 869 SCS_a039_ibatRegulation "SCS ECU: a039 ibat regulation";
CM_ SG_ 869 SCS_a040_plus12VOutOfRange "SCS ECU: a040 plus12 v out of range";
CM_ SG_ 869 SCS_a041_minus12VOutOfRange "SCS ECU: a041 minus12 v out of range";
CM_ SG_ 869 SCS_a042_pilotOutOfRange "SCS ECU: a042 pilot out of range";
CM_ SG_ 869 SCS_a043_pilotRationality "SCS ECU: a043 pilot rationality";
CM_ SG_ 869 SCS_a044_proximityRationality "SCS ECU: a044 proximity rationality";
CM_ SG_ 869 SCS_a045_pcbaOT "SCS ECU: a045 pcba OT";
CM_ SG_ 869 SCS_a046_coolantOT "SCS ECU: a046 coolant OT";
CM_ SG_ 869 SCS_a047_cordOT "SCS ECU: a047 cord OT";
CM_ SG_ 869 SCS_a048_ambientOT "SCS ECU: a048 ambient OT";
CM_ SG_ 869 SCS_a049_pcbaTempRationality "SCS ECU: a049 pcba temp rationality";
CM_ SG_ 869 SCS_a050_coolantTempRationality "SCS ECU: a050 coolant temp rationality";
CM_ SG_ 869 SCS_a051_cordTempRationality "SCS ECU: a051 cord temp rationality";
CM_ SG_ 869 SCS_a052_ambientTempRationality "SCS ECU: a052 ambient temp rationality";
CM_ SG_ 869 SCS_a053_unexpectedThermalBehavi "SCS ECU: a053 unexpected thermal behavi";
CM_ SG_ 869 SCS_a054_pumpRegulation "SCS ECU: a054 pump regulation";
CM_ SG_ 869 SCS_a055_coolantLevelLow "SCS ECU: a055 coolant level low";
CM_ SG_ 869 SCS_a056_stateTransitionDenied "SCS ECU: a056 state transition denied";
CM_ SG_ 869 SCS_a057_watchdogReset "SCS ECU: a057 watchdog reset";
CM_ SG_ 869 SCS_a058_adcRef "SCS ECU: a058 adc ref";
CM_ SG_ 869 SCS_a059_memoryError "SCS ECU: a059 memory error";
CM_ SG_ 869 SCS_a060_swHVIL "SCS ECU: a060 sw HVIL";
CM_ SG_ 869 SCS_a061_postOutOfService "SCS ECU: a061 post out of service";
CM_ SG_ 869 SCS_a062_unused "SCS ECU: a062 unused";
CM_ SG_ 869 SCS_a063_canRationality "SCS ECU: a063 can rationality";
CM_ SG_ 869 SCS_a064_vehicleCommandTimeout "SCS ECU: a064 vehicle command timeout";
CM_ BO_ 880 "SCS ECU message: alert matrix2";
CM_ SG_ 880 SCS_a065_vBatRationalityStage1 "SCS ECU: a065 v bat rationality stage1";
CM_ SG_ 880 SCS_a066_vBatRationalityStage2 "SCS ECU: a066 v bat rationality stage2";
CM_ SG_ 880 SCS_a067_vBatRationalityStage3 "SCS ECU: a067 v bat rationality stage3";
CM_ SG_ 880 SCS_a068_vBatRationalityStage4 "SCS ECU: a068 v bat rationality stage4";
CM_ SG_ 880 SCS_a069_vStageRationalityV1 "SCS ECU: a069 v stage rationality V1";
CM_ SG_ 880 SCS_a070_vStageRationalityV2 "SCS ECU: a070 v stage rationality V2";
CM_ SG_ 880 SCS_a071_chargerMIA "SCS ECU: a071 charger MIA";
CM_ SG_ 880 SCS_a072_gtwMIA "SCS ECU: a072 gtw MIA";
CM_ SG_ 880 SCS_a073_lccMIA "SCS ECU: a073 lcc MIA";
CM_ SG_ 880 SCS_a074_isoVDiffHi "SCS ECU: a074 iso v diff hi";
CM_ SG_ 880 SCS_a075_unused75 "SCS ECU: a075 unused75";
CM_ SG_ 880 SCS_a076_bmsMIA "SCS ECU: a076 bms MIA";
CM_ SG_ 880 SCS_a077_unexpectedVbatBehavior "SCS ECU: a077 unexpected vbat behavior";
CM_ SG_ 880 SCS_a078_voltageMatchTimeout "SCS ECU: a078 voltage match timeout";
CM_ SG_ 880 SCS_a079_unexpectedVbat "SCS ECU: a079 unexpected vbat";
CM_ SG_ 880 SCS_a080_lccFaulted "SCS ECU: a080 lcc faulted";
CM_ SG_ 880 SCS_a081_rmsInputVoltageHigh "SCS ECU: a081 rms input voltage high";
CM_ SG_ 880 SCS_a082_VbatUV "SCS ECU: a082 vbat UV";
CM_ SG_ 880 SCS_a083_chargeCurrentLimited "SCS ECU: a083 charge current limited";
CM_ SG_ 880 SCS_a084_unused84 "SCS ECU: a084 unused84";
CM_ SG_ 880 SCS_a085_unused85 "SCS ECU: a085 unused85";
CM_ SG_ 880 SCS_a086_lccResetDetected "SCS ECU: a086 lcc reset detected";
CM_ SG_ 880 SCS_a087_posCordTempRationality "SCS ECU: a087 pos cord temp rationality";
CM_ SG_ 880 SCS_a088_negCordTempRationality "SCS ECU: a088 neg cord temp rationality";
CM_ SG_ 880 SCS_a089_posCordOT "SCS ECU: a089 pos cord OT";
CM_ SG_ 880 SCS_a090_negCordOT "SCS ECU: a090 neg cord OT";
CM_ SG_ 880 SCS_a091_voltageRiseDetection "SCS ECU: a091 voltage rise detection";
CM_ SG_ 880 SCS_a092_cabEnableDeasserted "SCS ECU: a092 cab enable deasserted";
CM_ SG_ 880 SCS_a093_unused93 "SCS ECU: a093 unused93";
CM_ SG_ 880 SCS_a094_unused94 "SCS ECU: a094 unused94";
CM_ SG_ 880 SCS_a095_unused95 "SCS ECU: a095 unused95";
CM_ SG_ 880 SCS_a096_unused96 "SCS ECU: a096 unused96";
CM_ SG_ 880 SCS_a097_unused97 "SCS ECU: a097 unused97";
CM_ SG_ 880 SCS_a098_unused98 "SCS ECU: a098 unused98";
CM_ SG_ 880 SCS_a099_unused99 "SCS ECU: a099 unused99";
CM_ SG_ 880 SCS_a100_unused100 "SCS ECU: a100 unused100";
CM_ SG_ 880 SCS_a101_unused101 "SCS ECU: a101 unused101";
CM_ SG_ 880 SCS_a102_unused102 "SCS ECU: a102 unused102";
CM_ SG_ 880 SCS_a103_unused103 "SCS ECU: a103 unused103";
CM_ SG_ 880 SCS_a104_unused104 "SCS ECU: a104 unused104";
CM_ SG_ 880 SCS_a105_unused105 "SCS ECU: a105 unused105";
CM_ SG_ 880 SCS_a106_unused106 "SCS ECU: a106 unused106";
CM_ SG_ 880 SCS_a107_unused107 "SCS ECU: a107 unused107";
CM_ SG_ 880 SCS_a108_unused108 "SCS ECU: a108 unused108";
CM_ SG_ 880 SCS_a109_unused109 "SCS ECU: a109 unused109";
CM_ SG_ 880 SCS_a110_unused110 "SCS ECU: a110 unused110";
CM_ SG_ 880 SCS_a111_unused111 "SCS ECU: a111 unused111";
CM_ SG_ 880 SCS_a112_unused112 "SCS ECU: a112 unused112";
CM_ SG_ 880 SCS_a113_unused113 "SCS ECU: a113 unused113";
CM_ SG_ 880 SCS_a114_unused114 "SCS ECU: a114 unused114";
CM_ SG_ 880 SCS_a115_unused115 "SCS ECU: a115 unused115";
CM_ SG_ 880 SCS_a116_unused116 "SCS ECU: a116 unused116";
CM_ SG_ 880 SCS_a117_unused117 "SCS ECU: a117 unused117";
CM_ SG_ 880 SCS_a118_unused118 "SCS ECU: a118 unused118";
CM_ SG_ 880 SCS_a119_unused119 "SCS ECU: a119 unused119";
CM_ SG_ 880 SCS_a120_unused120 "SCS ECU: a120 unused120";
CM_ SG_ 880 SCS_a121_unused121 "SCS ECU: a121 unused121";
CM_ SG_ 880 SCS_a122_unused122 "SCS ECU: a122 unused122";
CM_ SG_ 880 SCS_a123_unused123 "SCS ECU: a123 unused123";
CM_ SG_ 880 SCS_a124_unused124 "SCS ECU: a124 unused124";
CM_ SG_ 880 SCS_a125_unused125 "SCS ECU: a125 unused125";
CM_ SG_ 880 SCS_a126_unused126 "SCS ECU: a126 unused126";
CM_ SG_ 880 SCS_a127_unused127 "SCS ECU: a127 unused127";
CM_ SG_ 880 SCS_a128_unused128 "SCS ECU: a128 unused128";
CM_ BO_ 1531 "SDCR ECU message: alert log";
CM_ SG_ 1531 SDCR_alertID "SDCR ECU: alert ID";
CM_ SG_ 1531 SDCR_alertState "SDCR ECU: alert state";
CM_ SG_ 1531 SDCR_a001_pyroSenseV "SDCR ECU: a001 pyro sense v";
CM_ SG_ 1531 SDCR_a001_HVBackupSupplyV "SDCR ECU: a001 HV backup supply v";
CM_ SG_ 1531 SDCR_a001_boostRailV "SDCR ECU: a001 boost rail v";
CM_ SG_ 1531 SDCR_a001_expectedPyroV_max "SDCR ECU: a001 expected pyro v max";
CM_ SG_ 1531 SDCR_a001_expectedPyroV_min "SDCR ECU: a001 expected pyro v min";
CM_ SG_ 1531 SDCR_a001_fromState "SDCR ECU: a001 from state";
CM_ SG_ 1531 SDCR_a004_HVBackupSupplyV "SDCR ECU: a004 HV backup supply v";
CM_ SG_ 1531 SDCR_a004_boostRailV "SDCR ECU: a004 boost rail v";
CM_ SG_ 1531 SDCR_a004_diPresent "SDCR ECU: a004 di present";
CM_ SG_ 1531 SDCR_a004_pmRunningPin "SDCR ECU: a004 pm running pin";
CM_ SG_ 1531 SDCR_a006_pyroArmed "SDCR ECU: a006 pyro armed";
CM_ SG_ 1531 SDCR_a006_triggerReason_faultCur "SDCR ECU: a006 trigger reason fault currents";
CM_ SG_ 1531 SDCR_a006_triggerReason_hvBadAtS "SDCR ECU: a006 trigger reason hv bad at speed";
CM_ SG_ 1531 SDCR_a006_triggerReason_highBack "SDCR ECU: a006 trigger reason high back EMF";
CM_ SG_ 1531 SDCR_a006_faultCurrentsDetected "SDCR ECU: a006 fault currents detected";
CM_ SG_ 1531 SDCR_a006_diUartMIA "SDCR ECU: a006 di uart MIA";
CM_ SG_ 1531 SDCR_a006_pmRunningPin "SDCR ECU: a006 pm running pin";
CM_ SG_ 1531 SDCR_a006_hvPowerGood "SDCR ECU: a006 hv power good";
CM_ SG_ 1531 SDCR_a006_hvbkupPGoodPin "SDCR ECU: a006 hvbkup p good pin";
CM_ SG_ 1531 SDCR_a006_hvPowerNotGoodQualifie "SDCR ECU: a006 hv power not good qualified";
CM_ SG_ 1531 SDCR_a006_speedValid "SDCR ECU: a006 speed valid";
CM_ SG_ 1531 SDCR_a006_speedFromVoltage "SDCR ECU: a006 speed from voltage";
CM_ SG_ 1531 SDCR_a006_HVBackupSupplyV "SDCR ECU: a006 HV backup supply v";
CM_ SG_ 1531 SDCR_a006_boostRailV "SDCR ECU: a006 boost rail v";
CM_ SG_ 1531 SDCR_a006_maxAbsSpeed "SDCR ECU: a006 max abs speed";
CM_ SG_ 1531 SDCR_a006_vBat "SDCR ECU: a006 v bat";
CM_ SG_ 1531 SDCR_a007_faultReason_faultCurre "SDCR ECU: a007 fault reason fault currents at speed";
CM_ SG_ 1531 SDCR_a007_faultReason_unmitigate "SDCR ECU: a007 fault reason unmitigated UCR";
CM_ SG_ 1531 SDCR_a007_faultReason_propagatin "SDCR ECU: a007 fault reason propagating3 PS";
CM_ SG_ 1531 SDCR_a007_speedWasValid "SDCR ECU: a007 speed was valid";
CM_ SG_ 1531 SDCR_a007_imbalanceSeen "SDCR ECU: a007 imbalance seen";
CM_ SG_ 1531 SDCR_a007_ucrSeen "SDCR ECU: a007 ucr seen";
CM_ SG_ 1531 SDCR_a007_phaseVoltagePresent "SDCR ECU: a007 phase voltage present";
CM_ SG_ 1531 SDCR_a007_speedFromVoltage "SDCR ECU: a007 speed from voltage";
CM_ SG_ 1531 SDCR_a007_transientHandling "SDCR ECU: a007 transient handling";
CM_ SG_ 1531 SDCR_a007_maxAbsElcSpeed "SDCR ECU: a007 max abs elc speed";
CM_ SG_ 1531 SDCR_a007_avgIa "SDCR ECU: a007 avg ia";
CM_ SG_ 1531 SDCR_a007_avgIb "SDCR ECU: a007 avg ib";
CM_ SG_ 1531 SDCR_a007_maxAbsCurrents "SDCR ECU: a007 max abs currents";
CM_ SG_ 1531 SDCR_a008_dcLinkInfo "SDCR ECU: a008 dc link info";
CM_ SG_ 1531 SDCR_a009_diVersion "SDCR ECU: a009 di version";
CM_ SG_ 1531 SDCR_a009_sdcVersion "SDCR ECU: a009 sdc version";
CM_ SG_ 1531 SDCR_a010_pgood "SDCR ECU: a010 pgood";
CM_ SG_ 1531 SDCR_a010_boostRailV "SDCR ECU: a010 boost rail v";
CM_ SG_ 1531 SDCR_a010_Vref "SDCR ECU: a010 vref";
CM_ SG_ 1531 SDCR_a011_IaAvg "SDCR ECU: a011 ia avg";
CM_ SG_ 1531 SDCR_a011_IbAvg "SDCR ECU: a011 ib avg";
CM_ SG_ 1531 SDCR_a012_boostRailV "SDCR ECU: a012 boost rail v";
CM_ SG_ 1531 SDCR_a012_HVBackupSupplyV "SDCR ECU: a012 HV backup supply v";
CM_ SG_ 1531 SDCR_a012_vBat "SDCR ECU: a012 v bat";
CM_ SG_ 1531 SDCR_a012_vbkupGoodFdbk "SDCR ECU: a012 vbkup good fdbk";
CM_ SG_ 1531 SDCR_a013_boostRailV "SDCR ECU: a013 boost rail v";
CM_ SG_ 1531 SDCR_a013_HVBackupSupplyV "SDCR ECU: a013 HV backup supply v";
CM_ SG_ 1531 SDCR_a013_vBat "SDCR ECU: a013 v bat";
CM_ SG_ 1531 SDCR_a013_vbkupGoodFdbk "SDCR ECU: a013 vbkup good fdbk";
CM_ SG_ 1531 SDCR_a014_reason_vBusShortedLow "SDCR ECU: a014 reason v bus shorted low";
CM_ SG_ 1531 SDCR_a014_reason_vBusShortedHigh "SDCR ECU: a014 reason v bus shorted high";
CM_ SG_ 1531 SDCR_a014_boostRailV "SDCR ECU: a014 boost rail v";
CM_ SG_ 1531 SDCR_a014_HVBackupSupplyV "SDCR ECU: a014 HV backup supply v";
CM_ SG_ 1531 SDCR_a014_vBat "SDCR ECU: a014 v bat";
CM_ SG_ 1531 SDCR_a014_vbkupGoodFdbk "SDCR ECU: a014 vbkup good fdbk";
CM_ SG_ 1531 SDCR_a015_reason_vPhaseShortedLo "SDCR ECU: a015 reason v phase shorted low";
CM_ SG_ 1531 SDCR_a015_reason_vPhaseShortedHi "SDCR ECU: a015 reason v phase shorted high";
CM_ SG_ 1531 SDCR_a015_diSwitchingPin "SDCR ECU: a015 di switching pin";
CM_ SG_ 1531 SDCR_a015_vBat "SDCR ECU: a015 v bat";
CM_ SG_ 1531 SDCR_a015_va "SDCR ECU: a015 va";
CM_ SG_ 1531 SDCR_a015_vb "SDCR ECU: a015 vb";
CM_ SG_ 1531 SDCR_a015_vc "SDCR ECU: a015 vc";
CM_ SG_ 1531 SDCR_a017_expectedConfigWord "SDCR ECU: a017 expected config word";
CM_ SG_ 1531 SDCR_a017_receivedConfigWord "SDCR ECU: a017 received config word";
CM_ SG_ 1531 SDCR_a017_configMismatch "SDCR ECU: a017 config mismatch";
CM_ SG_ 1531 SDCR_a017_convStartTimeout "SDCR ECU: a017 conv start timeout";
CM_ SG_ 1531 SDCR_a017_convCompleteTimeout "SDCR ECU: a017 conv complete timeout";
CM_ SG_ 1531 SDCR_a017_dmaSpiTxTransferError "SDCR ECU: a017 dma spi tx transfer error";
CM_ SG_ 1531 SDCR_a017_dmaSpiRxTransferError "SDCR ECU: a017 dma spi rx transfer error";
CM_ SG_ 1531 SDCR_a017_dmaSpiTimerEnabled "SDCR ECU: a017 dma spi timer enabled";
CM_ SG_ 1531 SDCR_a018_pyroArmed "SDCR ECU: a018 pyro armed";
CM_ SG_ 1531 SDCR_a018_triggerReason_faultCur "SDCR ECU: a018 trigger reason fault currents";
CM_ SG_ 1531 SDCR_a018_triggerReason_hvBadAtS "SDCR ECU: a018 trigger reason hv bad at speed";
CM_ SG_ 1531 SDCR_a018_triggerReason_highBack "SDCR ECU: a018 trigger reason high back EMF";
CM_ SG_ 1531 SDCR_a018_faultCurrentsDetected "SDCR ECU: a018 fault currents detected";
CM_ SG_ 1531 SDCR_a018_diUartMIA "SDCR ECU: a018 di uart MIA";
CM_ SG_ 1531 SDCR_a018_pmRunningPin "SDCR ECU: a018 pm running pin";
CM_ SG_ 1531 SDCR_a018_hvPowerGood "SDCR ECU: a018 hv power good";
CM_ SG_ 1531 SDCR_a018_hvbkupPGoodPin "SDCR ECU: a018 hvbkup p good pin";
CM_ SG_ 1531 SDCR_a018_hvPowerNotGoodQualifie "SDCR ECU: a018 hv power not good qualified";
CM_ SG_ 1531 SDCR_a018_speedValid "SDCR ECU: a018 speed valid";
CM_ SG_ 1531 SDCR_a018_speedFromVoltage "SDCR ECU: a018 speed from voltage";
CM_ SG_ 1531 SDCR_a018_HVBackupSupplyV "SDCR ECU: a018 HV backup supply v";
CM_ SG_ 1531 SDCR_a018_boostRailV "SDCR ECU: a018 boost rail v";
CM_ SG_ 1531 SDCR_a018_maxAbsSpeed "SDCR ECU: a018 max abs speed";
CM_ SG_ 1531 SDCR_a018_vBat "SDCR ECU: a018 v bat";
CM_ SG_ 1531 SDCR_a019_faultReason_faultCurre "SDCR ECU: a019 fault reason fault currents at speed";
CM_ SG_ 1531 SDCR_a019_faultReason_unmitigate "SDCR ECU: a019 fault reason unmitigated UCR";
CM_ SG_ 1531 SDCR_a019_faultReason_propagatin "SDCR ECU: a019 fault reason propagating3 PS";
CM_ SG_ 1531 SDCR_a019_speedWasValid "SDCR ECU: a019 speed was valid";
CM_ SG_ 1531 SDCR_a019_imbalanceSeen "SDCR ECU: a019 imbalance seen";
CM_ SG_ 1531 SDCR_a019_ucrSeen "SDCR ECU: a019 ucr seen";
CM_ SG_ 1531 SDCR_a019_phaseVoltagePresent "SDCR ECU: a019 phase voltage present";
CM_ SG_ 1531 SDCR_a019_speedFromVoltage "SDCR ECU: a019 speed from voltage";
CM_ SG_ 1531 SDCR_a019_transientHandling "SDCR ECU: a019 transient handling";
CM_ SG_ 1531 SDCR_a019_maxAbsElcSpeed "SDCR ECU: a019 max abs elc speed";
CM_ SG_ 1531 SDCR_a019_avgIa "SDCR ECU: a019 avg ia";
CM_ SG_ 1531 SDCR_a019_avgIb "SDCR ECU: a019 avg ib";
CM_ SG_ 1531 SDCR_a019_maxAbsCurrents "SDCR ECU: a019 max abs currents";
CM_ SG_ 1531 SDCR_a020_errorCode "SDCR ECU: a020 error code";
CM_ SG_ 1531 SDCR_a020_rxData0 "SDCR ECU: a020 rx data0";
CM_ SG_ 1531 SDCR_a020_rxData1 "SDCR ECU: a020 rx data1";
CM_ SG_ 1531 SDCR_a020_rxData2 "SDCR ECU: a020 rx data2";
CM_ SG_ 1531 SDCR_a020_rxData3 "SDCR ECU: a020 rx data3";
CM_ SG_ 1531 SDCR_a020_rxData4 "SDCR ECU: a020 rx data4";
CM_ SG_ 1531 SDCR_a021_busBarTempC "SDCR ECU: a021 bus bar temp c";
CM_ SG_ 1531 SDCR_a021_busBarTempA "SDCR ECU: a021 bus bar temp a";
CM_ SG_ 1531 SDCR_a021_tempCVoltage "SDCR ECU: a021 temp c voltage";
CM_ SG_ 1531 SDCR_a021_tempAVoltage "SDCR ECU: a021 temp a voltage";
CM_ SG_ 1531 SDCR_a024_time "SDCR ECU: a024 time";
CM_ SG_ 1531 SDCR_a025_diSwitchingFromUart "SDCR ECU: a025 di switching from uart";
CM_ SG_ 1531 SDCR_a025_diSwitchingPin "SDCR ECU: a025 di switching pin";
CM_ SG_ 1531 SDCR_a025_pmRunningPin "SDCR ECU: a025 pm running pin";
CM_ SG_ 1531 SDCR_a025_diUartMIA "SDCR ECU: a025 di uart MIA";
CM_ SG_ 1531 SDCR_a025_HVBackupSupplyV "SDCR ECU: a025 HV backup supply v";
CM_ SG_ 1531 SDCR_a025_boostRailV "SDCR ECU: a025 boost rail v";
CM_ SG_ 1531 SDCR_a028_LVPowerState "SDCR ECU: a028 LV power state";
CM_ SG_ 1531 SDCR_a029_uartCommsMissing "SDCR ECU: a029 uart comms missing";
CM_ SG_ 1531 SDCR_a029_canCommsMissing "SDCR ECU: a029 can comms missing";
CM_ SG_ 1531 SDCR_a029_lvState "SDCR ECU: a029 lv state";
CM_ SG_ 1531 SDCR_a034_Ia "SDCR ECU: a034 ia";
CM_ SG_ 1531 SDCR_a034_Ib "SDCR ECU: a034 ib";
CM_ BO_ 1467 "SDCR ECU message: alert matrix";
CM_ SG_ 1467 SDCR_matrixIndex "SDCR ECU: matrix index";
CM_ SG_ 1467 SDCR_a001_powerOnSelfTestFailed "SDCR ECU: a001 power on self test failed";
CM_ SG_ 1467 SDCR_a002_diPstSkipped "SDCR ECU: a002 di pst skipped";
CM_ SG_ 1467 SDCR_a003_diUartMIA "SDCR ECU: a003 di uart MIA";
CM_ SG_ 1467 SDCR_a004_pmRunningFdbkIrrationa "SDCR ECU: a004 pm running fdbk irrational";
CM_ SG_ 1467 SDCR_a005_motorSpeedIrrational "SDCR ECU: a005 motor speed irrational";
CM_ SG_ 1467 SDCR_a006_pyroTriggered "SDCR ECU: a006 pyro triggered";
CM_ SG_ 1467 SDCR_a007_faultCurrentsDetected "SDCR ECU: a007 fault currents detected";
CM_ SG_ 1467 SDCR_a008_hvlinkMIA "SDCR ECU: a008 hvlink MIA";
CM_ SG_ 1467 SDCR_a009_uartVersionMismatch "SDCR ECU: a009 uart version mismatch";
CM_ SG_ 1467 SDCR_a010_vrefIrrational "SDCR ECU: a010 vref irrational";
CM_ SG_ 1467 SDCR_a011_phaseCurrentOffset "SDCR ECU: a011 phase current offset";
CM_ SG_ 1467 SDCR_a012_vBoostSecIrrational "SDCR ECU: a012 v boost sec irrational";
CM_ SG_ 1467 SDCR_a013_vBkupIrrational "SDCR ECU: a013 v bkup irrational";
CM_ SG_ 1467 SDCR_a014_vBusIrrational "SDCR ECU: a014 v bus irrational";
CM_ SG_ 1467 SDCR_a015_phaseVIrrational "SDCR ECU: a015 phase v irrational";
CM_ SG_ 1467 SDCR_a016_systemReset "SDCR ECU: a016 system reset";
CM_ SG_ 1467 SDCR_a017_adcSPIError "SDCR ECU: a017 adc SPI error";
CM_ SG_ 1467 SDCR_a018_historicalPyroTrigger "SDCR ECU: a018 historical pyro trigger";
CM_ SG_ 1467 SDCR_a019_historicalFaultCurrent "SDCR ECU: a019 historical fault currents";
CM_ SG_ 1467 SDCR_a020_eepromSPIError "SDCR ECU: a020 eeprom SPI error";
CM_ SG_ 1467 SDCR_a021_busBarTempIrrational "SDCR ECU: a021 bus bar temp irrational";
CM_ SG_ 1467 SDCR_a022_TaskInitError "SDCR ECU: a022 task init error";
CM_ SG_ 1467 SDCR_a023_ecuLogAvailable "SDCR ECU: a023 ecu log available";
CM_ SG_ 1467 SDCR_a024_gtwMIA "SDCR ECU: a024 gtw MIA";
CM_ SG_ 1467 SDCR_a025_diSwitchingFdbkIrratio "SDCR ECU: a025 di switching fdbk irrational";
CM_ SG_ 1467 SDCR_a026_faultCurrentMonitoring "SDCR ECU: a026 fault current monitoring disabled";
CM_ SG_ 1467 SDCR_a027_diCanMIA "SDCR ECU: a027 di can MIA";
CM_ SG_ 1467 SDCR_a028_vcLVStateMIA "SDCR ECU: a028 vc LV state MIA";
CM_ SG_ 1467 SDCR_a029_diMIA "SDCR ECU: a029 di MIA";
CM_ SG_ 1467 SDCR_a030_placeholder30 "SDCR ECU: a030 placeholder30";
CM_ SG_ 1467 SDCR_a031_placeholder31 "SDCR ECU: a031 placeholder31";
CM_ SG_ 1467 SDCR_a032_placeholder32 "SDCR ECU: a032 placeholder32";
CM_ SG_ 1467 SDCR_a033_placeholder33 "SDCR ECU: a033 placeholder33";
CM_ SG_ 1467 SDCR_a034_phaseCurrentIrrational "SDCR ECU: a034 phase current irrational";
CM_ BO_ 1597 "SDCR ECU message: info";
CM_ SG_ 1597 SDCR_infoIndex "SDCR ECU: info index";
CM_ SG_ 1597 SDCR_infoBuildType "SDCR ECU: info build type";
CM_ SG_ 1597 SDCR_infoBuildConfigId "SDCR ECU: info build config id";
CM_ SG_ 1597 SDCR_infoHardwareId "SDCR ECU: info hardware id";
CM_ SG_ 1597 SDCR_infoComponentId "SDCR ECU: info component id";
CM_ SG_ 1597 SDCR_infoPcbaId "SDCR ECU: info pcba id";
CM_ SG_ 1597 SDCR_infoAssemblyId "SDCR ECU: info assembly id";
CM_ SG_ 1597 SDCR_infoUsageId "SDCR ECU: info usage id";
CM_ SG_ 1597 SDCR_infoSubUsageId "SDCR ECU: info sub usage id";
CM_ SG_ 1597 SDCR_infoAppCrc "SDCR ECU: info app crc";
CM_ SG_ 1597 SDCR_infoBootGitHash "SDCR ECU: info boot git hash";
CM_ BO_ 1835 "Air suspension controller message: alert log";
CM_ SG_ 1835 TAS_alertID "Air suspension controller: alert ID";
CM_ SG_ 1835 TAS_alertState "Air suspension controller: alert state";
CM_ SG_ 1835 TAS_a001_InternalWatchdog "Air suspension controller: a001 internal watchdog";
CM_ SG_ 1835 TAS_a002_CPUUndervoltage "Air suspension controller: a002 CPU undervoltage";
CM_ SG_ 1835 TAS_a002_PowerOnReset "Air suspension controller: a002 power on reset";
CM_ SG_ 1835 TAS_a003_AssertID "Air suspension controller: a003 assert ID";
CM_ SG_ 1835 TAS_a003_LineNumber "Air suspension controller: a003 line number";
CM_ SG_ 1835 TAS_a003_Data "Air suspension controller: a003 data";
CM_ SG_ 1835 TAS_a012_ClockError "Air suspension controller: a012 clock error";
CM_ SG_ 1835 TAS_a012_FlashError "Air suspension controller: a012 flash error";
CM_ SG_ 1835 TAS_a012_SoftwareReset "Air suspension controller: a012 software reset";
CM_ SG_ 1835 TAS_a012_CheckstopReset "Air suspension controller: a012 checkstop reset";
CM_ SG_ 1835 TAS_a012_DebugReset "Air suspension controller: a012 debug reset";
CM_ SG_ 1835 TAS_a012_ExternalReset "Air suspension controller: a012 external reset";
CM_ SG_ 1835 TAS_a021_Task1msLate "Air suspension controller: a021 task1ms late";
CM_ SG_ 1835 TAS_a021_Task1msStarved "Air suspension controller: a021 task1ms starved";
CM_ SG_ 1835 TAS_a021_Task1msMissed "Air suspension controller: a021 task1ms missed";
CM_ SG_ 1835 TAS_a021_Task10msLate "Air suspension controller: a021 task10ms late";
CM_ SG_ 1835 TAS_a021_Task10msStarved "Air suspension controller: a021 task10ms starved";
CM_ SG_ 1835 TAS_a021_Task10msMissed "Air suspension controller: a021 task10ms missed";
CM_ SG_ 1835 TAS_a021_Task100msLate "Air suspension controller: a021 task100ms late";
CM_ SG_ 1835 TAS_a021_Task100msStarved "Air suspension controller: a021 task100ms starved";
CM_ SG_ 1835 TAS_a021_Task100msMissed "Air suspension controller: a021 task100ms missed";
CM_ SG_ 1835 TAS_a021_Task1000msLate "Air suspension controller: a021 task1000ms late";
CM_ SG_ 1835 TAS_a021_Task1000msStarved "Air suspension controller: a021 task1000ms starved";
CM_ SG_ 1835 TAS_a021_Task1000msMissed "Air suspension controller: a021 task1000ms missed";
CM_ SG_ 1835 TAS_a022_TaskInitErrorCount "Air suspension controller: a022 task init error count";
CM_ SG_ 1835 TAS_a022_TaskInitError0 "Air suspension controller: a022 task init error0";
CM_ SG_ 1835 TAS_a022_TaskInitError1 "Air suspension controller: a022 task init error1";
CM_ SG_ 1835 TAS_a022_TaskInitError2 "Air suspension controller: a022 task init error2";
CM_ SG_ 1835 TAS_a022_TaskInitError3 "Air suspension controller: a022 task init error3";
CM_ SG_ 1835 TAS_a022_TaskInitError4 "Air suspension controller: a022 task init error4";
CM_ SG_ 1835 TAS_a025_vehicleLockAtCrash "Air suspension controller: a025 vehicle lock at crash";
CM_ SG_ 1835 TAS_a025_CANCrashIsActive "Air suspension controller: a025 CAN crash is active";
CM_ SG_ 1835 TAS_a025_appCrashIsActive "Air suspension controller: a025 app crash is active";
CM_ SG_ 1835 TAS_a025_lastCrashEvent "Air suspension controller: a025 last crash event";
CM_ SG_ 1835 TAS_a030_PWMdutyCycleFL "Air suspension controller: a030 PW mduty cycle FL";
CM_ SG_ 1835 TAS_a030_PWMfrequencyFL "Air suspension controller: a030 PW mfrequency FL";
CM_ SG_ 1835 TAS_a030_PWMfaultFL "Air suspension controller: a030 PW mfault FL";
CM_ SG_ 1835 TAS_a031_PWMdutyCycleFR "Air suspension controller: a031 PW mduty cycle FR";
CM_ SG_ 1835 TAS_a031_PWMfrequencyFR "Air suspension controller: a031 PW mfrequency FR";
CM_ SG_ 1835 TAS_a031_PWMfaultFR "Air suspension controller: a031 PW mfault FR";
CM_ SG_ 1835 TAS_a032_PWMdutyCycleRL "Air suspension controller: a032 PW mduty cycle RL";
CM_ SG_ 1835 TAS_a032_PWMfrequencyRL "Air suspension controller: a032 PW mfrequency RL";
CM_ SG_ 1835 TAS_a032_PWMfaultRL "Air suspension controller: a032 PW mfault RL";
CM_ SG_ 1835 TAS_a033_PWMdutyCycleRR "Air suspension controller: a033 PW mduty cycle RR";
CM_ SG_ 1835 TAS_a033_PWMfrequencyRR "Air suspension controller: a033 PW mfrequency RR";
CM_ SG_ 1835 TAS_a033_PWMfaultRR "Air suspension controller: a033 PW mfault RR";
CM_ SG_ 1835 TAS_a034_PWMdutyCycleFL "Air suspension controller: a034 PW mduty cycle FL";
CM_ SG_ 1835 TAS_a034_PWMfrequencyFL "Air suspension controller: a034 PW mfrequency FL";
CM_ SG_ 1835 TAS_a034_PWMfaultFL "Air suspension controller: a034 PW mfault FL";
CM_ SG_ 1835 TAS_a035_PWMdutyCycleFR "Air suspension controller: a035 PW mduty cycle FR";
CM_ SG_ 1835 TAS_a035_PWMfrequencyFR "Air suspension controller: a035 PW mfrequency FR";
CM_ SG_ 1835 TAS_a035_PWMfaultFR "Air suspension controller: a035 PW mfault FR";
CM_ SG_ 1835 TAS_a036_PWMdutyCycleRL "Air suspension controller: a036 PW mduty cycle RL";
CM_ SG_ 1835 TAS_a036_PWMfrequencyRL "Air suspension controller: a036 PW mfrequency RL";
CM_ SG_ 1835 TAS_a036_PWMfaultRL "Air suspension controller: a036 PW mfault RL";
CM_ SG_ 1835 TAS_a037_PWMdutyCycleRR "Air suspension controller: a037 PW mduty cycle RR";
CM_ SG_ 1835 TAS_a037_PWMfrequencyRR "Air suspension controller: a037 PW mfrequency RR";
CM_ SG_ 1835 TAS_a037_PWMfaultRR "Air suspension controller: a037 PW mfault RR";
CM_ SG_ 1835 TAS_a038_PWMdutyCycleFL "Air suspension controller: a038 PW mduty cycle FL";
CM_ SG_ 1835 TAS_a038_PWMfrequencyFL "Air suspension controller: a038 PW mfrequency FL";
CM_ SG_ 1835 TAS_a038_PWMfaultFL "Air suspension controller: a038 PW mfault FL";
CM_ SG_ 1835 TAS_a039_PWMdutyCycleFR "Air suspension controller: a039 PW mduty cycle FR";
CM_ SG_ 1835 TAS_a039_PWMfrequencyFR "Air suspension controller: a039 PW mfrequency FR";
CM_ SG_ 1835 TAS_a039_PWMfaultFR "Air suspension controller: a039 PW mfault FR";
CM_ SG_ 1835 TAS_a040_PWMdutyCycleRL "Air suspension controller: a040 PW mduty cycle RL";
CM_ SG_ 1835 TAS_a040_PWMfrequencyRL "Air suspension controller: a040 PW mfrequency RL";
CM_ SG_ 1835 TAS_a040_PWMfaultRL "Air suspension controller: a040 PW mfault RL";
CM_ SG_ 1835 TAS_a041_PWMdutyCycleRR "Air suspension controller: a041 PW mduty cycle RR";
CM_ SG_ 1835 TAS_a041_PWMfrequencyRR "Air suspension controller: a041 PW mfrequency RR";
CM_ SG_ 1835 TAS_a041_PWMfaultRR "Air suspension controller: a041 PW mfault RR";
CM_ SG_ 1835 TAS_a070_voltage12V "Air suspension controller: a070 voltage12 v";
CM_ SG_ 1835 TAS_a071_voltage12V "Air suspension controller: a071 voltage12 v";
CM_ SG_ 1835 TAS_a072_voltage5VOnBoard "Air suspension controller: a072 voltage5 v on board";
CM_ SG_ 1835 TAS_a073_voltage5VOnBoard "Air suspension controller: a073 voltage5 v on board";
CM_ SG_ 1835 TAS_a074_voltage5VOffBoard "Air suspension controller: a074 voltage5 v off board";
CM_ SG_ 1835 TAS_a075_voltage5VOffBoard "Air suspension controller: a075 voltage5 v off board";
CM_ SG_ 1835 TAS_a076_voltage5VOffBoard "Air suspension controller: a076 voltage5 v off board";
CM_ SG_ 1835 TAS_a077_sensorVoltage "Air suspension controller: a077 sensor voltage";
CM_ SG_ 1835 TAS_a077_sensorRefVoltage "Air suspension controller: a077 sensor ref voltage";
CM_ SG_ 1835 TAS_a078_sensorVoltage "Air suspension controller: a078 sensor voltage";
CM_ SG_ 1835 TAS_a078_sensorRefVoltage "Air suspension controller: a078 sensor ref voltage";
CM_ SG_ 1835 TAS_a080_voltage5VHeight "Air suspension controller: a080 voltage5 v height";
CM_ SG_ 1835 TAS_a081_voltage5VHeight "Air suspension controller: a081 voltage5 v height";
CM_ SG_ 1835 TAS_a082_voltage5VHeight "Air suspension controller: a082 voltage5 v height";
CM_ SG_ 1835 TAS_a083_voltage5VAnalog "Air suspension controller: a083 voltage5 v analog";
CM_ SG_ 1835 TAS_a084_voltage5VAnalog "Air suspension controller: a084 voltage5 v analog";
CM_ SG_ 1835 TAS_a085_voltage5VAnalog "Air suspension controller: a085 voltage5 v analog";
CM_ SG_ 1835 TAS_a086_voltage12VSwitched "Air suspension controller: a086 voltage12 v switched";
CM_ SG_ 1835 TAS_a087_voltage12VSwitched "Air suspension controller: a087 voltage12 v switched";
CM_ SG_ 1835 TAS_a093_readError "Air suspension controller: a093 read error";
CM_ SG_ 1835 TAS_a093_IVOR2Exception "Air suspension controller: a093 IVOR2 exception";
CM_ SG_ 1835 TAS_a098_VCFRONT_LVPowerState_MI "Air suspension controller: a098 VCFRONT LV power state MIA";
CM_ SG_ 1835 TAS_a098_VCFRONT_sensors_MIA "Air suspension controller: a098 VCFRONT sensors MIA";
CM_ SG_ 1835 TAS_a098_VCFRONT_status_MIA "Air suspension controller: a098 VCFRONT status MIA";
CM_ SG_ 1835 TAS_a098_VCFRONT_systemStatus_MI "Air suspension controller: a098 VCFRONT system status MIA";
CM_ SG_ 1835 TAS_a098_VCFRONT_vehNm_MIA "Air suspension controller: a098 VCFRONT veh nm MIA";
CM_ SG_ 1835 TAS_a099_UI_chassisControl_MIA "Air suspension controller: a099 UI chassis control MIA";
CM_ SG_ 1835 TAS_a099_UI_driverAssistMapData_ "Air suspension controller: a099 UI driver assist map data MIA";
CM_ SG_ 1835 TAS_a099_UI_suspensionControl_MI "Air suspension controller: a099 UI suspension control MIA";
CM_ SG_ 1835 TAS_a099_UI_vehicleModes_MIA "Air suspension controller: a099 UI vehicle modes MIA";
CM_ SG_ 1835 TAS_a100_RCM_inertial1_MIA "Air suspension controller: a100 RCM inertial1 MIA";
CM_ SG_ 1835 TAS_a100_RCM_inertial2_MIA "Air suspension controller: a100 RCM inertial2 MIA";
CM_ SG_ 1835 TAS_a101_ESP_brakeTorque_MIA "Air suspension controller: a101 ESP brake torque MIA";
CM_ SG_ 1835 TAS_a101_ESP_status_MIA "Air suspension controller: a101 ESP status MIA";
CM_ SG_ 1835 TAS_a101_ESP_wheelRotation_MIA "Air suspension controller: a101 ESP wheel rotation MIA";
CM_ SG_ 1835 TAS_a102_DI_chassisControl_MIA "Air suspension controller: a102 DI chassis control MIA";
CM_ SG_ 1835 TAS_a102_DI_locStatus_MIA "Air suspension controller: a102 DI loc status MIA";
CM_ SG_ 1835 TAS_a102_DI_speed_MIA "Air suspension controller: a102 DI speed MIA";
CM_ SG_ 1835 TAS_a102_DI_systemStatus_MIA "Air suspension controller: a102 DI system status MIA";
CM_ SG_ 1835 TAS_a102_DI_vehicleEstimates_MIA "Air suspension controller: a102 DI vehicle estimates MIA";
CM_ SG_ 1835 TAS_a102_DIF_torque_MIA "Air suspension controller: a102 DIF torque MIA";
CM_ SG_ 1835 TAS_a102_DIR_torque_MIA "Air suspension controller: a102 DIR torque MIA";
CM_ SG_ 1835 TAS_a103_GTW_carConfig_MIA "Air suspension controller: a103 GTW car config MIA";
CM_ SG_ 1835 TAS_a103_GTW_time_MIA "Air suspension controller: a103 GTW time MIA";
CM_ SG_ 1835 TAS_a103_GTW_vehNm_MIA "Air suspension controller: a103 GTW veh nm MIA";
CM_ SG_ 1835 TAS_a103_GTW_vin_MIA "Air suspension controller: a103 GTW vin MIA";
CM_ SG_ 1835 TAS_a164_detectedDamperSolenoid "Air suspension controller: a164 detected damper solenoid";
CM_ SG_ 1835 TAS_a164_expectedDamperSolenoid "Air suspension controller: a164 expected damper solenoid";
CM_ SG_ 1835 TAS_a165_damperValveFault "Air suspension controller: a165 damper valve fault";
CM_ SG_ 1835 TAS_a165_resistanceValue "Air suspension controller: a165 resistance value";
CM_ SG_ 1835 TAS_a166_damperValveFault "Air suspension controller: a166 damper valve fault";
CM_ SG_ 1835 TAS_a166_resistanceValue "Air suspension controller: a166 resistance value";
CM_ SG_ 1835 TAS_a167_damperValveFault "Air suspension controller: a167 damper valve fault";
CM_ SG_ 1835 TAS_a167_resistanceValue "Air suspension controller: a167 resistance value";
CM_ SG_ 1835 TAS_a168_damperValveFault "Air suspension controller: a168 damper valve fault";
CM_ SG_ 1835 TAS_a168_resistanceValue "Air suspension controller: a168 resistance value";
CM_ SG_ 1835 TAS_a169_damperValveFault "Air suspension controller: a169 damper valve fault";
CM_ SG_ 1835 TAS_a169_resistanceValue "Air suspension controller: a169 resistance value";
CM_ SG_ 1835 TAS_a170_damperValveFault "Air suspension controller: a170 damper valve fault";
CM_ SG_ 1835 TAS_a170_resistanceValue "Air suspension controller: a170 resistance value";
CM_ SG_ 1835 TAS_a171_damperValveFault "Air suspension controller: a171 damper valve fault";
CM_ SG_ 1835 TAS_a171_resistanceValue "Air suspension controller: a171 resistance value";
CM_ SG_ 1835 TAS_a172_damperValveFault "Air suspension controller: a172 damper valve fault";
CM_ SG_ 1835 TAS_a172_resistanceValue "Air suspension controller: a172 resistance value";
CM_ SG_ 1835 TAS_a173_heightDelta_mm "Air suspension controller: a173 height delta mm";
CM_ SG_ 1835 TAS_a174_heightDelta_mm "Air suspension controller: a174 height delta mm";
CM_ SG_ 1835 TAS_a175_heightDelta_mm "Air suspension controller: a175 height delta mm";
CM_ SG_ 1835 TAS_a176_heightDelta_mm "Air suspension controller: a176 height delta mm";
CM_ SG_ 1835 TAS_a190_a2bFaultType "Air suspension controller: a190 a2b fault type";
CM_ SG_ 1835 TAS_a190_a2bInterruptType "Air suspension controller: a190 a2b interrupt type";
CM_ SG_ 1835 TAS_a190_a2bFaultSource "Air suspension controller: a190 a2b fault source";
CM_ SG_ 1835 TAS_a191_a2bFaultType "Air suspension controller: a191 a2b fault type";
CM_ SG_ 1835 TAS_a191_a2bInterruptType "Air suspension controller: a191 a2b interrupt type";
CM_ SG_ 1835 TAS_a191_a2bFaultSource "Air suspension controller: a191 a2b fault source";
CM_ SG_ 1835 TAS_a192_rideHeightVelDspFL "Air suspension controller: a192 ride height vel dsp FL";
CM_ SG_ 1835 TAS_a192_rideHeightVelDspFR "Air suspension controller: a192 ride height vel dsp FR";
CM_ SG_ 1835 TAS_a192_rideHeightVelDspRL "Air suspension controller: a192 ride height vel dsp RL";
CM_ SG_ 1835 TAS_a192_rideHeightVelDspRR "Air suspension controller: a192 ride height vel dsp RR";
CM_ SG_ 1835 TAS_a192_rideHeightVelObserverFL "Air suspension controller: a192 ride height vel observer FL";
CM_ SG_ 1835 TAS_a192_rideHeightVelObserverFR "Air suspension controller: a192 ride height vel observer FR";
CM_ SG_ 1835 TAS_a192_rideHeightVelObserverRL "Air suspension controller: a192 ride height vel observer RL";
CM_ SG_ 1835 TAS_a192_rideHeightVelObserverRR "Air suspension controller: a192 ride height vel observer RR";
CM_ SG_ 1835 TAS_a192_alertVersion "Air suspension controller: a192 alert version";
CM_ SG_ 1835 TAS_a193_EPAS3P_sysStatus_MIA "Air suspension controller: a193 EPAS3 p sys status MIA";
CM_ SG_ 1835 TAS_a210_heightSensorDeltaFL "Air suspension controller: a210 height sensor delta FL";
CM_ SG_ 1835 TAS_a210_heightSensorDeltaFR "Air suspension controller: a210 height sensor delta FR";
CM_ SG_ 1835 TAS_a210_heightSensorDeltaRL "Air suspension controller: a210 height sensor delta RL";
CM_ SG_ 1835 TAS_a210_heightSensorDeltaRR "Air suspension controller: a210 height sensor delta RR";
CM_ SG_ 1835 TAS_a220_galleryPressure "Air suspension controller: a220 gallery pressure";
CM_ SG_ 1835 TAS_a220_timeInExhaust "Air suspension controller: a220 time in exhaust";
CM_ SG_ 1835 TAS_a221_galleryPressureDelta "Air suspension controller: a221 gallery pressure delta";
CM_ SG_ 1835 TAS_a221_timeInIdle "Air suspension controller: a221 time in idle";
CM_ SG_ 1835 TAS_a222_galleryPressureDelta "Air suspension controller: a222 gallery pressure delta";
CM_ SG_ 1835 TAS_a223_galleryPressure "Air suspension controller: a223 gallery pressure";
CM_ SG_ 1835 TAS_a223_valveOnFL "Air suspension controller: a223 valve on FL";
CM_ SG_ 1835 TAS_a223_valveOnFR "Air suspension controller: a223 valve on FR";
CM_ SG_ 1835 TAS_a223_valveOnRL "Air suspension controller: a223 valve on RL";
CM_ SG_ 1835 TAS_a223_valveOnRR "Air suspension controller: a223 valve on RR";
CM_ SG_ 1835 TAS_a223_valveOnReservoir "Air suspension controller: a223 valve on reservoir";
CM_ SG_ 1835 TAS_a224_galleryPressure "Air suspension controller: a224 gallery pressure";
CM_ SG_ 1835 TAS_a224_valveOnFL "Air suspension controller: a224 valve on FL";
CM_ SG_ 1835 TAS_a224_valveOnFR "Air suspension controller: a224 valve on FR";
CM_ SG_ 1835 TAS_a224_valveOnRL "Air suspension controller: a224 valve on RL";
CM_ SG_ 1835 TAS_a224_valveOnRR "Air suspension controller: a224 valve on RR";
CM_ SG_ 1835 TAS_a224_valveOnReservoir "Air suspension controller: a224 valve on reservoir";
CM_ SG_ 1835 TAS_a225_galleryPressure "Air suspension controller: a225 gallery pressure";
CM_ SG_ 1835 TAS_a226_PWMdutyCycleFL "Air suspension controller: a226 PW mduty cycle FL";
CM_ SG_ 1835 TAS_a226_PWMfrequencyFL "Air suspension controller: a226 PW mfrequency FL";
CM_ SG_ 1835 TAS_a226_PWMfaultFL "Air suspension controller: a226 PW mfault FL";
CM_ SG_ 1835 TAS_a227_PWMdutyCycleFR "Air suspension controller: a227 PW mduty cycle FR";
CM_ SG_ 1835 TAS_a227_PWMfrequencyFR "Air suspension controller: a227 PW mfrequency FR";
CM_ SG_ 1835 TAS_a227_PWMfaultFR "Air suspension controller: a227 PW mfault FR";
CM_ SG_ 1835 TAS_a228_PWMdutyCycleRL "Air suspension controller: a228 PW mduty cycle RL";
CM_ SG_ 1835 TAS_a228_PWMfrequencyRL "Air suspension controller: a228 PW mfrequency RL";
CM_ SG_ 1835 TAS_a228_PWMfaultRL "Air suspension controller: a228 PW mfault RL";
CM_ SG_ 1835 TAS_a229_PWMdutyCycleRR "Air suspension controller: a229 PW mduty cycle RR";
CM_ SG_ 1835 TAS_a229_PWMfrequencyRR "Air suspension controller: a229 PW mfrequency RR";
CM_ SG_ 1835 TAS_a229_PWMfaultRR "Air suspension controller: a229 PW mfault RR";
CM_ SG_ 1835 TAS_a232_detectedSuspensionType "Air suspension controller: a232 detected suspension type";
CM_ SG_ 1835 TAS_a232_expectedSuspensionType "Air suspension controller: a232 expected suspension type";
CM_ SG_ 1835 TAS_a234_detectedDamperHydraulic "Air suspension controller: a234 detected damper hydraulic";
CM_ SG_ 1835 TAS_a234_expectedDamperHydraulic "Air suspension controller: a234 expected damper hydraulic";
CM_ SG_ 1835 TAS_a240_highAdjustCountRatio "Air suspension controller: a240 high adjust count ratio";
CM_ SG_ 1835 TAS_a240_highAdjustTimeRatio "Air suspension controller: a240 high adjust time ratio";
CM_ SG_ 1835 TAS_a240_highCrossPressure "Air suspension controller: a240 high cross pressure";
CM_ SG_ 1835 TAS_a240_highCompExhTimeRatio "Air suspension controller: a240 high comp exh time ratio";
CM_ SG_ 1835 TAS_a240_adjustCountRatioSpring "Air suspension controller: a240 adjust count ratio spring";
CM_ SG_ 1835 TAS_a240_adjustCountRatio "Air suspension controller: a240 adjust count ratio";
CM_ SG_ 1835 TAS_a240_adjustTimeRatioSpring "Air suspension controller: a240 adjust time ratio spring";
CM_ SG_ 1835 TAS_a240_adjustTimeRatio "Air suspension controller: a240 adjust time ratio";
CM_ SG_ 1835 TAS_a240_compExhTimeRatio "Air suspension controller: a240 comp exh time ratio";
CM_ SG_ 1835 TAS_a240_crossPressure "Air suspension controller: a240 cross pressure";
CM_ SG_ 1835 TAS_a285_twistLevel "Air suspension controller: a285 twist level";
CM_ SG_ 1835 TAS_a290_twistLevel "Air suspension controller: a290 twist level";
CM_ SG_ 1835 TAS_a291_frontAxleHeight "Air suspension controller: a291 front axle height";
CM_ SG_ 1835 TAS_a292_rearAxleHeight "Air suspension controller: a292 rear axle height";
CM_ SG_ 1835 TAS_a293_frontAxleHeight "Air suspension controller: a293 front axle height";
CM_ SG_ 1835 TAS_a294_rearAxleHeight "Air suspension controller: a294 rear axle height";
CM_ SG_ 1835 TAS_a295_targetHeight "Air suspension controller: a295 target height";
CM_ SG_ 1835 TAS_a296_detectedChassisType "Air suspension controller: a296 detected chassis type";
CM_ SG_ 1835 TAS_a296_expectedChassisType "Air suspension controller: a296 expected chassis type";
CM_ SG_ 1835 TAS_a319_detectedDrivetrainType "Air suspension controller: a319 detected drivetrain type";
CM_ SG_ 1835 TAS_a319_expectedDrivetrainType "Air suspension controller: a319 expected drivetrain type";
BA_DEF_ BO_ "GenMsgCycleTime" INT 0 3600000;
BA_DEF_ BO_ "GenMsgSendType" ENUM "Cyclic","NotUsed","NotUsed","NotUsed","NotUsed","NotUsed","NotUsed","IfActive","NoMsgSendType","NotUsed";
BA_DEF_ BO_ "VFrameFormat" ENUM "StandardCAN","ExtendedCAN","reserved","J1939PG","reserved","reserved","reserved","reserved","reserved","reserved","reserved","reserved","reserved","reserved","StandardCAN_FD","ExtendedCAN_FD";
BA_DEF_ BO_ "CANFD_BRS" ENUM "0","1";
BA_DEF_ SG_ "SystemSignalLongSymbol" STRING;
BA_DEF_ SG_ "Confidence" ENUM "layout-only","plausible","validated";
BA_DEF_DEF_ "GenMsgCycleTime" 0;
BA_DEF_DEF_ "GenMsgSendType" "NoMsgSendType";
BA_DEF_DEF_ "VFrameFormat" "StandardCAN";
BA_DEF_DEF_ "CANFD_BRS" "1";
BA_DEF_DEF_ "SystemSignalLongSymbol" "";
BA_DEF_DEF_ "Confidence" "layout-only";
BA_ "Confidence" SG_ 17 RCM_collisionRear 1;
BA_ "Confidence" SG_ 17 RCM_collisionRight 1;
BA_ "Confidence" SG_ 17 RCM_collisionLeft 1;
BA_ "Confidence" SG_ 17 RCM_collisionFront 1;
BA_ "Confidence" SG_ 17 RCM_collisionRollover 1;
BA_ "Confidence" SG_ 17 RCM_collisionPedPro 1;
BA_ "Confidence" SG_ 17 RCM_collisionSeverity 1;
BA_ "Confidence" SG_ 257 RCM_yawRate 1;
BA_ "Confidence" SG_ 257 RCM_pitchRate 1;
BA_ "Confidence" SG_ 257 RCM_rollRate 1;
BA_ "Confidence" SG_ 257 RCM_rollRateQF 1;
BA_ "Confidence" SG_ 257 RCM_yawRateQF 1;
BA_ "Confidence" SG_ 257 RCM_pitchRateQF 1;
BA_ "Confidence" SG_ 278 RCM_longitudinalAccel 1;
BA_ "Confidence" SG_ 278 RCM_lateralAccel 1;
BA_ "Confidence" SG_ 278 RCM_verticalAccel 1;
BA_ "Confidence" SG_ 278 RCM_longitudinalAccelQF 1;
BA_ "Confidence" SG_ 278 RCM_lateralAccelQF 1;
BA_ "Confidence" SG_ 278 RCM_verticalAccelQF 1;
BA_ "Confidence" SG_ 278 RCM_CGTranslationFault 1;
BA_ "Confidence" SG_ 849 RCM_infoBuildType 1;
BA_ "Confidence" SG_ 849 RCM_infoPcbaID 1;
BA_ "Confidence" SG_ 849 RCM_infoUsageID 1;
BA_ "Confidence" SG_ 849 RCM_infoApplicationCRC 1;
BA_ "Confidence" SG_ 849 RCM_infoBootUdsProtoVersion 1;
BA_ "Confidence" SG_ 849 RCM_infoBootloaderCRC 1;
BA_ "Confidence" SG_ 849 RCM_infoAlgoCalID 1;
BA_ "Confidence" SG_ 849 RCM_infoVariantCRC 1;
BA_ "Confidence" SG_ 2032 RCM_nearDeployRear 1;
BA_ "Confidence" SG_ 2032 RCM_nearDeployRight 1;
BA_ "Confidence" SG_ 2032 RCM_nearDeployLeft 1;
BA_ "Confidence" SG_ 2032 RCM_nearDeployFront 1;
BA_ "Confidence" SG_ 2032 RCM_nearDeployRollover 1;
BA_ "Confidence" SG_ 2032 RCM_crashAlgoWakeup 1;
BA_ "Confidence" SG_ 529 RCM_armStatus 1;
BA_ "Confidence" SG_ 529 RCM_warningIndicatorState 1;
BA_ "Confidence" SG_ 529 RCM_passAirbagIndicatorRequest 1;
BA_ "Confidence" SG_ 529 RCM_airbagCutoffStatus 1;
BA_ "Confidence" SG_ 529 RCM_alrSwitchStatus 1;
BA_ "Confidence" SG_ 529 RCM_vinLearnFlag 1;
BA_ "Confidence" SG_ 529 RCM_seatTrackPositionDrvr 1;
BA_ "Confidence" SG_ 529 RCM_seatTrackPositionPass 1;
BA_ "Confidence" SG_ 529 RCM_edr1State 1;
BA_ "Confidence" SG_ 529 RCM_edr2State 1;
BA_ "Confidence" SG_ 529 RCM_keepPowerReason 1;
BA_ "Confidence" SG_ 529 RCM_imuOffsetLearnState 1;
BA_ "Confidence" SG_ 529 RCM_edr3State 1;
BA_ "Confidence" SG_ 529 RCM_driverOrientationInitStatus 1;
BA_ "Confidence" SG_ 529 RCM_occupantClassificationSource 1;
BA_ "Confidence" SG_ 529 RCM_pedProEDR1State 1;
BA_ "Confidence" SG_ 529 RCM_pedProEDR2State 1;
BA_ "SystemSignalLongSymbol" SG_ 998 RCU_a033_VCFRONTLVPowerStateChec "RCU_a033_VCFRONTLVPowerStateChecksum";
BA_ "SystemSignalLongSymbol" SG_ 998 RCU_a034_VCFRONTLVPowerStateCoun "RCU_a034_VCFRONTLVPowerStateCounter";
BA_ "SystemSignalLongSymbol" SG_ 998 RCU_a037_IDBinputRodStrokeInvali "RCU_a037_IDBinputRodStrokeInvalid";
BA_ "SystemSignalLongSymbol" SG_ 998 RCU_a043_VCFRONTiBoosterLvStateI "RCU_a043_VCFRONTiBoosterLvStateInvalid";
BA_ "SystemSignalLongSymbol" SG_ 998 RCU_a055_IDBsimulatorPressFaulte "RCU_a055_IDBsimulatorPressFaulted";
BA_ "SystemSignalLongSymbol" SG_ 998 RCU_a056_redundantControllerIsMa "RCU_a056_redundantControllerIsMaster";
BA_ "SystemSignalLongSymbol" SG_ 998 RCU_a057_DASredundantBrakingCont "RCU_a057_DASredundantBrakingControlDLC";
BA_ "SystemSignalLongSymbol" SG_ 998 RCU_a058_DASredundantBrakingCont "RCU_a058_DASredundantBrakingControlCounter";
BA_ "SystemSignalLongSymbol" SG_ 998 RCU_a059_DASredundantBrakingCont "RCU_a059_DASredundantBrakingControlChecksum";
BA_ "SystemSignalLongSymbol" SG_ 998 RCU_a060_DASbrakeTorqueCommandIn "RCU_a060_DASbrakeTorqueCommandInvalid";
BA_ "SystemSignalLongSymbol" SG_ 998 RCU_a064_ESPredundantBrakingStat "RCU_a064_ESPredundantBrakingStatusDLC";
BA_ "SystemSignalLongSymbol" SG_ 998 RCU_a065_ESPredundantBrakingStat "RCU_a065_ESPredundantBrakingStatusCounter";
BA_ "SystemSignalLongSymbol" SG_ 998 RCU_a066_ESPredundantBrakingStat "RCU_a066_ESPredundantBrakingStatusChecksum";
BA_ "SystemSignalLongSymbol" SG_ 1344 SCCM_a121_turnIndicatorStalkAngl "SCCM_a121_turnIndicatorStalkAngle";
BA_ "SystemSignalLongSymbol" SG_ 1344 SCCM_a123_turnIndicatorStalkAngl "SCCM_a123_turnIndicatorStalkAngle";
BA_ "SystemSignalLongSymbol" SG_ 1344 SCCM_a124_turnIndicatorStalkAngl "SCCM_a124_turnIndicatorStalkAngle";
BA_ "SystemSignalLongSymbol" SG_ 1344 SCCM_a125_turnIndicatorVectorAng "SCCM_a125_turnIndicatorVectorAngle";
BA_ "SystemSignalLongSymbol" SG_ 1344 SCCM_a126_turnIndicatorXVectorOu "SCCM_a126_turnIndicatorXVectorOutOfRange";
BA_ "SystemSignalLongSymbol" SG_ 1344 SCCM_a126_turnIndicatorYVectorOu "SCCM_a126_turnIndicatorYVectorOutOfRange";
BA_ "SystemSignalLongSymbol" SG_ 1344 SCCM_a126_turnIndicatorZVectorOu "SCCM_a126_turnIndicatorZVectorOutOfRange";
BA_ "SystemSignalLongSymbol" SG_ 1344 SCCM_a126_turnIndicatorResu_0001 "SCCM_a126_turnIndicatorResultantOutOfRange";
BA_ "SystemSignalLongSymbol" SG_ 1344 SCCM_a126_turnIndicatorXMagnitud "SCCM_a126_turnIndicatorXMagnitude";
BA_ "SystemSignalLongSymbol" SG_ 1344 SCCM_a126_turnIndicatorYMagnitud "SCCM_a126_turnIndicatorYMagnitude";
BA_ "SystemSignalLongSymbol" SG_ 1344 SCCM_a126_turnIndicatorZMagnitud "SCCM_a126_turnIndicatorZMagnitude";
BA_ "SystemSignalLongSymbol" SG_ 1344 SCCM_a126_turnIndicatorResultant "SCCM_a126_turnIndicatorResultantMagnitude";
BA_ "SystemSignalLongSymbol" SG_ 1359 SCCM_a026_parkButtonInvalidSigna "SCCM_a026_parkButtonInvalidSignal";
BA_ "SystemSignalLongSymbol" SG_ 1359 SCCM_a028_parkButtonShortToGroun "SCCM_a028_parkButtonShortToGround";
BA_ "SystemSignalLongSymbol" SG_ 1359 SCCM_a121_turnIndicatorAngleInva "SCCM_a121_turnIndicatorAngleInvalid";
BA_ "SystemSignalLongSymbol" SG_ 1359 SCCM_a122_turnIndicatorSpeedInva "SCCM_a122_turnIndicatorSpeedInvalid";
BA_ "SystemSignalLongSymbol" SG_ 1359 SCCM_a123_turnIndicatorStuckActi "SCCM_a123_turnIndicatorStuckActive";
BA_ "SystemSignalLongSymbol" SG_ 1359 SCCM_a124_turnIndicatorIdleInval "SCCM_a124_turnIndicatorIdleInvalid";
BA_ "SystemSignalLongSymbol" SG_ 1359 SCCM_a125_turnIndicatorHallAngle "SCCM_a125_turnIndicatorHallAngleMismatch";
BA_ "SystemSignalLongSymbol" SG_ 1359 SCCM_a126_turnIndicatorHallMagOu "SCCM_a126_turnIndicatorHallMagOutOfRange";
BA_ "Confidence" SG_ 816 SCCM_infoBuildType 1;
BA_ "Confidence" SG_ 585 SCCM_highBeamStalkStatus 1;
BA_ "Confidence" SG_ 585 SCCM_washWipeButtonStatus 1;
BA_ "Confidence" SG_ 585 SCCM_turnIndicatorStalkStatus 1;
BA_ "Confidence" SG_ 585 SCCM_turnIndicatorStalkAngle 1;
BA_ "Confidence" SG_ 553 SCCM_rightStalkStatus 1;
BA_ "Confidence" SG_ 553 SCCM_parkButtonStatus 1;
BA_ "Confidence" SG_ 297 SCCM_steeringAngleCounter 1;
BA_ "Confidence" SG_ 297 SCCM_steeringAngleSensorStatus 1;
BA_ "Confidence" SG_ 297 SCCM_steeringAngle 1;
BA_ "Confidence" SG_ 297 SCCM_steeringAngleValidity 1;
BA_ "Confidence" SG_ 297 SCCM_steeringAngleSpeed 1;
BA_ "SystemSignalLongSymbol" SG_ 1531 SDCR_a006_triggerReason_faultCur "SDCR_a006_triggerReason_faultCurrents";
BA_ "SystemSignalLongSymbol" SG_ 1531 SDCR_a006_triggerReason_hvBadAtS "SDCR_a006_triggerReason_hvBadAtSpeed";
BA_ "SystemSignalLongSymbol" SG_ 1531 SDCR_a006_triggerReason_highBack "SDCR_a006_triggerReason_highBackEMF";
BA_ "SystemSignalLongSymbol" SG_ 1531 SDCR_a006_hvPowerNotGoodQualifie "SDCR_a006_hvPowerNotGoodQualified";
BA_ "SystemSignalLongSymbol" SG_ 1531 SDCR_a007_faultReason_faultCurre "SDCR_a007_faultReason_faultCurrentsAtSpeed";
BA_ "SystemSignalLongSymbol" SG_ 1531 SDCR_a007_faultReason_unmitigate "SDCR_a007_faultReason_unmitigatedUCR";
BA_ "SystemSignalLongSymbol" SG_ 1531 SDCR_a007_faultReason_propagatin "SDCR_a007_faultReason_propagating3PS";
BA_ "SystemSignalLongSymbol" SG_ 1531 SDCR_a015_reason_vPhaseShortedLo "SDCR_a015_reason_vPhaseShortedLow";
BA_ "SystemSignalLongSymbol" SG_ 1531 SDCR_a015_reason_vPhaseShortedHi "SDCR_a015_reason_vPhaseShortedHigh";
BA_ "SystemSignalLongSymbol" SG_ 1531 SDCR_a018_triggerReason_faultCur "SDCR_a018_triggerReason_faultCurrents";
BA_ "SystemSignalLongSymbol" SG_ 1531 SDCR_a018_triggerReason_hvBadAtS "SDCR_a018_triggerReason_hvBadAtSpeed";
BA_ "SystemSignalLongSymbol" SG_ 1531 SDCR_a018_triggerReason_highBack "SDCR_a018_triggerReason_highBackEMF";
BA_ "SystemSignalLongSymbol" SG_ 1531 SDCR_a018_hvPowerNotGoodQualifie "SDCR_a018_hvPowerNotGoodQualified";
BA_ "SystemSignalLongSymbol" SG_ 1531 SDCR_a019_faultReason_faultCurre "SDCR_a019_faultReason_faultCurrentsAtSpeed";
BA_ "SystemSignalLongSymbol" SG_ 1531 SDCR_a019_faultReason_unmitigate "SDCR_a019_faultReason_unmitigatedUCR";
BA_ "SystemSignalLongSymbol" SG_ 1531 SDCR_a019_faultReason_propagatin "SDCR_a019_faultReason_propagating3PS";
BA_ "SystemSignalLongSymbol" SG_ 1467 SDCR_a004_pmRunningFdbkIrrationa "SDCR_a004_pmRunningFdbkIrrational";
BA_ "SystemSignalLongSymbol" SG_ 1467 SDCR_a019_historicalFaultCurrent "SDCR_a019_historicalFaultCurrents";
BA_ "SystemSignalLongSymbol" SG_ 1467 SDCR_a025_diSwitchingFdbkIrratio "SDCR_a025_diSwitchingFdbkIrrational";
BA_ "SystemSignalLongSymbol" SG_ 1467 SDCR_a026_faultCurrentMonitoring "SDCR_a026_faultCurrentMonitoringDisabled";
BA_ "Confidence" SG_ 1597 SDCR_infoBuildType 1;
BA_ "SystemSignalLongSymbol" SG_ 1835 TAS_a098_VCFRONT_LVPowerState_MI "TAS_a098_VCFRONT_LVPowerState_MIA";
BA_ "SystemSignalLongSymbol" SG_ 1835 TAS_a098_VCFRONT_systemStatus_MI "TAS_a098_VCFRONT_systemStatus_MIA";
BA_ "SystemSignalLongSymbol" SG_ 1835 TAS_a099_UI_driverAssistMapData_ "TAS_a099_UI_driverAssistMapData_MIA";
BA_ "SystemSignalLongSymbol" SG_ 1835 TAS_a099_UI_suspensionControl_MI "TAS_a099_UI_suspensionControl_MIA";
VAL_ 17 RCM_collisionRear 3 "RCM_COLLISION_EVENT_SNA" 1 "RCM_COLLISION_EVENT_ACTIVE" 0 "RCM_COLLISION_EVENT_INACTIVE" ;
VAL_ 17 RCM_collisionRight 3 "RCM_COLLISION_EVENT_SNA" 1 "RCM_COLLISION_EVENT_ACTIVE" 0 "RCM_COLLISION_EVENT_INACTIVE" ;
VAL_ 17 RCM_collisionLeft 3 "RCM_COLLISION_EVENT_SNA" 1 "RCM_COLLISION_EVENT_ACTIVE" 0 "RCM_COLLISION_EVENT_INACTIVE" ;
VAL_ 17 RCM_collisionFront 3 "RCM_COLLISION_EVENT_SNA" 1 "RCM_COLLISION_EVENT_ACTIVE" 0 "RCM_COLLISION_EVENT_INACTIVE" ;
VAL_ 17 RCM_collisionRollover 3 "RCM_COLLISION_EVENT_SNA" 1 "RCM_COLLISION_EVENT_ACTIVE" 0 "RCM_COLLISION_EVENT_INACTIVE" ;
VAL_ 17 RCM_collisionPedPro 3 "RCM_COLLISION_EVENT_SNA" 1 "RCM_COLLISION_EVENT_ACTIVE" 0 "RCM_COLLISION_EVENT_INACTIVE" ;
VAL_ 17 RCM_collisionSeverity 3 "RCM_COLLISION_SEVERITY_PEDPRO_EVENT" 2 "RCM_COLLISION_SEVERITY_SECOND_STAGE" 1 "RCM_COLLISION_SEVERITY_FIRST_STAGE" 0 "RCM_COLLISION_SEVERITY_PRETENSIONER" ;
VAL_ 257 RCM_rollRateQF 3 "FAULTED" 2 "TEMP_INVALID" 1 "VALID" 0 "INIT" ;
VAL_ 257 RCM_yawRateQF 1 "NOT_FAULTED" 0 "FAULTED" ;
VAL_ 257 RCM_pitchRateQF 3 "FAULTED" 2 "TEMP_INVALID" 1 "VALID" 0 "INIT" ;
VAL_ 278 RCM_longitudinalAccelQF 1 "NOT_FAULTED" 0 "FAULTED" ;
VAL_ 278 RCM_lateralAccelQF 1 "NOT_FAULTED" 0 "FAULTED" ;
VAL_ 278 RCM_verticalAccelQF 1 "NOT_FAULTED" 0 "FAULTED" ;
VAL_ 278 RCM_CGTranslationFault 1 "RCM_COG_TRANSLATION_FAULTED" 0 "RCM_COG_TRANSLATION_NOT_FAULTED" ;
VAL_ 849 RCM_infoBuildType 4 "INFO_MFG_BUILD" 3 "INFO_TRACEABLE_CI_BUILD" 2 "INFO_LOCAL_BUILD" 1 "INFO_PLATFORM_BUILD" 0 "INFO_UNKNOWN_BUILD" ;
VAL_ 2032 RCM_nearDeployRear 3 "RCM_NEAR_DEPLOY_EVENT_SNA" 1 "RCM_NEAR_DEPLOY_EVENT_ACTIVE" 0 "RCM_NEAR_DEPLOY_EVENT_INACTIVE" ;
VAL_ 2032 RCM_nearDeployRight 3 "RCM_NEAR_DEPLOY_EVENT_SNA" 1 "RCM_NEAR_DEPLOY_EVENT_ACTIVE" 0 "RCM_NEAR_DEPLOY_EVENT_INACTIVE" ;
VAL_ 2032 RCM_nearDeployLeft 3 "RCM_NEAR_DEPLOY_EVENT_SNA" 1 "RCM_NEAR_DEPLOY_EVENT_ACTIVE" 0 "RCM_NEAR_DEPLOY_EVENT_INACTIVE" ;
VAL_ 2032 RCM_nearDeployFront 3 "RCM_NEAR_DEPLOY_EVENT_SNA" 1 "RCM_NEAR_DEPLOY_EVENT_ACTIVE" 0 "RCM_NEAR_DEPLOY_EVENT_INACTIVE" ;
VAL_ 2032 RCM_nearDeployRollover 3 "RCM_NEAR_DEPLOY_EVENT_SNA" 1 "RCM_NEAR_DEPLOY_EVENT_ACTIVE" 0 "RCM_NEAR_DEPLOY_EVENT_INACTIVE" ;
VAL_ 2032 RCM_crashAlgoWakeup 3 "RCM_CRASH_ALGO_WAKEUP_EVENT_SNA" 1 "RCM_CRASH_ALGO_WAKEUP_EVENT_ACTIVE" 0 "RCM_CRASH_ALGO_WAKEUP_EVENT_INACTIVE" ;
VAL_ 529 RCM_armStatus 2 "ARMED_WITH_NOFIRE_CAL" 1 "RCM_ARMED" 0 "RCM_UNARMED" ;
VAL_ 529 RCM_warningIndicatorState 1 "RCM_WARNING_INDICATOR_ON" 0 "RCM_WARNING_INDICATOR_OFF" ;
VAL_ 529 RCM_passAirbagIndicatorRequest 1 "RCM_PASSENGER_AIRBAG_INDICATOR_OFF" 0 "RCM_PASSENGER_AIRBAG_INDICATOR_ON" ;
VAL_ 529 RCM_airbagCutoffStatus 1 "RCM_PASSENGER_AIRBAG_DISABLED" 0 "RCM_PASSENGER_AIRBAG_ENABLED" ;
VAL_ 529 RCM_alrSwitchStatus 2 "RCM_ALR_FAULTED" 1 "RCM_ALR_ENGAGED" 0 "RCM_ALR_NOT_ENGAGED" ;
VAL_ 529 RCM_vinLearnFlag 2 "RCM_VIN_STORED_MISMATCH" 1 "RCM_VIN_STORED" 0 "RCM_VIN_NOT_STORED" ;
VAL_ 529 RCM_seatTrackPositionDrvr 2 "RCM_SEAT_POSITION_FAULTED" 1 "RCM_SEAT_POSITION_FAR" 0 "RCM_SEAT_POSITION_NEAR" ;
VAL_ 529 RCM_seatTrackPositionPass 2 "RCM_SEAT_POSITION_FAULTED" 1 "RCM_SEAT_POSITION_FAR" 0 "RCM_SEAT_POSITION_NEAR" ;
VAL_ 529 RCM_edr1State 3 "RCM_EDR_UNAVAILABLE" 2 "RCM_EDR_LOCKED" 1 "RCM_EDR_STORED" 0 "RCM_EDR_EMPTY" ;
VAL_ 529 RCM_edr2State 3 "RCM_EDR_UNAVAILABLE" 2 "RCM_EDR_LOCKED" 1 "RCM_EDR_STORED" 0 "RCM_EDR_EMPTY" ;
VAL_ 529 RCM_keepPowerReason 8 "RCM_KEEP_POWER_REASON_SNA" 7 "RCM_INVALID_POWER_OFF_REQUEST" 6 "RCM_INITIALIZATION_PHASE" 5 "RCM_CANNOT_POWER_DOWN" 4 "RCM_EDR_UPLOADING" 3 "RCM_EDR_STORING_TO_EEPROM" 2 "RCM_CRASH_ALGO_ACTIVE" 1 "RCM_IN_IDLE_MODE" 0 "RCM_NO_KEEP_POWER_REQUEST" ;
VAL_ 529 RCM_imuOffsetLearnState 3 "IMU_OFFSETS_UNABLE_TO_LEARN" 2 "IMU_FAST_LEARNING_TIME" 1 "IMU_SLOW_LEARNING_DISTANCE" 0 "IMU_OFFSET_LEARNING_OFF" ;
VAL_ 529 RCM_edr3State 3 "RCM_EDR_UNAVAILABLE" 2 "RCM_EDR_LOCKED" 1 "RCM_EDR_STORED" 0 "RCM_EDR_EMPTY" ;
VAL_ 529 RCM_driverOrientationInitStatus 4 "RCM_DRIVER_ORIENTATION_MISMATCH_DEFAULT_RHD" 3 "RCM_DRIVER_ORIENTATION_MISMATCH_DEFAULT_LHD" 2 "RCM_DRIVER_ORIENTATION_MATCHED_RHD" 1 "RCM_DRIVER_ORIENTATION_MATCHED_LHD" 0 "RCM_DRIVER_ORIENTATION_INIT_NOT_COMPLETE" ;
VAL_ 529 RCM_occupantClassificationSource 1 "VCRIGHT_CLASSIFICATION_SOURCE" 0 "OCS1P_CLASSIFICATION_SOURCE" ;
VAL_ 529 RCM_pedProEDR1State 3 "RCM_EDR_UNAVAILABLE" 2 "RCM_EDR_LOCKED" 1 "RCM_EDR_STORED" 0 "RCM_EDR_EMPTY" ;
VAL_ 529 RCM_pedProEDR2State 3 "RCM_EDR_UNAVAILABLE" 2 "RCM_EDR_LOCKED" 1 "RCM_EDR_STORED" 0 "RCM_EDR_EMPTY" ;
VAL_ 816 SCCM_infoBuildType 4 "INFO_MFG_BUILD" 3 "INFO_TRACEABLE_CI_BUILD" 2 "INFO_LOCAL_BUILD" 1 "INFO_PLATFORM_BUILD" 0 "INFO_UNKNOWN_BUILD" ;
VAL_ 585 SCCM_highBeamStalkStatus 2 "PUSH" 1 "PULL" 0 "IDLE" ;
VAL_ 585 SCCM_washWipeButtonStatus 2 "2ND_DETENT" 1 "1ST_DETENT" 0 "NOT_PRESSED" ;
VAL_ 585 SCCM_turnIndicatorStalkStatus 8 "DOWN_2" 7 "DOWN_1_5" 6 "DOWN_1" 5 "DOWN_0_5" 4 "UP_2" 3 "UP_1_5" 2 "UP_1" 1 "UP_0_5" 0 "IDLE" ;
VAL_ 553 SCCM_rightStalkStatus 5 "INIT" 4 "DOWN_2" 3 "DOWN_1" 2 "UP_2" 1 "UP_1" 0 "IDLE" ;
VAL_ 553 SCCM_parkButtonStatus 2 "INIT" 1 "PRESSED" 0 "NOT_PRESSED" ;
VAL_ 297 SCCM_steeringAngleSensorStatus 3 "ERROR_INIT" 2 "ERROR" 1 "INIT" 0 "OK" ;
VAL_ 297 SCCM_steeringAngleValidity 2 "INIT" 1 "VALID" 0 "INVALID" ;
VAL_ 1597 SDCR_infoBuildType 4 "INFO_MFG_BUILD" 3 "INFO_TRACEABLE_CI_BUILD" 2 "INFO_LOCAL_BUILD" 1 "INFO_PLATFORM_BUILD" 0 "INFO_UNKNOWN_BUILD" ;
